VERSION "dbc-export 1 2025.20.8"

NS_ :

BS_:

BU_: ADSP APSB BB BMS CMP CP DAS DI DIF DIR DPB EPASTP EPASTS GTW ICR IDB OCS1P PM PMF PMR PTC RCM RCU TCU UI UIS VCLEFT VCSEC

BO_ 2047 GTW_carConfig: 8 GTW
 SG_ GTW_carConfigMultiplexer M : 0|8@1+ (1,0) [0|255] "" Vector__XXX
 SG_ GTW_deliveryStatus m1 : 8|1@1+ (1,0) [0|1] "" Vector__XXX
 SG_ GTW_cabinPTCHeaterType m1 : 10|1@1+ (1,0) [0|1] "" Vector__XXX
 SG_ GTW_rightHandDrive m1 : 11|1@1+ (1,0) [0|1] "" Vector__XXX
 SG_ GTW_rearLightType m1 : 12|2@1+ (1,0) [0|3] "" Vector__XXX
 SG_ GTW_headlamps m1 : 14|2@1+ (1,0) [0|3] "" Vector__XXX
 SG_ GTW_country m1 : 16|16@1+ (1,0) [0|65535] "" Vector__XXX
 SG_ GTW_tireType m1 : 32|6@1+ (1,0) [0|63] "" Vector__XXX
 SG_ GTW_roofGlassType m1 : 38|2@1+ (1,0) [0|3] "" Vector__XXX
 SG_ GTW_dasHw m1 : 40|3@1+ (1,0) [3|5] "" Vector__XXX
 SG_ GTW_brakeHWType m1 : 43|5@1+ (1,0) [0|31] "" Vector__XXX
 SG_ GTW_restraintsHardwareType m1 : 48|8@1+ (1,0) [0|255] "" Vector__XXX
 SG_ GTW_drivetrainType m1 : 56|4@1+ (1,0) [0|4] "" Vector__XXX
 SG_ GTW_radarHeaterType m1 : 60|3@1+ (1,0) [0|5] "" Vector__XXX
 SG_ GTW_exteriorTrimType m2 : 8|1@1+ (1,0) [0|1] "" Vector__XXX
 SG_ GTW_frontSeatHeaters m2 : 9|1@1+ (1,0) [0|1] "" Vector__XXX
 SG_ GTW_rearSeatHeaters m2 : 10|1@1+ (1,0) [0|1] "" Vector__XXX
 SG_ GTW_eCallAntennaHW m2 : 12|1@1+ (1,0) [0|1] "" Vector__XXX
 SG_ GTW_homelinkType m2 : 13|1@1+ (1,0) [0|1] "" Vector__XXX
 SG_ GTW_vdcType m2 : 14|1@1+ (1,0) [0|1] "" Vector__XXX
 SG_ GTW_memoryMirrors m2 : 17|1@1+ (1,0) [0|1] "" Vector__XXX
 SG_ GTW_powerLiftgateType m2 : 18|2@1+ (1,0) [0|2] "" Vector__XXX
 SG_ GTW_lumbarECUType m2 : 20|4@1+ (1,0) [0|15] "" Vector__XXX
 SG_ GTW_rearSeatHeaterType m2 : 24|2@1+ (1,0) [0|3] "" Vector__XXX
 SG_ GTW_auxParkLamps m2 : 26|2@1+ (1,0) [0|3] "" Vector__XXX
 SG_ GTW_interiorCabinRadarType m2 : 28|1@1+ (1,0) [0|1] "" Vector__XXX
 SG_ GTW_hvacPanelVaneType m2 : 29|1@1+ (1,0) [0|1] "" Vector__XXX
 SG_ GTW_intakeAirFilterType m2 : 30|2@1+ (1,0) [0|2] "" Vector__XXX
 SG_ GTW_eBuckConfig m2 : 32|1@1+ (1,0) [0|1] "" Vector__XXX
 SG_ GTW_steeringHeaterEnabled m2 : 33|1@1+ (1,0) [0|1] "" Vector__XXX
 SG_ GTW_activeHighBeam m2 : 34|1@1+ (1,0) [0|1] "" Vector__XXX
 SG_ GTW_airbagCutoffSwitch m2 : 35|1@1+ (1,0) [0|1] "" Vector__XXX
 SG_ GTW_intrusionSensorType m2 : 36|1@1+ (1,0) [0|1] "" Vector__XXX
 SG_ GTW_spoilerType m2 : 37|1@1+ (1,0) [0|1] "" Vector__XXX
 SG_ GTW_rearFogLamps m2 : 39|1@1+ (1,0) [0|1] "" Vector__XXX
 SG_ GTW_roofType m2 : 40|1@1+ (1,0) [0|1] "" Vector__XXX
 SG_ GTW_thirdRowSeatType m2 : 41|1@1+ (1,0) [0|1] "" Vector__XXX
 SG_ GTW_autopilot m2 : 42|3@1+ (1,0) [0|7] "" Vector__XXX
 SG_ GTW_superchargingAccess m2 : 45|2@1+ (1,0) [0|3] "" Vector__XXX
 SG_ GTW_exteriorColor m2 : 48|5@1+ (1,0) [0|31] "" Vector__XXX
 SG_ GTW_pedestrianWarningSound m2 : 53|2@1+ (1,0) [0|3] "" Vector__XXX
 SG_ GTW_steeringColumnUJointType m2 : 55|1@1+ (1,0) [0|1] "" Vector__XXX
 SG_ GTW_bPillarNFCParam m2 : 56|1@1+ (1,0) [0|1] "" Vector__XXX
 SG_ GTW_interiorLighting m2 : 57|3@1+ (1,0) [0|7] "" Vector__XXX
 SG_ GTW_headlightLevelerType m2 : 60|2@1+ (1,0) [0|3] "" Vector__XXX
 SG_ GTW_numberHVILNodes m2 : 62|2@1+ (1,0) [0|3] "" Vector__XXX
 SG_ GTW_mapRegion m3 : 8|4@1+ (1,0) [0|15] "" Vector__XXX
 SG_ GTW_performancePackage m3 : 12|3@1+ (1,0) [0|7] "" Vector__XXX
 SG_ GTW_chassisType m3 : 18|4@1+ (1,0) [0|15] "" Vector__XXX
 SG_ GTW_airSuspension m3 : 22|2@1+ (1,0) [0|3] "" Vector__XXX
 SG_ GTW_centerConsoleControllerType m3 : 24|2@1+ (1,0) [0|3] "" Vector__XXX
 SG_ GTW_autopilotCameraType m3 : 26|1@1+ (1,0) [0|1] "" Vector__XXX
 SG_ GTW_connectivityPackage m3 : 27|1@1+ (1,0) [0|1] "" Vector__XXX
 SG_ GTW_plcSupportType m3 : 28|2@1+ (1,0) [0|3] "" Vector__XXX
 SG_ GTW_packEnergy m3 : 32|5@1+ (1,0) [0|31] "" Vector__XXX
 SG_ GTW_frontSeatReclinerHardware m3 : 37|2@1+ (1,0) [0|3] "" Vector__XXX
 SG_ GTW_brakeLineSwitchType m3 : 39|1@1+ (1,0) [0|1] "" Vector__XXX
 SG_ GTW_espValveType m3 : 40|2@1+ (1,0) [0|3] "" Vector__XXX
 SG_ GTW_softRange m3 : 42|3@1+ (1,0) [0|7] "" Vector__XXX
 SG_ GTW_refrigerantType m3 : 45|2@1+ (1,0) [0|3] "" Vector__XXX
 SG_ GTW_wheelType m3 : 48|7@1+ (1,0) [0|127] "" Vector__XXX
 SG_ GTW_ptcControlMode m3 : 55|2@1+ (1,0) [0|3] "" Vector__XXX
 SG_ GTW_brakeActuationType m3 : 57|3@1+ (1,0) [0|4] "" Vector__XXX
 SG_ GTW_secondRowSeatType m3 : 60|3@1+ (1,0) [0|7] "" Vector__XXX
 SG_ GTW_secondRowSeatMotorType m3 : 63|1@1+ (1,0) [0|1] "" Vector__XXX
 SG_ GTW_birthday m4 : 8|32@1+ (1,0) [0|4294967295] "" Vector__XXX
 SG_ GTW_eCallEnabled m4 : 40|2@1+ (1,0) [0|3] "" Vector__XXX
 SG_ GTW_parkAssistECUType m4 : 42|2@1+ (1,0) [0|3] "" Vector__XXX
 SG_ GTW_passengerAirbagType m4 : 44|2@1+ (1,0) [0|3] "" Vector__XXX
 SG_ GTW_forwardRadarHw m4 : 46|2@1+ (1,0) [0|2] "" Vector__XXX
 SG_ GTW_frontSeatType m4 : 48|4@1+ (1,0) [0|15] "" Vector__XXX
 SG_ GTW_secondRowDisplayType m4 : 52|1@1+ (1,0) [0|1] "" Vector__XXX
 SG_ GTW_wirelessPhoneChargerType m4 : 53|2@1+ (1,0) [0|3] "" Vector__XXX
 SG_ GTW_ethernetTunerType m4 : 55|2@1+ (1,0) [0|3] "" Vector__XXX
 SG_ GTW_interiorTrimType m4 : 60|4@1+ (1,0) [0|15] "" Vector__XXX
 SG_ GTW_gloveboxUSBType m5 : 8|2@1+ (1,0) [0|3] "" Vector__XXX
 SG_ GTW_coolantPumpType m5 : 10|3@1+ (1,0) [0|7] "" Vector__XXX
 SG_ GTW_epblHwType m5 : 13|4@1+ (1,0) [0|15] "" Vector__XXX
 SG_ GTW_epbrHwType m5 : 17|4@1+ (1,0) [0|15] "" Vector__XXX
 SG_ GTW_blowerMotorType m5 : 21|2@1+ (1,0) [0|3] "" Vector__XXX
 SG_ GTW_rearLeftBLEEndpointParameter m5 : 23|1@1+ (1,0) [0|1] "" Vector__XXX
 SG_ GTW_frontUsbHubType m5 : 27|3@1+ (1,0) [0|5] "" Vector__XXX
 SG_ GTW_superManifoldType m5 : 30|2@1+ (1,0) [0|3] "" Vector__XXX
 SG_ GTW_rcmLocation m5 : 32|1@1+ (1,0) [0|1] "" Vector__XXX
 SG_ GTW_interiorCamFanType m5 : 33|2@1+ (1,0) [0|3] "" Vector__XXX
 SG_ GTW_interiorCamBeautyCoverType m5 : 35|2@1+ (1,0) [0|3] "" Vector__XXX
 SG_ GTW_sirenType m5 : 37|1@1+ (1,0) [0|1] "" Vector__XXX
 SG_ GTW_hornType m5 : 38|1@1+ (1,0) [0|1] "" Vector__XXX
 SG_ GTW_badgingVersion m5 : 40|1@1+ (1,0) [0|1] "" Vector__XXX
 SG_ GTW_steeringColumnMotorType m5 : 42|2@1+ (1,0) [0|3] "" Vector__XXX
 SG_ GTW_refrigACLineType m5 : 48|2@1+ (1,0) [0|3] "" Vector__XXX
 SG_ GTW_refrigFilterType m5 : 50|2@1+ (1,0) [0|3] "" Vector__XXX
 SG_ GTW_diBurnInType m5 : 52|1@1+ (1,0) [0|1] "" Vector__XXX
 SG_ GTW_specialBadgingType m5 : 53|2@1+ (1,0) [0|3] "" Vector__XXX
 SG_ GTW_chassisSubType m5 : 55|2@1+ (1,0) [0|3] "" Vector__XXX
 SG_ GTW_frontSeatVentilationType m5 : 57|1@1+ (1,0) [0|1] "" Vector__XXX
 SG_ GTW_towPackage m5 : 58|2@1+ (1,0) [0|3] "" Vector__XXX
 SG_ GTW_refrigLccType m5 : 60|1@1+ (1,0) [0|1] "" Vector__XXX
 SG_ GTW_caliperColorType m5 : 62|2@1+ (1,0) [0|3] "" Vector__XXX
 SG_ GTW_wiperMotorType m6 : 9|1@1+ (1,0) [0|1] "" Vector__XXX
 SG_ GTW_frontOverheadConsoleType m6 : 10|2@1+ (1,0) [0|3] "" Vector__XXX
 SG_ GTW_shifterType m6 : 12|1@1+ (1,0) [0|1] "" Vector__XXX
 SG_ GTW_compressorType m6 : 13|4@1+ (1,0) [0|15] "" Vector__XXX
 SG_ GTW_twelveVBatteryType m6 : 17|3@1+ (1,0) [0|7] "" Vector__XXX
 SG_ GTW_efuseSWConfig m6 : 20|3@1+ (1,0) [0|7] "" Vector__XXX
 SG_ GTW_tollCollectionModuleType m6 : 23|1@1+ (1,0) [0|1] "" Vector__XXX
 SG_ GTW_bleEndpointUpdateMethod m6 : 24|1@1+ (1,0) [0|1] "" Vector__XXX
 SG_ GTW_steeringWheelControllerType m6 : 25|3@1+ (1,0) [0|7] "" Vector__XXX
 SG_ GTW_frontSeatVentilationEnabled m6 : 28|1@1+ (1,0) [0|1] "" Vector__XXX
 SG_ GTW_gloveboxActuatorType m6 : 29|2@1+ (1,0) [0|3] "" Vector__XXX
 SG_ GTW_epasType m6 : 32|4@1+ (1,0) [0|11] "" Vector__XXX
 SG_ GTW_homologationRegionOverride m6 : 36|2@1+ (1,0) [0|3] "" Vector__XXX
 SG_ GTW_windowCommandsPermissionType m6 : 38|2@1+ (1,0) [0|3] "" Vector__XXX
 SG_ GTW_headlightStepperStallDetectM m6 : 42|1@1+ (1,0) [0|1] "" Vector__XXX
 SG_ GTW_rgbInteriorLightingEnabled m6 : 43|2@1+ (1,0) [0|3] "" Vector__XXX
 SG_ GTW_windshieldWiperHeaterType m6 : 45|1@1+ (1,0) [0|1] "" Vector__XXX
 SG_ GTW_driveInterfaceType m6 : 47|1@1+ (1,0) [0|1] "" Vector__XXX
 SG_ GTW_efficiencyPackage m6 : 49|6@1+ (1,0) [0|63] "" Vector__XXX
 SG_ GTW_visorLightType m6 : 55|1@1+ (1,0) [0|1] "" Vector__XXX
 SG_ GTW_gnssAntennaType m6 : 58|2@1+ (1,0) [0|3] "" Vector__XXX
 SG_ GTW_frontSeatHeatersEnabled m6 : 62|1@1+ (1,0) [0|1] "" Vector__XXX
 SG_ GTW_windshieldWiperHeaterEnabled m6 : 63|1@1+ (1,0) [0|1] "" Vector__XXX
 SG_ GTW_tcuType m7 : 8|1@1+ (1,0) [0|1] "" Vector__XXX
 SG_ GTW_fasciaType m7 : 9|4@1+ (1,0) [0|15] "" Vector__XXX
 SG_ GTW_powerSteeringColumn m7 : 13|1@1+ (1,0) [0|1] "" Vector__XXX
 SG_ GTW_frontSeatHeaterType m7 : 14|1@1+ (1,0) [0|1] "" Vector__XXX
 SG_ GTW_softPerformanceLimit m7 : 15|4@1+ (1,0) [0|15] "" Vector__XXX
 SG_ GTW_alcoholInterlockType m7 : 22|1@1+ (1,0) [0|1] "" Vector__XXX
 SG_ GTW_immersiveAudio m7 : 23|2@1+ (1,0) [0|3] "" Vector__XXX
 SG_ GTW_passengerOccupancySensorType m7 : 26|3@1+ (1,0) [0|7] "" Vector__XXX
 SG_ GTW_packPerformanceDeviation m7 : 30|3@1+ (1,0) [0|7] "" Vector__XXX
 SG_ GTW_frontFogLamps m7 : 35|1@1+ (1,0) [0|1] "" Vector__XXX
 SG_ GTW_driverOccupancySensorType m7 : 36|1@1+ (1,0) [0|1] "" Vector__XXX
 SG_ GTW_audioType m7 : 37|3@1+ (1,0) [0|7] "" Vector__XXX
 SG_ GTW_occupancyClassificationFeatu m7 : 42|1@1+ (1,0) [0|1] "" Vector__XXX
 SG_ GTW_domeLightType m7 : 47|2@1+ (1,0) [0|3] "" Vector__XXX
 SG_ GTW_tpmsType m7 : 49|2@1+ (1,0) [0|3] "" Vector__XXX
 SG_ GTW_authenticationEndpointLayout m7 : 52|3@1+ (1,0) [0|6] "" Vector__XXX
 SG_ GTW_socSleepOverride m7 : 57|2@1+ (1,0) [0|3] "" Vector__XXX
 SG_ GTW_r79BehaviorOverride m7 : 59|1@1+ (1,0) [0|1] "" Vector__XXX
 SG_ GTW_steeringHeaterType m7 : 60|3@1+ (1,0) [0|7] "" Vector__XXX
 SG_ GTW_sohRegulatoryStatus m8 : 10|1@1+ (1,0) [0|1] "" Vector__XXX
 SG_ GTW_m3yBusArchitecture m8 : 17|2@1+ (1,0) [0|3] "" Vector__XXX
 SG_ GTW_blindSpotIndicatorLightType m8 : 20|1@1+ (1,0) [0|1] "" Vector__XXX
 SG_ GTW_hvacCaseDoorType m8 : 28|1@1+ (1,0) [0|1] "" Vector__XXX
 SG_ GTW_occupancyDetectionSourceRequ m8 : 29|1@1+ (1,0) [0|1] "" Vector__XXX
 SG_ GTW_rduCableType m8 : 31|1@1+ (1,0) [0|1] "" Vector__XXX
 SG_ GTW_interiorCameraType m8 : 39|2@1+ (1,0) [0|2] "" Vector__XXX
 SG_ GTW_frontFasciaCameraType m8 : 41|2@1+ (1,0) [0|3] "" Vector__XXX

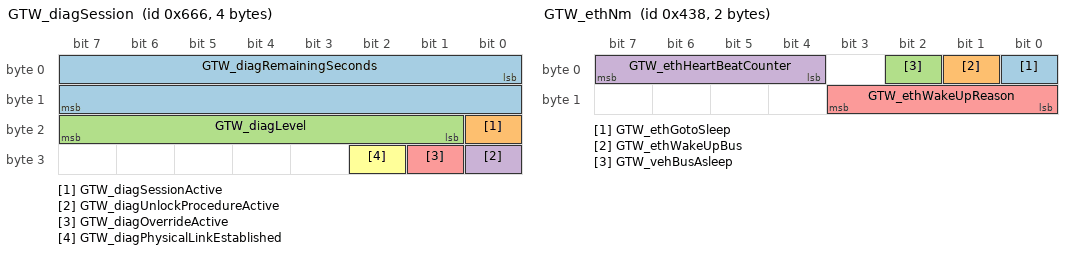
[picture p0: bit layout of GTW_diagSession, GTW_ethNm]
BO_ 1638 GTW_diagSession: 4 GTW
 SG_ GTW_diagRemainingSeconds : 0|16@1+ (1,0) [0|65535] "seconds" Vector__XXX
 SG_ GTW_diagSessionActive : 16|1@1+ (1,0) [0|1] "" Vector__XXX
 SG_ GTW_diagLevel : 17|7@1+ (1,0) [0|127] "" Vector__XXX
 SG_ GTW_diagUnlockProcedureActive : 24|1@1+ (1,0) [0|1] "" Vector__XXX
 SG_ GTW_diagOverrideActive : 25|1@1+ (1,0) [0|1] "" Vector__XXX
 SG_ GTW_diagPhysicalLinkEstablished : 26|1@1+ (1,0) [0|1] "" Vector__XXX

BO_ 1080 GTW_ethNm: 2 GTW
 SG_ GTW_ethGotoSleep : 0|1@1+ (1,0) [0|1] "" Vector__XXX
 SG_ GTW_ethWakeUpBus : 1|1@1+ (1,0) [0|1] "" Vector__XXX
 SG_ GTW_vehBusAsleep : 2|1@1+ (1,0) [0|1] "" Vector__XXX
 SG_ GTW_ethHeartBeatCounter : 4|4@1+ (1,0) [0|15] "" Vector__XXX
 SG_ GTW_ethWakeUpReason : 8|4@1+ (1,0) [0|15] "" Vector__XXX

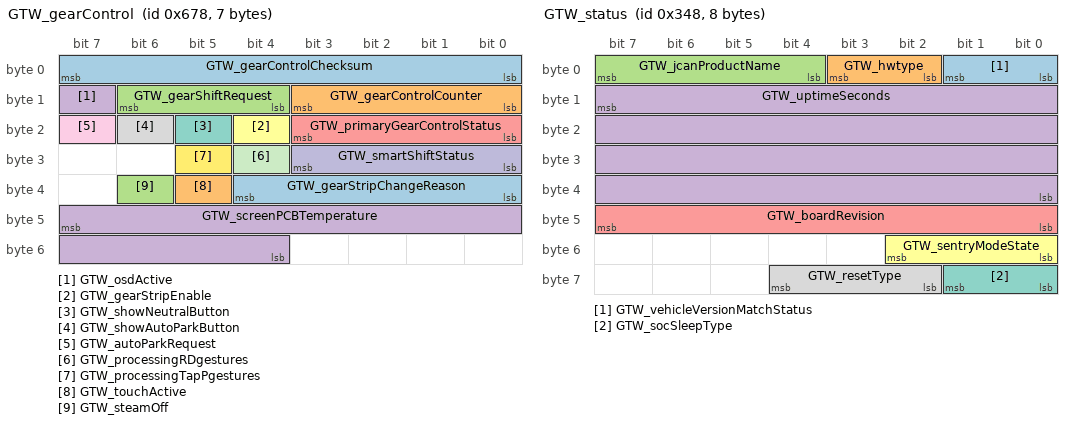
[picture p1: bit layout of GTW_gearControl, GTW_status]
BO_ 1656 GTW_gearControl: 7 GTW
 SG_ GTW_gearControlChecksum : 0|8@1+ (1,0) [0|255] "" Vector__XXX
 SG_ GTW_gearControlCounter : 8|4@1+ (1,0) [0|15] "" Vector__XXX
 SG_ GTW_gearShiftRequest : 12|3@1+ (1,0) [1|7] "" Vector__XXX
 SG_ GTW_osdActive : 15|1@1+ (1,0) [0|1] "" Vector__XXX
 SG_ GTW_primaryGearControlStatus : 16|4@1+ (1,0) [0|15] "" Vector__XXX
 SG_ GTW_gearStripEnable : 20|1@1+ (1,0) [0|1] "" Vector__XXX
 SG_ GTW_showNeutralButton : 21|1@1+ (1,0) [0|1] "" Vector__XXX
 SG_ GTW_showAutoParkButton : 22|1@1+ (1,0) [0|1] "" Vector__XXX
 SG_ GTW_autoParkRequest : 23|1@1+ (1,0) [0|1] "" Vector__XXX
 SG_ GTW_smartShiftStatus : 24|4@1+ (1,0) [1|15] "" Vector__XXX
 SG_ GTW_processingRDgestures : 28|1@1+ (1,0) [0|1] "" Vector__XXX
 SG_ GTW_processingTapPgestures : 29|1@1+ (1,0) [0|1] "" Vector__XXX
 SG_ GTW_gearStripChangeReason : 32|5@1+ (1,0) [1|31] "" Vector__XXX
 SG_ GTW_touchActive : 37|1@1+ (1,0) [0|1] "" Vector__XXX
 SG_ GTW_steamOff : 38|1@1+ (1,0) [0|1] "" Vector__XXX
 SG_ GTW_screenPCBTemperature : 47|12@0- (0.0625,0) [-128|127.875] "degC" Vector__XXX

BO_ 2033 GTW_hrl: 7 GTW
 SG_ GTW_hrlIndex M : 0|2@1+ (1,0) [0|3] "" Vector__XXX
 SG_ GTW_hrlState m2 : 2|1@1+ (1,0) [0|1] "" Vector__XXX
 SG_ GTW_hrlTriggerDuration m2 : 15|16@0+ (1,0) [0|65535] "seconds" Vector__XXX
 SG_ GTW_hrlTriggerType m2 : 24|4@1+ (1,0) [0|15] "" Vector__XXX
 SG_ GTW_hrlTriggerId m2 : 39|16@0+ (1,0) [0|65535] "" Vector__XXX
 SG_ GTW_hrlTriggerBus m2 : 53|3@1+ (1,0) [0|7] "" Vector__XXX

BO_ 60 GTW_info: 8 GTW
 SG_ GTW_infoIndex M : 0|8@1+ (1,0) [0|255] "" Vector__XXX
 SG_ GTW_buildType m10 : 8|3@1+ (1,0) [0|7] "" Vector__XXX
 SG_ GTW_hardwareId m10 : 32|16@1+ (1,0) [0|65535] "" Vector__XXX
 SG_ GTW_platformType m13 : 8|8@1+ (1,0) [0|255] "" Vector__XXX
 SG_ GTW_appCrc m13 : 32|32@1+ (1,0) [0|4294967295] "" Vector__XXX
 SG_ GTW_applicationGitHash m17 : 8|56@1+ (1,0) [0|7.20575940379e+16] "" Vector__XXX
 SG_ GTW_bootGitHash m18 : 8|56@1+ (1,0) [0|7.20575940379e+16] "" Vector__XXX

BO_ 1370 GTW_mismatchFault: 8 GTW
 SG_ GTW_mismatchFaultIndex M : 0|3@1+ (1,0) [0|7] "" Vector__XXX
 SG_ GTW_mismatchFaultChecksum : 3|8@1+ (1,0) [0|255] "" Vector__XXX
 SG_ GTW_mismatchFaultCounter : 11|4@1+ (1,0) [0|15] "" Vector__XXX
 SG_ GTW_GTWmismatchFault m1 : 15|1@1+ (1,0) [0|1] "" Vector__XXX
 SG_ GTW_BMSmismatchFault m1 : 16|1@1+ (1,0) [0|1] "" Vector__XXX
 SG_ GTW_APSmismatchFault m1 : 17|1@1+ (1,0) [0|1] "" Vector__XXX
 SG_ GTW_BLEEPCENTERmismatchFault m1 : 18|1@1+ (1,0) [0|1] "" Vector__XXX
 SG_ GTW_BLEEPLEFTmismatchFault m1 : 19|1@1+ (1,0) [0|1] "" Vector__XXX
 SG_ GTW_BLEEPREARmismatchFault m1 : 20|1@1+ (1,0) [0|1] "" Vector__XXX
 SG_ GTW_BLEEPRIGHTmismatchFault m1 : 21|1@1+ (1,0) [0|1] "" Vector__XXX
 SG_ GTW_CBCmismatchFault m1 : 22|1@1+ (1,0) [0|1] "" Vector__XXX
 SG_ GTW_CMPmismatchFault m1 : 23|1@1+ (1,0) [0|1] "" Vector__XXX
 SG_ GTW_CPmismatchFault m1 : 24|1@1+ (1,0) [0|1] "" Vector__XXX
 SG_ GTW_DIFmismatchFault m1 : 25|1@1+ (1,0) [0|1] "" Vector__XXX
 SG_ GTW_DIRmismatchFault m1 : 26|1@1+ (1,0) [0|1] "" Vector__XXX
 SG_ GTW_EPAS3PmismatchFault m1 : 27|1@1+ (1,0) [0|1] "" Vector__XXX
 SG_ GTW_EPAS3SmismatchFault m1 : 28|1@1+ (1,0) [0|1] "" Vector__XXX
 SG_ GTW_EPBLmismatchFault m1 : 29|1@1+ (1,0) [0|1] "" Vector__XXX
 SG_ GTW_EPBRmismatchFault m1 : 30|1@1+ (1,0) [0|1] "" Vector__XXX
 SG_ GTW_ESPCALmismatchFault m1 : 31|1@1+ (1,0) [0|1] "" Vector__XXX
 SG_ GTW_ESPmismatchFault m1 : 32|1@1+ (1,0) [0|1] "" Vector__XXX
 SG_ GTW_HCM3LmismatchFault m1 : 33|1@1+ (1,0) [0|1] "" Vector__XXX
 SG_ GTW_HCM3RmismatchFault m1 : 34|1@1+ (1,0) [0|1] "" Vector__XXX
 SG_ GTW_HCMLmismatchFault m1 : 35|1@1+ (1,0) [0|1] "" Vector__XXX
 SG_ GTW_HCMRmismatchFault m1 : 36|1@1+ (1,0) [0|1] "" Vector__XXX
 SG_ GTW_HVPmismatchFault m1 : 37|1@1+ (1,0) [0|1] "" Vector__XXX
 SG_ GTW_IBSTCALmismatchFault m1 : 38|1@1+ (1,0) [0|1] "" Vector__XXX
 SG_ GTW_IBSTmismatchFault m1 : 39|1@1+ (1,0) [0|1] "" Vector__XXX
 SG_ GTW_LVBMSmismatchFault m1 : 40|1@1+ (1,0) [0|1] "" Vector__XXX
 SG_ GTW_OCS1PmismatchFault m1 : 41|1@1+ (1,0) [0|1] "" Vector__XXX
 SG_ GTW_OPCFmismatchFault m1 : 42|1@1+ (1,0) [0|1] "" Vector__XXX
 SG_ GTW_OPCRmismatchFault m1 : 43|1@1+ (1,0) [0|1] "" Vector__XXX
 SG_ GTW_PARKmismatchFault m1 : 44|1@1+ (1,0) [0|1] "" Vector__XXX
 SG_ GTW_PCSCPU2mismatchFault m1 : 45|1@1+ (1,0) [0|1] "" Vector__XXX
 SG_ GTW_PCSmismatchFault m1 : 46|1@1+ (1,0) [0|1] "" Vector__XXX
 SG_ GTW_PMFmismatchFault m1 : 47|1@1+ (1,0) [0|1] "" Vector__XXX
 SG_ GTW_PMRmismatchFault m1 : 48|1@1+ (1,0) [0|1] "" Vector__XXX
 SG_ GTW_PTCmismatchFault m1 : 49|1@1+ (1,0) [0|1] "" Vector__XXX
 SG_ GTW_RCMCALmismatchFault m1 : 50|1@1+ (1,0) [0|1] "" Vector__XXX
 SG_ GTW_RCMmismatchFault m1 : 51|1@1+ (1,0) [0|1] "" Vector__XXX
 SG_ GTW_SCCMmismatchFault m1 : 52|1@1+ (1,0) [0|1] "" Vector__XXX
 SG_ GTW_SDCRmismatchFault m1 : 53|1@1+ (1,0) [0|1] "" Vector__XXX
 SG_ GTW_SWCmismatchFault m1 : 54|1@1+ (1,0) [0|1] "" Vector__XXX
 SG_ GTW_THSmismatchFault m1 : 55|1@1+ (1,0) [0|1] "" Vector__XXX
 SG_ GTW_VCFRONTmismatchFault m1 : 56|1@1+ (1,0) [0|1] "" Vector__XXX
 SG_ GTW_VCLEFTmismatchFault m1 : 57|1@1+ (1,0) [0|1] "" Vector__XXX
 SG_ GTW_VCRIGHTmismatchFault m1 : 58|1@1+ (1,0) [0|1] "" Vector__XXX
 SG_ GTW_VCSECmismatchFault m1 : 59|1@1+ (1,0) [0|1] "" Vector__XXX
 SG_ GTW_PMmismatchFault m1 : 60|1@1+ (1,0) [0|1] "" Vector__XXX

BO_ 840 GTW_status: 8 GTW
 SG_ GTW_vehicleVersionMatchStatus : 0|2@1+ (1,0) [0|3] "" Vector__XXX
 SG_ GTW_hwtype : 2|2@1+ (1,0) [1|3] "" Vector__XXX
 SG_ GTW_jcanProductName : 4|4@1+ (1,0) [1|15] "" Vector__XXX
 SG_ GTW_uptimeSeconds : 15|32@0+ (1,0) [0|4294967295] "s" Vector__XXX
 SG_ GTW_boardRevision : 40|8@1+ (1,0) [0|255] "" Vector__XXX
 SG_ GTW_sentryModeState : 48|3@1+ (1,0) [0|7] "" Vector__XXX
 SG_ GTW_socSleepType : 56|2@1+ (1,0) [1|3] "" Vector__XXX
 SG_ GTW_resetType : 58|3@1+ (1,0) [1|7] "" Vector__XXX

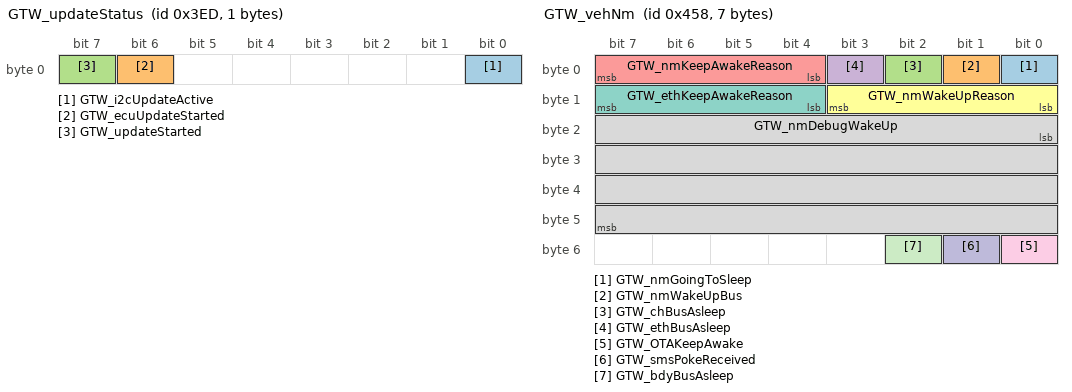
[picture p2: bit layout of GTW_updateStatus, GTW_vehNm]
BO_ 1005 GTW_updateStatus: 1 GTW
 SG_ GTW_i2cUpdateActive : 0|1@1+ (1,0) [0|1] "" Vector__XXX
 SG_ GTW_ecuUpdateStarted : 6|1@1+ (1,0) [0|1] "" Vector__XXX
 SG_ GTW_updateStarted : 7|1@1+ (1,0) [0|1] "" Vector__XXX

BO_ 1112 GTW_vehNm: 7 GTW
 SG_ GTW_nmGoingToSleep : 0|1@1+ (1,0) [0|1] "" Vector__XXX
 SG_ GTW_nmWakeUpBus : 1|1@1+ (1,0) [0|1] "" Vector__XXX
 SG_ GTW_chBusAsleep : 2|1@1+ (1,0) [0|1] "" Vector__XXX
 SG_ GTW_ethBusAsleep : 3|1@1+ (1,0) [0|1] "" Vector__XXX
 SG_ GTW_nmKeepAwakeReason : 4|4@1+ (1,0) [1|15] "" Vector__XXX
 SG_ GTW_nmWakeUpReason : 8|4@1+ (1,0) [0|15] "" Vector__XXX
 SG_ GTW_ethKeepAwakeReason : 12|4@1+ (1,0) [1|15] "" Vector__XXX
 SG_ GTW_nmDebugWakeUp : 16|32@1+ (1,0) [0|4294967295] "" Vector__XXX
 SG_ GTW_OTAKeepAwake : 48|1@1+ (1,0) [0|1] "" Vector__XXX
 SG_ GTW_smsPokeReceived : 49|1@1+ (1,0) [0|1] "" Vector__XXX
 SG_ GTW_bdyBusAsleep : 50|1@1+ (1,0) [0|1] "" Vector__XXX

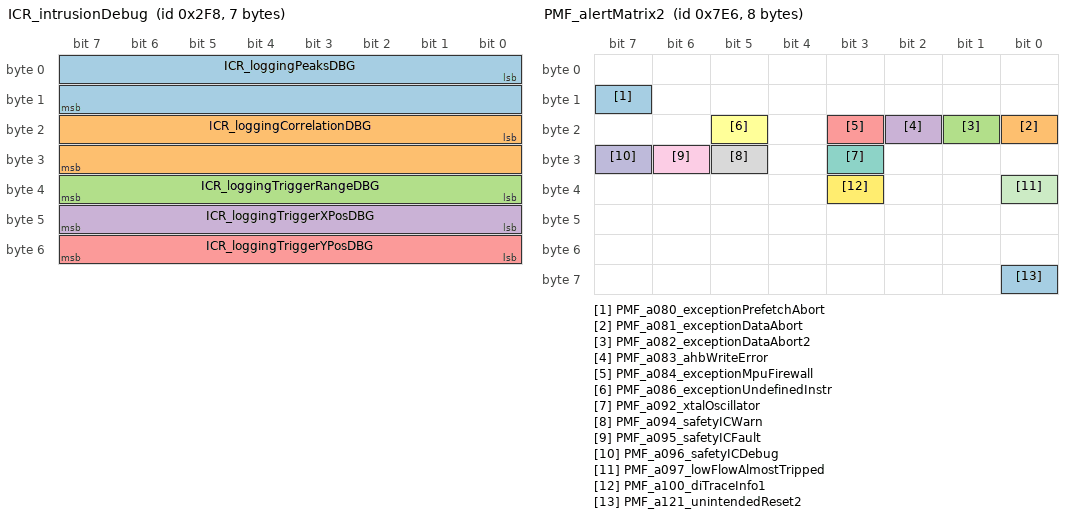
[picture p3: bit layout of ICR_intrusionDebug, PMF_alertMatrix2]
BO_ 760 ICR_intrusionDebug: 7 ICR
 SG_ ICR_loggingPeaksDBG : 0|16@1+ (1,0) [0|65535] "" Vector__XXX
 SG_ ICR_loggingCorrelationDBG : 16|16@1- (0.390625,0) [-12800|12799.609375] "%" Vector__XXX
 SG_ ICR_loggingTriggerRangeDBG : 32|8@1- (0.04,0) [-5.12|5.08] "m" Vector__XXX
 SG_ ICR_loggingTriggerXPosDBG : 40|8@1- (0.04,0) [-5.12|5.08] "m" Vector__XXX
 SG_ ICR_loggingTriggerYPosDBG : 48|8@1- (0.04,0) [-5.12|5.08] "m" Vector__XXX

BO_ 1470 IDB_alertLog: 8 IDB
 SG_ IDB_alertID M : 0|8@1+ (1,0) [0|255] "" Vector__XXX
 SG_ IDB_alertState : 15|1@1+ (1,0) [0|1] "" Vector__XXX
 SG_ IDB_a014_wheelSpeedSensorFreq m14 : 16|1@1+ (1,0) [0|1] "" Vector__XXX
 SG_ IDB_a014_wheelSpeedSensorPhase m14 : 17|1@1+ (1,0) [0|1] "" Vector__XXX
 SG_ IDB_a014_wheelSpeedSensorMisinst m14 : 18|1@1+ (1,0) [0|1] "" Vector__XXX
 SG_ IDB_a014_wheelSpeedSensorWrongEx m14 : 19|1@1+ (1,0) [0|1] "" Vector__XXX
 SG_ IDB_a014_wheelSpeedSensorSpeedJu m14 : 20|1@1+ (1,0) [0|1] "" Vector__XXX
 SG_ IDB_a014_wheelSpeedSensorSp_0001 m14 : 21|1@1+ (1,0) [0|1] "" Vector__XXX
 SG_ IDB_a014_wheelSpeedSensorAirGap m14 : 22|1@1+ (1,0) [0|1] "" Vector__XXX
 SG_ IDB_a014_wheelSpeedSensorBIST m14 : 23|1@1+ (1,0) [0|1] "" Vector__XXX
 SG_ IDB_a014_wheelSpeedSensorLeakage m14 : 24|1@1+ (1,0) [0|1] "" Vector__XXX
 SG_ IDB_a014_wheelSpeedSensorOverTem m14 : 25|1@1+ (1,0) [0|1] "" Vector__XXX
 SG_ IDB_a014_wheelSpeedSensorSh_0001 m14 : 26|1@1+ (1,0) [0|1] "" Vector__XXX
 SG_ IDB_a014_wheelSpeedSensorShortTo m14 : 27|1@1+ (1,0) [0|1] "" Vector__XXX
 SG_ IDB_a014_wheelSpeedSensorOpen m14 : 28|1@1+ (1,0) [0|1] "" Vector__XXX
 SG_ IDB_a015_wheelSpeedSensorFreq m15 : 16|1@1+ (1,0) [0|1] "" Vector__XXX
 SG_ IDB_a015_wheelSpeedSensorPhase m15 : 17|1@1+ (1,0) [0|1] "" Vector__XXX
 SG_ IDB_a015_wheelSpeedSensorMisinst m15 : 18|1@1+ (1,0) [0|1] "" Vector__XXX
 SG_ IDB_a015_wheelSpeedSensorWrongEx m15 : 19|1@1+ (1,0) [0|1] "" Vector__XXX
 SG_ IDB_a015_wheelSpeedSensorSpeedJu m15 : 20|1@1+ (1,0) [0|1] "" Vector__XXX
 SG_ IDB_a015_wheelSpeedSensorSp_0001 m15 : 21|1@1+ (1,0) [0|1] "" Vector__XXX
 SG_ IDB_a015_wheelSpeedSensorAirGap m15 : 22|1@1+ (1,0) [0|1] "" Vector__XXX
 SG_ IDB_a015_wheelSpeedSensorBIST m15 : 23|1@1+ (1,0) [0|1] "" Vector__XXX
 SG_ IDB_a015_wheelSpeedSensorLeakage m15 : 24|1@1+ (1,0) [0|1] "" Vector__XXX
 SG_ IDB_a015_wheelSpeedSensorOverTem m15 : 25|1@1+ (1,0) [0|1] "" Vector__XXX
 SG_ IDB_a015_wheelSpeedSensorSh_0001 m15 : 26|1@1+ (1,0) [0|1] "" Vector__XXX
 SG_ IDB_a015_wheelSpeedSensorShortTo m15 : 27|1@1+ (1,0) [0|1] "" Vector__XXX
 SG_ IDB_a015_wheelSpeedSensorOpen m15 : 28|1@1+ (1,0) [0|1] "" Vector__XXX
 SG_ IDB_a016_wheelSpeedSensorFreq m16 : 16|1@1+ (1,0) [0|1] "" Vector__XXX
 SG_ IDB_a016_wheelSpeedSensorPhase m16 : 17|1@1+ (1,0) [0|1] "" Vector__XXX
 SG_ IDB_a016_wheelSpeedSensorMisinst m16 : 18|1@1+ (1,0) [0|1] "" Vector__XXX
 SG_ IDB_a016_wheelSpeedSensorWrongEx m16 : 19|1@1+ (1,0) [0|1] "" Vector__XXX
 SG_ IDB_a016_wheelSpeedSensorSpeedJu m16 : 20|1@1+ (1,0) [0|1] "" Vector__XXX
 SG_ IDB_a016_wheelSpeedSensorSp_0001 m16 : 21|1@1+ (1,0) [0|1] "" Vector__XXX
 SG_ IDB_a016_wheelSpeedSensorAirGap m16 : 22|1@1+ (1,0) [0|1] "" Vector__XXX
 SG_ IDB_a016_wheelSpeedSensorBIST m16 : 23|1@1+ (1,0) [0|1] "" Vector__XXX
 SG_ IDB_a016_wheelSpeedSensorLeakage m16 : 24|1@1+ (1,0) [0|1] "" Vector__XXX
 SG_ IDB_a016_wheelSpeedSensorOverTem m16 : 25|1@1+ (1,0) [0|1] "" Vector__XXX
 SG_ IDB_a016_wheelSpeedSensorSh_0001 m16 : 26|1@1+ (1,0) [0|1] "" Vector__XXX
 SG_ IDB_a016_wheelSpeedSensorShortTo m16 : 27|1@1+ (1,0) [0|1] "" Vector__XXX
 SG_ IDB_a016_wheelSpeedSensorOpen m16 : 28|1@1+ (1,0) [0|1] "" Vector__XXX
 SG_ IDB_a017_wheelSpeedSensorFreq m17 : 16|1@1+ (1,0) [0|1] "" Vector__XXX
 SG_ IDB_a017_wheelSpeedSensorPhase m17 : 17|1@1+ (1,0) [0|1] "" Vector__XXX
 SG_ IDB_a017_wheelSpeedSensorMisinst m17 : 18|1@1+ (1,0) [0|1] "" Vector__XXX
 SG_ IDB_a017_wheelSpeedSensorWrongEx m17 : 19|1@1+ (1,0) [0|1] "" Vector__XXX
 SG_ IDB_a017_wheelSpeedSensorSpeedJu m17 : 20|1@1+ (1,0) [0|1] "" Vector__XXX
 SG_ IDB_a017_wheelSpeedSensorSp_0001 m17 : 21|1@1+ (1,0) [0|1] "" Vector__XXX
 SG_ IDB_a017_wheelSpeedSensorAirGap m17 : 22|1@1+ (1,0) [0|1] "" Vector__XXX
 SG_ IDB_a017_wheelSpeedSensorBIST m17 : 23|1@1+ (1,0) [0|1] "" Vector__XXX
 SG_ IDB_a017_wheelSpeedSensorLeakage m17 : 24|1@1+ (1,0) [0|1] "" Vector__XXX
 SG_ IDB_a017_wheelSpeedSensorOverTem m17 : 25|1@1+ (1,0) [0|1] "" Vector__XXX
 SG_ IDB_a017_wheelSpeedSensorSh_0001 m17 : 26|1@1+ (1,0) [0|1] "" Vector__XXX
 SG_ IDB_a017_wheelSpeedSensorShortTo m17 : 27|1@1+ (1,0) [0|1] "" Vector__XXX
 SG_ IDB_a017_wheelSpeedSensorOpen m17 : 28|1@1+ (1,0) [0|1] "" Vector__XXX
 SG_ IDB_a020_canSignalValidity m20 : 16|1@1+ (1,0) [0|1] "" Vector__XXX
 SG_ IDB_a020_signalValueCrosscheck m20 : 17|1@1+ (1,0) [0|1] "" Vector__XXX
 SG_ IDB_a030_primaryExternalCircuitL m30 : 16|1@1+ (1,0) [0|1] "" Vector__XXX
 SG_ IDB_a030_secondaryExternalCircui m30 : 17|1@1+ (1,0) [0|1] "" Vector__XXX
 SG_ IDB_a030_primaryChamberInternalL m30 : 18|1@1+ (1,0) [0|1] "" Vector__XXX
 SG_ IDB_a030_syncModeInternalLeakage m30 : 19|1@1+ (1,0) [0|1] "" Vector__XXX
 SG_ IDB_a030_secondaryChamberInterna m30 : 20|1@1+ (1,0) [0|1] "" Vector__XXX
 SG_ IDB_a030_masterCylinderInternalL m30 : 21|1@1+ (1,0) [0|1] "" Vector__XXX
 SG_ IDB_a060_validityOnChassisBus m60 : 16|1@1+ (1,0) [0|1] "" Vector__XXX
 SG_ IDB_a060_validityOnPartyBus m60 : 17|1@1+ (1,0) [0|1] "" Vector__XXX
 SG_ IDB_a061_validityOnChassisBus m61 : 16|1@1+ (1,0) [0|1] "" Vector__XXX
 SG_ IDB_a061_validityOnPartyBus m61 : 17|1@1+ (1,0) [0|1] "" Vector__XXX
 SG_ IDB_a062_validityOnChassisBus m62 : 16|1@1+ (1,0) [0|1] "" Vector__XXX
 SG_ IDB_a062_validityOnPartyBus m62 : 17|1@1+ (1,0) [0|1] "" Vector__XXX
 SG_ IDB_a063_validityOnChassisBus m63 : 16|1@1+ (1,0) [0|1] "" Vector__XXX
 SG_ IDB_a063_validityOnPartyBus m63 : 17|1@1+ (1,0) [0|1] "" Vector__XXX
 SG_ IDB_a064_validityOnChassisBus m64 : 16|1@1+ (1,0) [0|1] "" Vector__XXX
 SG_ IDB_a064_validityOnPartyBus m64 : 17|1@1+ (1,0) [0|1] "" Vector__XXX
 SG_ IDB_a065_validityOnChassisBus m65 : 16|1@1+ (1,0) [0|1] "" Vector__XXX
 SG_ IDB_a065_validityOnPartyBus m65 : 17|1@1+ (1,0) [0|1] "" Vector__XXX
 SG_ IDB_a106_qualifierValidity m106 : 16|1@1+ (1,0) [0|1] "" Vector__XXX
 SG_ IDB_a106_signalNotAvailable m106 : 17|1@1+ (1,0) [0|1] "" Vector__XXX
 SG_ IDB_a107_qualifierValidity m107 : 16|1@1+ (1,0) [0|1] "" Vector__XXX
 SG_ IDB_a107_signalNotAvailable m107 : 17|1@1+ (1,0) [0|1] "" Vector__XXX
 SG_ IDB_a112_qualifierValidity m112 : 16|1@1+ (1,0) [0|1] "" Vector__XXX
 SG_ IDB_a112_signalNotAvailable m112 : 17|1@1+ (1,0) [0|1] "" Vector__XXX
 SG_ IDB_a113_qualifierValidity m113 : 16|1@1+ (1,0) [0|1] "" Vector__XXX
 SG_ IDB_a113_signalNotAvailable m113 : 17|1@1+ (1,0) [0|1] "" Vector__XXX
 SG_ IDB_a114_qualifierValidity m114 : 16|1@1+ (1,0) [0|1] "" Vector__XXX
 SG_ IDB_a114_signalNotAvailable m114 : 17|1@1+ (1,0) [0|1] "" Vector__XXX
 SG_ IDB_a126_PMebrCmdStateValidity m126 : 16|1@1+ (1,0) [0|1] "" Vector__XXX
 SG_ IDB_a126_PMstate2Validity m126 : 17|1@1+ (1,0) [0|1] "" Vector__XXX
 SG_ IDB_a126_PMstate2Missing m126 : 18|1@1+ (1,0) [0|1] "" Vector__XXX
 SG_ IDB_a126_DIchassisControlValidit m126 : 19|1@1+ (1,0) [0|1] "" Vector__XXX
 SG_ IDB_a126_DIchassisControlMissing m126 : 20|1@1+ (1,0) [0|1] "" Vector__XXX
 SG_ IDB_a126_DIrequestActiveValidity m126 : 21|1@1+ (1,0) [0|1] "" Vector__XXX
 SG_ IDB_a129_validityOnChassisBus m129 : 16|1@1+ (1,0) [0|1] "" Vector__XXX
 SG_ IDB_a129_validityOnPartyBus m129 : 17|1@1+ (1,0) [0|1] "" Vector__XXX
 SG_ IDB_a130_PMbrakePedalCmdQFValidi m130 : 16|1@1+ (1,0) [0|1] "" Vector__XXX
 SG_ IDB_a130_PMstate2Validity m130 : 17|1@1+ (1,0) [0|1] "" Vector__XXX
 SG_ IDB_a130_PMstate2Missing m130 : 18|1@1+ (1,0) [0|1] "" Vector__XXX
 SG_ IDB_a130_DIbrakeCommandValidity m130 : 19|1@1+ (1,0) [0|1] "" Vector__XXX
 SG_ IDB_a130_DIbrakeCommandMissing m130 : 20|1@1+ (1,0) [0|1] "" Vector__XXX
 SG_ IDB_a130_DIbrakeTorqueCommandFul m130 : 21|1@1+ (1,0) [0|1] "" Vector__XXX
 SG_ IDB_a130_DIbrakeTorqueComma_0001 m130 : 22|1@1+ (1,0) [0|1] "" Vector__XXX
 SG_ IDB_a132_validityOnChassisBus m132 : 16|1@1+ (1,0) [0|1] "" Vector__XXX
 SG_ IDB_a132_validityOnPartyBus m132 : 17|1@1+ (1,0) [0|1] "" Vector__XXX

BO_ 983 IDB_alertMatrix: 8 IDB
 SG_ IDB_matrixIndex M : 0|4@1+ (1,0) [0|15] "" Vector__XXX
 SG_ IDB_a001_mcuGenericFault m0 : 4|1@1+ (1,0) [0|1] "" Vector__XXX
 SG_ IDB_a002_supplyOvervoltage m0 : 5|1@1+ (1,0) [0|1] "" Vector__XXX
 SG_ IDB_a003_supplyHardOvervoltage m0 : 6|1@1+ (1,0) [0|1] "" Vector__XXX
 SG_ IDB_a004_supplyUndervoltage m0 : 7|1@1+ (1,0) [0|1] "" Vector__XXX
 SG_ IDB_a005_supplyMidUndervoltage m0 : 8|1@1+ (1,0) [0|1] "" Vector__XXX
 SG_ IDB_a006_supplyHardUndervoltage m0 : 9|1@1+ (1,0) [0|1] "" Vector__XXX
 SG_ IDB_a007_wakeLineOpen m0 : 10|1@1+ (1,0) [0|1] "" Vector__XXX
 SG_ IDB_a008_motorPowerOpen m0 : 11|1@1+ (1,0) [0|1] "" Vector__XXX
 SG_ IDB_a009_asicBoostFault m0 : 12|1@1+ (1,0) [0|1] "" Vector__XXX
 SG_ IDB_a010_asicGenericFault m0 : 13|1@1+ (1,0) [0|1] "" Vector__XXX
 SG_ IDB_a011_solenoidValveFault m0 : 14|1@1+ (1,0) [0|1] "" Vector__XXX
 SG_ IDB_a012_motorGenericFault m0 : 15|1@1+ (1,0) [0|1] "" Vector__XXX
 SG_ IDB_a013_motorPosSensorFault m0 : 16|1@1+ (1,0) [0|1] "" Vector__XXX
 SG_ IDB_a014_FrLWSSFault m0 : 17|1@1+ (1,0) [0|1] "" Vector__XXX
 SG_ IDB_a015_FrRWSSFault m0 : 18|1@1+ (1,0) [0|1] "" Vector__XXX
 SG_ IDB_a016_ReLWSSFault m0 : 19|1@1+ (1,0) [0|1] "" Vector__XXX
 SG_ IDB_a017_ReRWSSFault m0 : 20|1@1+ (1,0) [0|1] "" Vector__XXX
 SG_ IDB_a018_WSSGenericFault m0 : 21|1@1+ (1,0) [0|1] "" Vector__XXX
 SG_ IDB_a019_pedalSensorFault m0 : 22|1@1+ (1,0) [0|1] "" Vector__XXX
 SG_ IDB_a020_RCUpedalTravelMismatch m0 : 23|1@1+ (1,0) [0|1] "" Vector__XXX
 SG_ IDB_a021_pedalSensorNotCal m0 : 24|1@1+ (1,0) [0|1] "" Vector__XXX
 SG_ IDB_a022_brakeFluidLow m0 : 25|1@1+ (1,0) [0|1] "" Vector__XXX
 SG_ IDB_a023_steeringImplausible m0 : 26|1@1+ (1,0) [0|1] "" Vector__XXX
 SG_ IDB_a024_yawImplausible m0 : 27|1@1+ (1,0) [0|1] "" Vector__XXX
 SG_ IDB_a025_ayImplausible m0 : 28|1@1+ (1,0) [0|1] "" Vector__XXX
 SG_ IDB_a026_axImplausible m0 : 29|1@1+ (1,0) [0|1] "" Vector__XXX
 SG_ IDB_a027_circuitPresSensorFault m0 : 30|1@1+ (1,0) [0|1] "" Vector__XXX
 SG_ IDB_a028_simPresSensorFault m0 : 31|1@1+ (1,0) [0|1] "" Vector__XXX
 SG_ IDB_a029_pressureSensNotCal m0 : 32|1@1+ (1,0) [0|1] "" Vector__XXX
 SG_ IDB_a030_fluidLeakDetected m0 : 33|1@1+ (1,0) [0|1] "" Vector__XXX
 SG_ IDB_a031_solenoidValveStuck m0 : 34|1@1+ (1,0) [0|1] "" Vector__XXX
 SG_ IDB_a032_motorSoftOverheat m0 : 35|1@1+ (1,0) [0|1] "" Vector__XXX
 SG_ IDB_a033_motorHardOverheat m0 : 36|1@1+ (1,0) [0|1] "" Vector__XXX
 SG_ IDB_a034_motorPositionSetFault m0 : 37|1@1+ (1,0) [0|1] "" Vector__XXX
 SG_ IDB_a035_motorStuck m0 : 38|1@1+ (1,0) [0|1] "" Vector__XXX
 SG_ IDB_a036_partyBusOff m0 : 39|1@1+ (1,0) [0|1] "" Vector__XXX
 SG_ IDB_a037_chassisBusOff m0 : 40|1@1+ (1,0) [0|1] "" Vector__XXX
 SG_ IDB_a038_motorInitFault m0 : 41|1@1+ (1,0) [0|1] "" Vector__XXX
 SG_ IDB_a039_absActive m0 : 42|1@1+ (1,0) [0|1] "" Vector__XXX
 SG_ IDB_a040_ebdActive m0 : 43|1@1+ (1,0) [0|1] "" Vector__XXX
 SG_ IDB_a041_vdcActive m0 : 44|1@1+ (1,0) [0|1] "" Vector__XXX
 SG_ IDB_a042_btcActive m0 : 45|1@1+ (1,0) [0|1] "" Vector__XXX
 SG_ IDB_a043_DItorquePathActive m0 : 46|1@1+ (1,0) [0|1] "" Vector__XXX
 SG_ IDB_a044_standstillSkidDetected m0 : 47|1@1+ (1,0) [0|1] "" Vector__XXX
 SG_ IDB_a045_panicBrakeAssistActive m0 : 48|1@1+ (1,0) [0|1] "" Vector__XXX
 SG_ IDB_a046_fadeCompensationActive m0 : 49|1@1+ (1,0) [0|1] "" Vector__XXX
 SG_ IDB_a047_brakeDiscWipeActive m0 : 50|1@1+ (1,0) [0|1] "" Vector__XXX
 SG_ IDB_a048_scmActive m0 : 51|1@1+ (1,0) [0|1] "" Vector__XXX
 SG_ IDB_a049_cdpActive m0 : 52|1@1+ (1,0) [0|1] "" Vector__XXX
 SG_ IDB_a050_absFaulted m0 : 53|1@1+ (1,0) [0|1] "" Vector__XXX
 SG_ IDB_a051_ebdFaulted m0 : 54|1@1+ (1,0) [0|1] "" Vector__XXX
 SG_ IDB_a052_vdcFaulted m0 : 55|1@1+ (1,0) [0|1] "" Vector__XXX
 SG_ IDB_a053_DItorquePathFaulted m0 : 56|1@1+ (1,0) [0|1] "" Vector__XXX
 SG_ IDB_a054_skidDetectionFaulted m0 : 57|1@1+ (1,0) [0|1] "" Vector__XXX
 SG_ IDB_a055_panicBrakeAssistFaulted m0 : 58|1@1+ (1,0) [0|1] "" Vector__XXX
 SG_ IDB_a056_fadeCompensationFaulted m0 : 59|1@1+ (1,0) [0|1] "" Vector__XXX
 SG_ IDB_a057_bdwRequestInvalid m0 : 60|1@1+ (1,0) [0|1] "" Vector__XXX
 SG_ IDB_a058_scmFaulted m0 : 61|1@1+ (1,0) [0|1] "" Vector__XXX
 SG_ IDB_a059_cdpFaulted m0 : 62|1@1+ (1,0) [0|1] "" Vector__XXX
 SG_ IDB_a060_RCUstatusDLC m0 : 63|1@1+ (1,0) [0|1] "" Vector__XXX
 SG_ IDB_a061_RCUstatusChecksum m1 : 4|1@1+ (1,0) [0|1] "" Vector__XXX
 SG_ IDB_a062_RCUstatusCounter m1 : 5|1@1+ (1,0) [0|1] "" Vector__XXX
 SG_ IDB_a063_RCUactuationDLC m1 : 6|1@1+ (1,0) [0|1] "" Vector__XXX
 SG_ IDB_a064_RCUactuationChecksum m1 : 7|1@1+ (1,0) [0|1] "" Vector__XXX
 SG_ IDB_a065_RCUactuationCounter m1 : 8|1@1+ (1,0) [0|1] "" Vector__XXX
 SG_ IDB_a066_DIFtorqueDLC m1 : 9|1@1+ (1,0) [0|1] "" Vector__XXX
 SG_ IDB_a067_DIFtorqueChecksum m1 : 10|1@1+ (1,0) [0|1] "" Vector__XXX
 SG_ IDB_a068_DIFtorqueCounter m1 : 11|1@1+ (1,0) [0|1] "" Vector__XXX
 SG_ IDB_a069_DIchassisControlDLC m1 : 12|1@1+ (1,0) [0|1] "" Vector__XXX
 SG_ IDB_a070_DIchassisControlChecksu m1 : 13|1@1+ (1,0) [0|1] "" Vector__XXX
 SG_ IDB_a071_DIchassisControlCounter m1 : 14|1@1+ (1,0) [0|1] "" Vector__XXX
 SG_ IDB_a072_DIsystemStatusDLC m1 : 15|1@1+ (1,0) [0|1] "" Vector__XXX
 SG_ IDB_a073_DIsystemStatusChecksum m1 : 16|1@1+ (1,0) [0|1] "" Vector__XXX
 SG_ IDB_a074_DIsystemStatusCounter m1 : 17|1@1+ (1,0) [0|1] "" Vector__XXX
 SG_ IDB_a075_DIRtorqueDLC m1 : 18|1@1+ (1,0) [0|1] "" Vector__XXX
 SG_ IDB_a076_DIRtorqueChecksum m1 : 19|1@1+ (1,0) [0|1] "" Vector__XXX
 SG_ IDB_a077_DIRtorqueCounter m1 : 20|1@1+ (1,0) [0|1] "" Vector__XXX
 SG_ IDB_a078_DIvdcLeftDLC m1 : 21|1@1+ (1,0) [0|1] "" Vector__XXX
 SG_ IDB_a079_DIvdcLeftChecksum m1 : 22|1@1+ (1,0) [0|1] "" Vector__XXX
 SG_ IDB_a080_DIvdcLeftCounter m1 : 23|1@1+ (1,0) [0|1] "" Vector__XXX
 SG_ IDB_a081_DIvdcRightDLC m1 : 24|1@1+ (1,0) [0|1] "" Vector__XXX
 SG_ IDB_a082_DIvdcRightChecksum m1 : 25|1@1+ (1,0) [0|1] "" Vector__XXX
 SG_ IDB_a083_DIvdcRightCounter m1 : 26|1@1+ (1,0) [0|1] "" Vector__XXX
 SG_ IDB_a084_EPAS3PsysStatusDLC m1 : 27|1@1+ (1,0) [0|1] "" Vector__XXX
 SG_ IDB_a085_EPAS3PsysStatusChecksum m1 : 28|1@1+ (1,0) [0|1] "" Vector__XXX
 SG_ IDB_a086_EPAS3PsysStatusCounter m1 : 29|1@1+ (1,0) [0|1] "" Vector__XXX
 SG_ IDB_a087_PMstate2DLC m1 : 30|1@1+ (1,0) [0|1] "" Vector__XXX
 SG_ IDB_a088_PMstate2Checksum m1 : 31|1@1+ (1,0) [0|1] "" Vector__XXX
 SG_ IDB_a089_PMstate2Counter m1 : 32|1@1+ (1,0) [0|1] "" Vector__XXX
 SG_ IDB_a090_RCMinertial1DLC m1 : 33|1@1+ (1,0) [0|1] "" Vector__XXX
 SG_ IDB_a091_RCMinertial1Checksum m1 : 34|1@1+ (1,0) [0|1] "" Vector__XXX
 SG_ IDB_a092_RCMinertial1Counter m1 : 35|1@1+ (1,0) [0|1] "" Vector__XXX
 SG_ IDB_a093_RCMinertial2DLC m1 : 36|1@1+ (1,0) [0|1] "" Vector__XXX
 SG_ IDB_a094_RCMinertial2Checksum m1 : 37|1@1+ (1,0) [0|1] "" Vector__XXX
 SG_ IDB_a095_RCMinertial2Counter m1 : 38|1@1+ (1,0) [0|1] "" Vector__XXX
 SG_ IDB_a096_VCFRONTLVPowerStateDLC m1 : 39|1@1+ (1,0) [0|1] "" Vector__XXX
 SG_ IDB_a097_VCFRONTLVPwrStChecksum m1 : 40|1@1+ (1,0) [0|1] "" Vector__XXX
 SG_ IDB_a098_VCFRONTLVPwrStCounter m1 : 41|1@1+ (1,0) [0|1] "" Vector__XXX
 SG_ IDB_a099_RCMcollisionDLC m1 : 42|1@1+ (1,0) [0|1] "" Vector__XXX
 SG_ IDB_a100_RCMcollisionChecksum m1 : 43|1@1+ (1,0) [0|1] "" Vector__XXX
 SG_ IDB_a101_RCMcollisionCounter m1 : 44|1@1+ (1,0) [0|1] "" Vector__XXX
 SG_ IDB_a102_bdwRequestActiveInvalid m1 : 45|1@1+ (1,0) [0|1] "" Vector__XXX
 SG_ IDB_a103_DIfullTorquePathFaulted m1 : 46|1@1+ (1,0) [0|1] "" Vector__XXX
 SG_ IDB_a104_DIaccelPosInvalid m1 : 47|1@1+ (1,0) [0|1] "" Vector__XXX
 SG_ IDB_a105_DIgearInvalid m1 : 48|1@1+ (1,0) [0|1] "" Vector__XXX
 SG_ IDB_a106_DIFtorqueInvalid m1 : 49|1@1+ (1,0) [0|1] "" Vector__XXX
 SG_ IDB_a107_DIRtorqueInvalid m1 : 50|1@1+ (1,0) [0|1] "" Vector__XXX
 SG_ IDB_a108_EPBstatusDLC m1 : 51|1@1+ (1,0) [0|1] "" Vector__XXX
 SG_ IDB_a109_BDWsignalInvalid m1 : 52|1@1+ (1,0) [0|1] "" Vector__XXX
 SG_ IDB_a110_EPBstatusCounter m1 : 53|1@1+ (1,0) [0|1] "" Vector__XXX
 SG_ IDB_a111_EPBstatusChecksum m1 : 54|1@1+ (1,0) [0|1] "" Vector__XXX
 SG_ IDB_a112_yawRateInvalid m1 : 55|1@1+ (1,0) [0|1] "" Vector__XXX
 SG_ IDB_a113_latAccelInvalid m1 : 56|1@1+ (1,0) [0|1] "" Vector__XXX
 SG_ IDB_a114_longAccelInvalid m1 : 57|1@1+ (1,0) [0|1] "" Vector__XXX
 SG_ IDB_a115_VCFRONTespLvStInvalid m1 : 58|1@1+ (1,0) [0|1] "" Vector__XXX
 SG_ IDB_a116_VCFRONTsensorsDLC m1 : 59|1@1+ (1,0) [0|1] "" Vector__XXX
 SG_ IDB_a117_VCLEFTepbmStatusDLC m1 : 60|1@1+ (1,0) [0|1] "" Vector__XXX
 SG_ IDB_a118_VCLEFTepbmStatusCounter m1 : 61|1@1+ (1,0) [0|1] "" Vector__XXX
 SG_ IDB_a119_VCLEFTepbmStatusChecksu m1 : 62|1@1+ (1,0) [0|1] "" Vector__XXX
 SG_ IDB_a120_EPAS3Pinvalid m1 : 63|1@1+ (1,0) [0|1] "" Vector__XXX
 SG_ IDB_a121_dynoModeActive m2 : 4|1@1+ (1,0) [0|1] "" Vector__XXX
 SG_ IDB_a122_DIFtorqueCommandInvalid m2 : 5|1@1+ (1,0) [0|1] "" Vector__XXX
 SG_ IDB_a123_DIRtorqueCommandInvalid m2 : 6|1@1+ (1,0) [0|1] "" Vector__XXX
 SG_ IDB_a124_VCFRONTtempInvalid m2 : 7|1@1+ (1,0) [0|1] "" Vector__XXX
 SG_ IDB_a125_PMvdcCmdStateInvalid m2 : 8|1@1+ (1,0) [0|1] "" Vector__XXX
 SG_ IDB_a126_DItorqueRequestInvalid m2 : 9|1@1+ (1,0) [0|1] "" Vector__XXX
 SG_ IDB_a127_brakeFluidLevelInvalid m2 : 10|1@1+ (1,0) [0|1] "" Vector__XXX
 SG_ IDB_a128_reserved1 m2 : 11|1@1+ (1,0) [0|1] "" Vector__XXX
 SG_ IDB_a129_RCUinputRodStrokeInvali m2 : 12|1@1+ (1,0) [0|1] "" Vector__XXX
 SG_ IDB_a130_DIfullTorqueRequestInva m2 : 13|1@1+ (1,0) [0|1] "" Vector__XXX
 SG_ IDB_a131_DIfullTorquePathActive m2 : 14|1@1+ (1,0) [0|1] "" Vector__XXX
 SG_ IDB_a132_RCUinputRodStrokeQFInva m2 : 15|1@1+ (1,0) [0|1] "" Vector__XXX
 SG_ IDB_a133_DIbrakeCommandDLC m2 : 16|1@1+ (1,0) [0|1] "" Vector__XXX
 SG_ IDB_a134_DIbrakeCommandCounter m2 : 17|1@1+ (1,0) [0|1] "" Vector__XXX
 SG_ IDB_a135_DIbrakeCommandChecksum m2 : 18|1@1+ (1,0) [0|1] "" Vector__XXX
 SG_ IDB_a136_RCUptsCalMissing m2 : 19|1@1+ (1,0) [0|1] "" Vector__XXX
 SG_ IDB_a137_VCLEFTcdpRequestInvalid m2 : 20|1@1+ (1,0) [0|1] "" Vector__XXX
 SG_ IDB_a138_DIbrakeTorqueCommandAnd m2 : 21|1@1+ (1,0) [0|1] "" Vector__XXX
 SG_ IDB_a139_DIbrakeTorqueCommandFul m2 : 22|1@1+ (1,0) [0|1] "" Vector__XXX
 SG_ IDB_a140_PMbrakePedalCmdQFInvali m2 : 23|1@1+ (1,0) [0|1] "" Vector__XXX
 SG_ IDB_a141_DIbrakeTorqueCommandFul m2 : 24|1@1+ (1,0) [0|1] "" Vector__XXX
 SG_ IDB_a142_PMebrCmdStateInvalid m2 : 25|1@1+ (1,0) [0|1] "" Vector__XXX
 SG_ IDB_a143_factoryModeActive m2 : 26|1@1+ (1,0) [0|1] "" Vector__XXX
 SG_ IDB_a144_hydraulicPushthroughAct m2 : 27|1@1+ (1,0) [0|1] "" Vector__XXX

BO_ 828 IDB_info: 8 IDB
 SG_ IDB_infoIndex M : 0|8@1+ (1,0) [0|255] "" Vector__XXX
 SG_ IDB_infoPcbaID m11 : 16|8@1+ (1,0) [0|255] "" Vector__XXX
 SG_ IDB_infoAssemblyID m11 : 24|8@1+ (1,0) [0|255] "" Vector__XXX
 SG_ IDB_infoUsageID m11 : 32|16@1+ (1,0) [0|65535] "" Vector__XXX
 SG_ IDB_infoSubUsageID m11 : 48|16@1+ (1,0) [0|65535] "" Vector__XXX

BO_ 1429 OCS1P_alertLog: 8 OCS1P
 SG_ OCS1P_alertID M : 0|8@1+ (1,0) [0|255] "" Vector__XXX
 SG_ OCS1P_alertState : 15|1@1+ (1,0) [0|1] "" Vector__XXX
 SG_ OCS1P_a121_sandwichFreq m121 : 16|32@1+ (1,0) [0|4294967295] "" Vector__XXX
 SG_ OCS1P_a122_sandwichFreq m122 : 16|32@1+ (1,0) [0|4294967295] "" Vector__XXX
 SG_ OCS1P_a123_sandwichFreq m123 : 16|32@1+ (1,0) [0|4294967295] "" Vector__XXX
 SG_ OCS1P_a124_cushionSelfFreq m124 : 16|32@1+ (1,0) [0|4294967295] "" Vector__XXX
 SG_ OCS1P_a125_cushionSelfFreq m125 : 16|32@1+ (1,0) [0|4294967295] "" Vector__XXX
 SG_ OCS1P_a126_cushionSelfFreq m126 : 16|32@1+ (1,0) [0|4294967295] "" Vector__XXX
 SG_ OCS1P_a127_seatbackSelfFreq m127 : 16|32@1+ (1,0) [0|4294967295] "" Vector__XXX
 SG_ OCS1P_a128_seatbackSelfFreq m128 : 16|32@1+ (1,0) [0|4294967295] "" Vector__XXX
 SG_ OCS1P_a129_seatbackSelfFreq m129 : 16|32@1+ (1,0) [0|4294967295] "" Vector__XXX
 SG_ OCS1P_a130_sandwichNoCalib m130 : 16|1@1+ (1,0) [0|1] "" Vector__XXX
 SG_ OCS1P_a131_cushionSelfNoCalib m131 : 16|1@1+ (1,0) [0|1] "" Vector__XXX
 SG_ OCS1P_a132_seatbackSelfNoCalib m132 : 16|1@1+ (1,0) [0|1] "" Vector__XXX
 SG_ OCS1P_a133_sandwichBadCalib m133 : 16|1@1+ (1,0) [0|1] "" Vector__XXX
 SG_ OCS1P_a134_uninitializedCalib m134 : 16|1@1+ (1,0) [0|1] "" Vector__XXX
 SG_ OCS1P_a135_tempNoCalib m135 : 16|1@1+ (1,0) [0|1] "" Vector__XXX
 SG_ OCS1P_a140_tempInvalidCalib m140 : 16|1@1+ (1,0) [0|1] "" Vector__XXX
 SG_ OCS1P_a141_humidityInvalidCalib m141 : 16|1@1+ (1,0) [0|1] "" Vector__XXX
 SG_ OCS1P_a142_tempHumidityInvalid m142 : 16|1@1+ (1,0) [0|1] "" Vector__XXX
 SG_ OCS1P_a143_mismatchPassAirbag m143 : 16|1@1+ (1,0) [0|1] "" Vector__XXX
 SG_ OCS1P_a144_mismatchCarRegion m144 : 16|1@1+ (1,0) [0|1] "" Vector__XXX

BO_ 767 OCS1P_alertMatrix: 8 OCS1P
 SG_ OCS1P_matrixIndex M : 0|4@1+ (1,0) [0|15] "" Vector__XXX
 SG_ OCS1P_w015_NVMMAlert m0 : 18|1@1+ (1,0) [0|1] "" Vector__XXX
 SG_ OCS1P_w121_sandwichOpen m2 : 4|1@1+ (1,0) [0|1] "" Vector__XXX
 SG_ OCS1P_w122_sandwichLow m2 : 5|1@1+ (1,0) [0|1] "" Vector__XXX
 SG_ OCS1P_w123_sandwichShort m2 : 6|1@1+ (1,0) [0|1] "" Vector__XXX
 SG_ OCS1P_w124_cushionSelfOpen m2 : 7|1@1+ (1,0) [0|1] "" Vector__XXX
 SG_ OCS1P_w125_cushionSelfLow m2 : 8|1@1+ (1,0) [0|1] "" Vector__XXX
 SG_ OCS1P_w126_cushionSelfShort m2 : 9|1@1+ (1,0) [0|1] "" Vector__XXX
 SG_ OCS1P_w127_seatbackSelfOpen m2 : 10|1@1+ (1,0) [0|1] "" Vector__XXX
 SG_ OCS1P_w128_seatbackSelfLow m2 : 11|1@1+ (1,0) [0|1] "" Vector__XXX
 SG_ OCS1P_w129_seatbackSelfShort m2 : 12|1@1+ (1,0) [0|1] "" Vector__XXX
 SG_ OCS1P_w130_sandwichNoCalib m2 : 13|1@1+ (1,0) [0|1] "" Vector__XXX
 SG_ OCS1P_w131_cushionSelfNoCalib m2 : 14|1@1+ (1,0) [0|1] "" Vector__XXX
 SG_ OCS1P_w132_seatbackSelfNoCalib m2 : 15|1@1+ (1,0) [0|1] "" Vector__XXX
 SG_ OCS1P_w133_sandwichBadCalib m2 : 16|1@1+ (1,0) [0|1] "" Vector__XXX
 SG_ OCS1P_w134_uninitializedCalib m2 : 17|1@1+ (1,0) [0|1] "" Vector__XXX
 SG_ OCS1P_w135_tempNoCalib m2 : 18|1@1+ (1,0) [0|1] "" Vector__XXX
 SG_ OCS1P_w136_cushionSelfDutyLow m2 : 19|1@1+ (1,0) [0|1] "" Vector__XXX
 SG_ OCS1P_w137_cushionSelfDutyHigh m2 : 20|1@1+ (1,0) [0|1] "" Vector__XXX
 SG_ OCS1P_w138_seatbackSelfDutyLow m2 : 21|1@1+ (1,0) [0|1] "" Vector__XXX
 SG_ OCS1P_w139_seatbackSelfDutyHigh m2 : 22|1@1+ (1,0) [0|1] "" Vector__XXX
 SG_ OCS1P_w140_tempInvalidCalib m2 : 23|1@1+ (1,0) [0|1] "" Vector__XXX
 SG_ OCS1P_w141_humidityInvalidCalib m2 : 24|1@1+ (1,0) [0|1] "" Vector__XXX
 SG_ OCS1P_w142_tempHumidityInvalid m2 : 25|1@1+ (1,0) [0|1] "" Vector__XXX
 SG_ OCS1P_w143_mismatchPassAirbag m2 : 26|1@1+ (1,0) [0|1] "" Vector__XXX
 SG_ OCS1P_w144_mismatchCarRegion m2 : 27|1@1+ (1,0) [0|1] "" Vector__XXX
 SG_ OCS1P_w145_rebaselineTriggered m2 : 28|1@1+ (1,0) [0|1] "" Vector__XXX
 SG_ OCS1P_w148_classificationMismatc m2 : 31|1@1+ (1,0) [0|1] "" Vector__XXX
 SG_ OCS1P_w150_rbEntryTriggered m2 : 33|1@1+ (1,0) [0|1] "" Vector__XXX
 SG_ OCS1P_w151_rbEntryExited m2 : 34|1@1+ (1,0) [0|1] "" Vector__XXX
 SG_ OCS1P_w152_rbExit1Triggered m2 : 35|1@1+ (1,0) [0|1] "" Vector__XXX
 SG_ OCS1P_w153_rbExit1Exited m2 : 36|1@1+ (1,0) [0|1] "" Vector__XXX
 SG_ OCS1P_w154_rbExit2Exited1 m2 : 37|1@1+ (1,0) [0|1] "" Vector__XXX
 SG_ OCS1P_w155_rbExit2Exited2 m2 : 38|1@1+ (1,0) [0|1] "" Vector__XXX

BO_ 766 OCS1P_info: 8 OCS1P
 SG_ OCS1P_infoIndex M : 0|8@1+ (1,0) [0|255] "" Vector__XXX
 SG_ OCS1P_infoBuildType m10 : 8|8@1+ (1,0) [0|255] "" Vector__XXX
 SG_ OCS1P_infoBuildConfigID m10 : 16|16@1+ (1,0) [0|65535] "" Vector__XXX
 SG_ OCS1P_infoHardwareID m10 : 32|16@1+ (1,0) [0|65535] "" Vector__XXX
 SG_ OCS1P_infoComponentID m10 : 48|16@1+ (1,0) [0|65535] "" Vector__XXX
 SG_ OCS1P_infoPcbaID m11 : 16|8@1+ (1,0) [0|255] "" Vector__XXX
 SG_ OCS1P_infoAssemblyID m11 : 24|8@1+ (1,0) [0|255] "" Vector__XXX
 SG_ OCS1P_infoUsageID m11 : 32|16@1+ (1,0) [0|65535] "" Vector__XXX
 SG_ OCS1P_infoSubUsageID m11 : 48|16@1+ (1,0) [0|65535] "" Vector__XXX
 SG_ OCS1P_infoApplicationCRC m13 : 32|32@1+ (1,0) [0|4294967295] "" Vector__XXX
 SG_ OCS1P_infoBootSvnRev m14 : 8|24@1+ (1,0) [0|16777215] "" Vector__XXX
 SG_ OCS1P_infoAppGitHashBytes m17 : 8|56@1+ (1,0) [0|7.20575940379e+16] "" Vector__XXX
 SG_ OCS1P_infoBootGitHashBytes m18 : 8|56@1+ (1,0) [0|7.20575940379e+16] "" Vector__XXX
 SG_ OCS1P_infoPlatformType m19 : 8|8@1+ (1,0) [0|255] "" Vector__XXX
 SG_ OCS1P_infoBootUdsProtoVersion m20 : 8|8@1+ (1,0) [0|255] "" Vector__XXX
 SG_ OCS1P_infoBootloaderCRC m20 : 32|32@1+ (1,0) [0|4294967295] "" Vector__XXX

BO_ 771 OCS1P_status: 8 OCS1P
 SG_ OCS1P_occupantClassification : 0|8@1+ (1,0) [0|254] "" Vector__XXX
 SG_ OCS1P_occupantClassificationQF : 8|1@1+ (1,0) [0|1] "" Vector__XXX
 SG_ OCS1P_occupiedState : 9|2@1+ (1,0) [0|2] "" Vector__XXX
 SG_ OCS1P_triggerSnapshot : 11|5@1+ (1,0) [0|31] "" Vector__XXX
 SG_ OCS1P_occupantClassificationRaw : 16|3@1+ (1,0) [0|6] "" Vector__XXX
 SG_ OCS1P_occupantClassificationSelf : 19|3@1+ (1,0) [0|6] "" Vector__XXX
 SG_ OCS1P_occupantClassificationRawC : 22|3@1+ (1,0) [0|6] "" Vector__XXX
 SG_ OCS1P_occupantClassificationCap : 25|3@1+ (1,0) [0|6] "" Vector__XXX
 SG_ OCS1P_classificationHeld : 30|1@1+ (1,0) [0|1] "" Vector__XXX
 SG_ OCS1P_cushionStable : 31|1@1+ (1,0) [0|1] "" Vector__XXX
 SG_ OCS1P_classificationExtHold : 32|1@1+ (1,0) [0|1] "" Vector__XXX
 SG_ OCS1P_classificationHoldState : 33|3@1+ (1,0) [0|7] "" Vector__XXX
 SG_ OCS1P_classificationVariant : 36|3@1+ (1,0) [0|7] "" Vector__XXX
 SG_ OCS1P_sandwichDisabled : 39|1@1+ (1,0) [0|1] "" Vector__XXX
 SG_ OCS1P_noSandwichType : 40|2@1+ (1,0) [0|3] "" Vector__XXX
 SG_ OCS1P_sandwichBoundaryType : 42|1@1+ (1,0) [0|1] "" Vector__XXX
 SG_ OCS1P_sbrBoundaryType : 43|1@1+ (1,0) [0|1] "" Vector__XXX
 SG_ OCS1P_occupiedStateCap : 45|2@1+ (1,0) [0|2] "" Vector__XXX
 SG_ OCS1P_seatbackStable : 47|1@1+ (1,0) [0|1] "" Vector__XXX
 SG_ OCS1P_sandwichStable : 48|1@1+ (1,0) [0|1] "" Vector__XXX
 SG_ OCS1P_cushionStableCap : 49|1@1+ (1,0) [0|1] "" Vector__XXX
 SG_ OCS1P_seatbackStableCap : 50|1@1+ (1,0) [0|1] "" Vector__XXX
 SG_ OCS1P_classificationHeldCap : 51|1@1+ (1,0) [0|1] "" Vector__XXX
 SG_ OCS1P_statusCounter : 52|4@1+ (1,0) [0|15] "" Vector__XXX
 SG_ OCS1P_statusChecksum : 56|8@1+ (1,0) [0|255] "" Vector__XXX

BO_ 772 PMF_alertMatrix1: 8 PMF
 SG_ PMF_a001_absoluteTorque : 0|1@1+ (1,0) [0|1] "" Vector__XXX
 SG_ PMF_a002_excessiveAccelTorque : 1|1@1+ (1,0) [0|1] "" Vector__XXX
 SG_ PMF_a003_excessiveReversalTorque : 2|1@1+ (1,0) [0|1] "" Vector__XXX
 SG_ PMF_a004_excessiveDecelTorque : 3|1@1+ (1,0) [0|1] "" Vector__XXX
 SG_ PMF_a005_torqueInNeutralOrPark : 4|1@1+ (1,0) [0|1] "" Vector__XXX
 SG_ PMF_a006_underTorqueCheck : 5|1@1+ (1,0) [0|1] "" Vector__XXX
 SG_ PMF_a008_memoryError : 7|1@1+ (1,0) [0|1] "" Vector__XXX
 SG_ PMF_a010_diMIA : 9|1@1+ (1,0) [0|1] "" Vector__XXX
 SG_ PMF_a011_phaseCurrentIrrational : 10|1@1+ (1,0) [0|1] "" Vector__XXX
 SG_ PMF_a012_canDataBusA : 11|1@1+ (1,0) [0|1] "" Vector__XXX
 SG_ PMF_a013_canHardwareBusA : 12|1@1+ (1,0) [0|1] "" Vector__XXX
 SG_ PMF_a017_brakeMIA : 16|1@1+ (1,0) [0|1] "" Vector__XXX
 SG_ PMF_a018_encoderIrrational : 17|1@1+ (1,0) [0|1] "" Vector__XXX
 SG_ PMF_a019_statorTempIrrational : 18|1@1+ (1,0) [0|1] "" Vector__XXX
 SG_ PMF_a025_unintendedReset : 24|1@1+ (1,0) [0|1] "" Vector__XXX
 SG_ PMF_a026_diHeartBeatMIA : 25|1@1+ (1,0) [0|1] "" Vector__XXX
 SG_ PMF_a027_torqueEstimationOutOfBo : 26|1@1+ (1,0) [0|1] "" Vector__XXX
 SG_ PMF_a028_torqueCmdError : 27|1@1+ (1,0) [0|1] "" Vector__XXX
 SG_ PMF_a031_highStackUsage : 30|1@1+ (1,0) [0|1] "" Vector__XXX
 SG_ PMF_a032_registerConfigError : 31|1@1+ (1,0) [0|1] "" Vector__XXX
 SG_ PMF_a033_selfTest : 32|1@1+ (1,0) [0|1] "" Vector__XXX
 SG_ PMF_a034_trqCrossCheck : 33|1@1+ (1,0) [0|1] "" Vector__XXX
 SG_ PMF_a035_udsTransactionInitiated : 34|1@1+ (1,0) [0|1] "" Vector__XXX
 SG_ PMF_a036_preWatchdog : 35|1@1+ (1,0) [0|1] "" Vector__XXX
 SG_ PMF_a037_hvpMIA : 36|1@1+ (1,0) [0|1] "" Vector__XXX
 SG_ PMF_a039_disMIA : 38|1@1+ (1,0) [0|1] "" Vector__XXX
 SG_ PMF_a040_pmMIA : 39|1@1+ (1,0) [0|1] "" Vector__XXX
 SG_ PMF_a042_gtwMIA : 41|1@1+ (1,0) [0|1] "" Vector__XXX
 SG_ PMF_a045_motorMovementDetected : 44|1@1+ (1,0) [0|1] "" Vector__XXX
 SG_ PMF_a053_vcfrontMIA : 52|1@1+ (1,0) [0|1] "" Vector__XXX
 SG_ PMF_a054_uiMIA : 53|1@1+ (1,0) [0|1] "" Vector__XXX
 SG_ PMF_a055_resolver : 54|1@1+ (1,0) [0|1] "" Vector__XXX
 SG_ PMF_a056_canHardwareBusB : 55|1@1+ (1,0) [0|1] "" Vector__XXX
 SG_ PMF_a057_canDataBusB : 56|1@1+ (1,0) [0|1] "" Vector__XXX
 SG_ PMF_a058_measuredHvilCurrentFroz : 57|1@1+ (1,0) [0|1] "" Vector__XXX
 SG_ PMF_a061_DIPMVersionMismatch : 60|1@1+ (1,0) [0|1] "" Vector__XXX
 SG_ PMF_a062_eccError : 61|1@1+ (1,0) [0|1] "" Vector__XXX
 SG_ PMF_a064_torqueIntervention : 63|1@1+ (1,0) [0|1] "" Vector__XXX

BO_ 2022 PMF_alertMatrix2: 8 PMF
 SG_ PMF_a080_exceptionPrefetchAbort : 15|1@1+ (1,0) [0|1] "" Vector__XXX
 SG_ PMF_a081_exceptionDataAbort : 16|1@1+ (1,0) [0|1] "" Vector__XXX
 SG_ PMF_a082_exceptionDataAbort2 : 17|1@1+ (1,0) [0|1] "" Vector__XXX
 SG_ PMF_a083_ahbWriteError : 18|1@1+ (1,0) [0|1] "" Vector__XXX
 SG_ PMF_a084_exceptionMpuFirewall : 19|1@1+ (1,0) [0|1] "" Vector__XXX
 SG_ PMF_a086_exceptionUndefinedInstr : 21|1@1+ (1,0) [0|1] "" Vector__XXX
 SG_ PMF_a092_xtalOscillator : 27|1@1+ (1,0) [0|1] "" Vector__XXX
 SG_ PMF_a094_safetyICWarn : 29|1@1+ (1,0) [0|1] "" Vector__XXX
 SG_ PMF_a095_safetyICFault : 30|1@1+ (1,0) [0|1] "" Vector__XXX
 SG_ PMF_a096_safetyICDebug : 31|1@1+ (1,0) [0|1] "" Vector__XXX
 SG_ PMF_a097_lowFlowAlmostTripped : 32|1@1+ (1,0) [0|1] "" Vector__XXX
 SG_ PMF_a100_diTraceInfo1 : 35|1@1+ (1,0) [0|1] "" Vector__XXX
 SG_ PMF_a121_unintendedReset2 : 56|1@1+ (1,0) [0|1] "" Vector__XXX

BO_ 902 PMR_alertMatrix1: 8 PMR
 SG_ PMR_a001_absoluteTorque : 0|1@1+ (1,0) [0|1] "" Vector__XXX
 SG_ PMR_a002_excessiveAccelTorque : 1|1@1+ (1,0) [0|1] "" Vector__XXX
 SG_ PMR_a003_excessiveReversalTorque : 2|1@1+ (1,0) [0|1] "" Vector__XXX
 SG_ PMR_a004_excessiveDecelTorque : 3|1@1+ (1,0) [0|1] "" Vector__XXX
 SG_ PMR_a005_torqueInNeutralOrPark : 4|1@1+ (1,0) [0|1] "" Vector__XXX
 SG_ PMR_a006_underTorqueCheck : 5|1@1+ (1,0) [0|1] "" Vector__XXX
 SG_ PMR_a008_memoryError : 7|1@1+ (1,0) [0|1] "" Vector__XXX
 SG_ PMR_a010_diMIA : 9|1@1+ (1,0) [0|1] "" Vector__XXX
 SG_ PMR_a011_phaseCurrentIrrational : 10|1@1+ (1,0) [0|1] "" Vector__XXX
 SG_ PMR_a012_canDataBusA : 11|1@1+ (1,0) [0|1] "" Vector__XXX
 SG_ PMR_a013_canHardwareBusA : 12|1@1+ (1,0) [0|1] "" Vector__XXX
 SG_ PMR_a017_brakeMIA : 16|1@1+ (1,0) [0|1] "" Vector__XXX
 SG_ PMR_a018_encoderIrrational : 17|1@1+ (1,0) [0|1] "" Vector__XXX
 SG_ PMR_a019_statorTempIrrational : 18|1@1+ (1,0) [0|1] "" Vector__XXX
 SG_ PMR_a025_unintendedReset : 24|1@1+ (1,0) [0|1] "" Vector__XXX
 SG_ PMR_a026_diHeartBeatMIA : 25|1@1+ (1,0) [0|1] "" Vector__XXX
 SG_ PMR_a027_torqueEstimationOutOfBo : 26|1@1+ (1,0) [0|1] "" Vector__XXX
 SG_ PMR_a028_torqueCmdError : 27|1@1+ (1,0) [0|1] "" Vector__XXX
 SG_ PMR_a031_highStackUsage : 30|1@1+ (1,0) [0|1] "" Vector__XXX
 SG_ PMR_a032_registerConfigError : 31|1@1+ (1,0) [0|1] "" Vector__XXX
 SG_ PMR_a033_selfTest : 32|1@1+ (1,0) [0|1] "" Vector__XXX
 SG_ PMR_a034_trqCrossCheck : 33|1@1+ (1,0) [0|1] "" Vector__XXX
 SG_ PMR_a035_udsTransactionInitiated : 34|1@1+ (1,0) [0|1] "" Vector__XXX
 SG_ PMR_a036_preWatchdog : 35|1@1+ (1,0) [0|1] "" Vector__XXX
 SG_ PMR_a037_hvpMIA : 36|1@1+ (1,0) [0|1] "" Vector__XXX
 SG_ PMR_a039_disMIA : 38|1@1+ (1,0) [0|1] "" Vector__XXX
 SG_ PMR_a040_pmMIA : 39|1@1+ (1,0) [0|1] "" Vector__XXX
 SG_ PMR_a042_gtwMIA : 41|1@1+ (1,0) [0|1] "" Vector__XXX
 SG_ PMR_a045_motorMovementDetected : 44|1@1+ (1,0) [0|1] "" Vector__XXX
 SG_ PMR_a053_vcfrontMIA : 52|1@1+ (1,0) [0|1] "" Vector__XXX
 SG_ PMR_a054_uiMIA : 53|1@1+ (1,0) [0|1] "" Vector__XXX
 SG_ PMR_a055_resolver : 54|1@1+ (1,0) [0|1] "" Vector__XXX
 SG_ PMR_a056_canHardwareBusB : 55|1@1+ (1,0) [0|1] "" Vector__XXX
 SG_ PMR_a057_canDataBusB : 56|1@1+ (1,0) [0|1] "" Vector__XXX
 SG_ PMR_a058_measuredHvilCurrentFroz : 57|1@1+ (1,0) [0|1] "" Vector__XXX
 SG_ PMR_a061_DIPMVersionMismatch : 60|1@1+ (1,0) [0|1] "" Vector__XXX
 SG_ PMR_a062_eccError : 61|1@1+ (1,0) [0|1] "" Vector__XXX
 SG_ PMR_a064_torqueIntervention : 63|1@1+ (1,0) [0|1] "" Vector__XXX

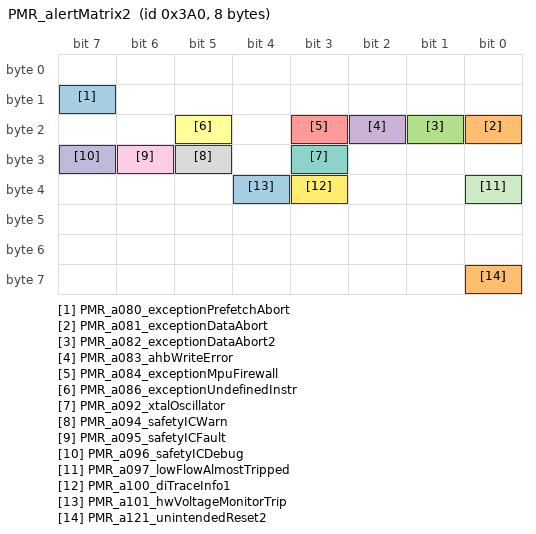
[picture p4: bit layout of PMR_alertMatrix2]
BO_ 928 PMR_alertMatrix2: 8 PMR
 SG_ PMR_a080_exceptionPrefetchAbort : 15|1@1+ (1,0) [0|1] "" Vector__XXX
 SG_ PMR_a081_exceptionDataAbort : 16|1@1+ (1,0) [0|1] "" Vector__XXX
 SG_ PMR_a082_exceptionDataAbort2 : 17|1@1+ (1,0) [0|1] "" Vector__XXX
 SG_ PMR_a083_ahbWriteError : 18|1@1+ (1,0) [0|1] "" Vector__XXX
 SG_ PMR_a084_exceptionMpuFirewall : 19|1@1+ (1,0) [0|1] "" Vector__XXX
 SG_ PMR_a086_exceptionUndefinedInstr : 21|1@1+ (1,0) [0|1] "" Vector__XXX
 SG_ PMR_a092_xtalOscillator : 27|1@1+ (1,0) [0|1] "" Vector__XXX
 SG_ PMR_a094_safetyICWarn : 29|1@1+ (1,0) [0|1] "" Vector__XXX
 SG_ PMR_a095_safetyICFault : 30|1@1+ (1,0) [0|1] "" Vector__XXX
 SG_ PMR_a096_safetyICDebug : 31|1@1+ (1,0) [0|1] "" Vector__XXX
 SG_ PMR_a097_lowFlowAlmostTripped : 32|1@1+ (1,0) [0|1] "" Vector__XXX
 SG_ PMR_a100_diTraceInfo1 : 35|1@1+ (1,0) [0|1] "" Vector__XXX
 SG_ PMR_a101_hwVoltageMonitorTrip : 36|1@1+ (1,0) [0|1] "" Vector__XXX
 SG_ PMR_a121_unintendedReset2 : 56|1@1+ (1,0) [0|1] "" Vector__XXX

BO_ 900 PM_alertMatrix1: 8 PM
 SG_ PM_a001_absoluteTorque : 0|1@1+ (1,0) [0|1] "" Vector__XXX
 SG_ PM_a002_excessiveAccelTorque : 1|1@1+ (1,0) [0|1] "" Vector__XXX
 SG_ PM_a003_excessiveReversalTorque : 2|1@1+ (1,0) [0|1] "" Vector__XXX
 SG_ PM_a004_excessiveDecelTorque : 3|1@1+ (1,0) [0|1] "" Vector__XXX
 SG_ PM_a005_torqueInNeutralOrPark : 4|1@1+ (1,0) [0|1] "" Vector__XXX
 SG_ PM_a006_inconsistentDIGear : 5|1@1+ (1,0) [0|1] "" Vector__XXX
 SG_ PM_a007_ibstMIA : 6|1@1+ (1,0) [0|1] "" Vector__XXX
 SG_ PM_a008_memoryError : 7|1@1+ (1,0) [0|1] "" Vector__XXX
 SG_ PM_a009_espMIA : 8|1@1+ (1,0) [0|1] "" Vector__XXX
 SG_ PM_a010_diMIA : 9|1@1+ (1,0) [0|1] "" Vector__XXX
 SG_ PM_a011_systemHvilNotClosed : 10|1@1+ (1,0) [0|1] "" Vector__XXX
 SG_ PM_a012_canDataBusA : 11|1@1+ (1,0) [0|1] "" Vector__XXX
 SG_ PM_a013_canHardwareBusA : 12|1@1+ (1,0) [0|1] "" Vector__XXX
 SG_ PM_a014_accelPedalError : 13|1@1+ (1,0) [0|1] "" Vector__XXX
 SG_ PM_a015_shifterMIA : 14|1@1+ (1,0) [0|1] "" Vector__XXX
 SG_ PM_a016_bbMIA : 15|1@1+ (1,0) [0|1] "" Vector__XXX
 SG_ PM_a017_brakeMIA : 16|1@1+ (1,0) [0|1] "" Vector__XXX
 SG_ PM_a019_vehicleSpeedQFDiagnostic : 18|1@1+ (1,0) [0|1] "" Vector__XXX
 SG_ PM_a021_difMIA : 20|1@1+ (1,0) [0|1] "" Vector__XXX
 SG_ PM_a022_dirMIA : 21|1@1+ (1,0) [0|1] "" Vector__XXX
 SG_ PM_a023_cruiseInhibit : 22|1@1+ (1,0) [0|1] "" Vector__XXX
 SG_ PM_a024_brakeIrrational : 23|1@1+ (1,0) [0|1] "" Vector__XXX
 SG_ PM_a025_unintendedReset : 24|1@1+ (1,0) [0|1] "" Vector__XXX
 SG_ PM_a026_diHeartBeatMIA : 25|1@1+ (1,0) [0|1] "" Vector__XXX
 SG_ PM_a028_torqueCmdError : 27|1@1+ (1,0) [0|1] "" Vector__XXX
 SG_ PM_a029_cruiseRollback : 28|1@1+ (1,0) [0|1] "" Vector__XXX
 SG_ PM_a030_inconsistentAebState : 29|1@1+ (1,0) [0|1] "" Vector__XXX
 SG_ PM_a031_highStackUsage : 30|1@1+ (1,0) [0|1] "" Vector__XXX
 SG_ PM_a032_registerConfigError : 31|1@1+ (1,0) [0|1] "" Vector__XXX
 SG_ PM_a033_appMIA : 32|1@1+ (1,0) [0|1] "" Vector__XXX
 SG_ PM_a034_trqCrossCheck : 33|1@1+ (1,0) [0|1] "" Vector__XXX
 SG_ PM_a035_udsTransactionInitiated : 34|1@1+ (1,0) [0|1] "" Vector__XXX
 SG_ PM_a036_preWatchdog : 35|1@1+ (1,0) [0|1] "" Vector__XXX
 SG_ PM_a038_inconsistentTorqueSign : 37|1@1+ (1,0) [0|1] "" Vector__XXX
 SG_ PM_a039_disMIA : 38|1@1+ (1,0) [0|1] "" Vector__XXX
 SG_ PM_a040_latLinkLooseBoltDetected : 39|1@1+ (1,0) [0|1] "" Vector__XXX
 SG_ PM_a041_dasMIA : 40|1@1+ (1,0) [0|1] "" Vector__XXX
 SG_ PM_a042_gtwMIA : 41|1@1+ (1,0) [0|1] "" Vector__XXX
 SG_ PM_a043_inconsistentConfig : 42|1@1+ (1,0) [0|1] "" Vector__XXX
 SG_ PM_a044_ebrIntervention : 43|1@1+ (1,0) [0|1] "" Vector__XXX
 SG_ PM_a045_regenBackfillInterventio : 44|1@1+ (1,0) [0|1] "" Vector__XXX
 SG_ PM_a046_inconsVehicleHoldState : 45|1@1+ (1,0) [0|1] "" Vector__XXX
 SG_ PM_a047_inconsAutoparkState : 46|1@1+ (1,0) [0|1] "" Vector__XXX
 SG_ PM_a048_stabilityControlInhibit : 47|1@1+ (1,0) [0|1] "" Vector__XXX
 SG_ PM_a049_stbCtrlInWrongDir : 48|1@1+ (1,0) [0|1] "" Vector__XXX
 SG_ PM_a050_excessiveStbCtrlTrq : 49|1@1+ (1,0) [0|1] "" Vector__XXX
 SG_ PM_a051_unintDecelStbCtrl : 50|1@1+ (1,0) [0|1] "" Vector__XXX
 SG_ PM_a052_stbCtrlDrvrDecelCflct : 51|1@1+ (1,0) [0|1] "" Vector__XXX
 SG_ PM_a053_vcfrontMIA : 52|1@1+ (1,0) [0|1] "" Vector__XXX
 SG_ PM_a054_uiMIA : 53|1@1+ (1,0) [0|1] "" Vector__XXX
 SG_ PM_a055_accelPedalSyncWarn : 54|1@1+ (1,0) [0|1] "" Vector__XXX
 SG_ PM_a056_canHardwareBusB : 55|1@1+ (1,0) [0|1] "" Vector__XXX
 SG_ PM_a057_canDataBusB : 56|1@1+ (1,0) [0|1] "" Vector__XXX
 SG_ PM_a058_cmpMIA : 57|1@1+ (1,0) [0|1] "" Vector__XXX
 SG_ PM_a059_ptcMIA : 58|1@1+ (1,0) [0|1] "" Vector__XXX
 SG_ PM_a060_onePedalDrivingInhibit : 59|1@1+ (1,0) [0|1] "" Vector__XXX
 SG_ PM_a061_DIPMVersionMismatch : 60|1@1+ (1,0) [0|1] "" Vector__XXX
 SG_ PM_a062_eccError : 61|1@1+ (1,0) [0|1] "" Vector__XXX
 SG_ PM_a063_torqueCommandInhibit : 62|1@1+ (1,0) [0|1] "" Vector__XXX
 SG_ PM_a064_torqueIntervention : 63|1@1+ (1,0) [0|1] "" Vector__XXX

BO_TX_BU_ 2047 : GTW;
BO_TX_BU_ 1638 : GTW;
BO_TX_BU_ 1080 : GTW;
BO_TX_BU_ 1656 : GTW;
BO_TX_BU_ 2033 : GTW;
BO_TX_BU_ 60 : GTW;
BO_TX_BU_ 1370 : GTW;
BO_TX_BU_ 840 : GTW;
BO_TX_BU_ 1005 : GTW;
BO_TX_BU_ 1112 : GTW;
BO_TX_BU_ 760 : ICR;
BO_TX_BU_ 1470 : IDB;
BO_TX_BU_ 983 : IDB;
BO_TX_BU_ 828 : IDB;
BO_TX_BU_ 1429 : OCS1P;
BO_TX_BU_ 767 : OCS1P;
BO_TX_BU_ 766 : OCS1P;
BO_TX_BU_ 771 : OCS1P;
BO_TX_BU_ 772 : PMF;
BO_TX_BU_ 2022 : PMF;
BO_TX_BU_ 902 : PMR;
BO_TX_BU_ 928 : PMR;
BO_TX_BU_ 900 : PM;
CM_ BO_ 2047 "Gateway message: car config";
CM_ SG_ 2047 GTW_carConfigMultiplexer "Gateway: car config multiplexer";
CM_ SG_ 2047 GTW_deliveryStatus "Indicates whether the vehicle has been marked delivered to the customer in Tesla backend systems.";
CM_ SG_ 2047 GTW_cabinPTCHeaterType "Gateway: cabin PTC heater type";
CM_ SG_ 2047 GTW_rightHandDrive "Gateway: right hand drive";
CM_ SG_ 2047 GTW_rearLightType "Gateway: rear light type";
CM_ SG_ 2047 GTW_headlamps "Gateway: headlamps";
CM_ SG_ 2047 GTW_country "Gateway: country";
CM_ SG_ 2047 GTW_tireType "Gateway: tire type";
CM_ SG_ 2047 GTW_roofGlassType "Gateway: roof glass type";
CM_ SG_ 2047 GTW_dasHw "Indicates the Driver Assistance System (DAS) hardware installed.";
CM_ SG_ 2047 GTW_brakeHWType "Gateway: brake HW type";
CM_ SG_ 2047 GTW_restraintsHardwareType "Gateway: restraints hardware type";
CM_ SG_ 2047 GTW_drivetrainType "Gateway: drivetrain type";
CM_ SG_ 2047 GTW_radarHeaterType "Gateway: radar heater type";
CM_ SG_ 2047 GTW_exteriorTrimType "Gateway: exterior trim type";
CM_ SG_ 2047 GTW_frontSeatHeaters "Gateway: front seat heaters";
CM_ SG_ 2047 GTW_rearSeatHeaters "Gateway: rear seat heaters";
CM_ SG_ 2047 GTW_eCallAntennaHW "Gateway: e call antenna HW";
CM_ SG_ 2047 GTW_homelinkType "Gateway: homelink type";
CM_ SG_ 2047 GTW_vdcType "Gateway: vdc type";
CM_ SG_ 2047 GTW_memoryMirrors "Gateway: memory mirrors";
CM_ SG_ 2047 GTW_powerLiftgateType "Gateway: power liftgate type";
CM_ SG_ 2047 GTW_lumbarECUType "Gateway: lumbar ECU type";
CM_ SG_ 2047 GTW_rearSeatHeaterType "Gateway: rear seat heater type";
CM_ SG_ 2047 GTW_auxParkLamps "Gateway: aux park lamps";
CM_ SG_ 2047 GTW_interiorCabinRadarType "Gateway: interior cabin radar type";
CM_ SG_ 2047 GTW_hvacPanelVaneType "Gateway: hvac panel vane type";
CM_ SG_ 2047 GTW_intakeAirFilterType "Gateway: intake air filter type";
CM_ SG_ 2047 GTW_eBuckConfig "Gateway: e buck config";
CM_ SG_ 2047 GTW_steeringHeaterEnabled "Gateway: steering heater enabled";
CM_ SG_ 2047 GTW_activeHighBeam "Gateway: active high beam";
CM_ SG_ 2047 GTW_airbagCutoffSwitch "Gateway: airbag cutoff switch";
CM_ SG_ 2047 GTW_intrusionSensorType "Gateway: intrusion sensor type";
CM_ SG_ 2047 GTW_spoilerType "Gateway: spoiler type";
CM_ SG_ 2047 GTW_rearFogLamps "Gateway: rear fog lamps";
CM_ SG_ 2047 GTW_roofType "Gateway: roof type";
CM_ SG_ 2047 GTW_thirdRowSeatType "Gateway: third row seat type";
CM_ SG_ 2047 GTW_autopilot "Gateway: autopilot";
CM_ SG_ 2047 GTW_superchargingAccess "Gateway: supercharging access";
CM_ SG_ 2047 GTW_exteriorColor "Gateway: exterior color";
CM_ SG_ 2047 GTW_pedestrianWarningSound "Gateway: pedestrian warning sound";
CM_ SG_ 2047 GTW_steeringColumnUJointType "Gateway: steering column u joint type";
CM_ SG_ 2047 GTW_bPillarNFCParam "Gateway: b pillar NFC param";
CM_ SG_ 2047 GTW_interiorLighting "Gateway: interior lighting";
CM_ SG_ 2047 GTW_headlightLevelerType "Gateway: headlight leveler type";
CM_ SG_ 2047 GTW_numberHVILNodes "Gateway: number HVIL nodes";
CM_ SG_ 2047 GTW_mapRegion "Gateway: map region";
CM_ SG_ 2047 GTW_performancePackage "Gateway: performance package";
CM_ SG_ 2047 GTW_chassisType "Indicates the chassis type, which determines physical aspects such as suspension geometry, track width, wheel base, baseline tire size, and trailer capability.";
CM_ SG_ 2047 GTW_airSuspension "Gateway: air suspension";
CM_ SG_ 2047 GTW_centerConsoleControllerType "Gateway: center console controller type";
CM_ SG_ 2047 GTW_autopilotCameraType "Gateway: autopilot camera type";
CM_ SG_ 2047 GTW_connectivityPackage "Gateway: connectivity package";
CM_ SG_ 2047 GTW_plcSupportType "Gateway: plc support type";
CM_ SG_ 2047 GTW_packEnergy "Gateway: pack energy";
CM_ SG_ 2047 GTW_frontSeatReclinerHardware "Gateway: front seat recliner hardware";
CM_ SG_ 2047 GTW_brakeLineSwitchType "Gateway: brake line switch type";
CM_ SG_ 2047 GTW_espValveType "Gateway: esp valve type";
CM_ SG_ 2047 GTW_softRange "Gateway: soft range";
CM_ SG_ 2047 GTW_refrigerantType "Gateway: refrigerant type";
CM_ SG_ 2047 GTW_wheelType "Gateway: wheel type";
CM_ SG_ 2047 GTW_ptcControlMode "Gateway: ptc control mode";
CM_ SG_ 2047 GTW_brakeActuationType "Gateway: brake actuation type";
CM_ SG_ 2047 GTW_secondRowSeatType "Gateway: second row seat type";
CM_ SG_ 2047 GTW_secondRowSeatMotorType "Gateway: second row seat motor type";
CM_ SG_ 2047 GTW_birthday "Gateway: birthday";
CM_ SG_ 2047 GTW_eCallEnabled "Gateway: e call enabled";
CM_ SG_ 2047 GTW_parkAssistECUType "Gateway: park assist ECU type";
CM_ SG_ 2047 GTW_passengerAirbagType "Gateway: passenger airbag type";
CM_ SG_ 2047 GTW_forwardRadarHw "Gateway: forward radar hw";
CM_ SG_ 2047 GTW_frontSeatType "Gateway: front seat type";
CM_ SG_ 2047 GTW_secondRowDisplayType "Gateway: second row display type";
CM_ SG_ 2047 GTW_wirelessPhoneChargerType "Gateway: wireless phone charger type";
CM_ SG_ 2047 GTW_ethernetTunerType "Gateway: ethernet tuner type";
CM_ SG_ 2047 GTW_interiorTrimType "Gateway: interior trim type";
CM_ SG_ 2047 GTW_gloveboxUSBType "Gateway: glovebox USB type";
CM_ SG_ 2047 GTW_coolantPumpType "Gateway: coolant pump type";
CM_ SG_ 2047 GTW_epblHwType "Gateway: epbl hw type";
CM_ SG_ 2047 GTW_epbrHwType "Gateway: epbr hw type";
CM_ SG_ 2047 GTW_blowerMotorType "Gateway: blower motor type";
CM_ SG_ 2047 GTW_rearLeftBLEEndpointParameter "Gateway: rear left BLE endpoint parameter type";
CM_ SG_ 2047 GTW_frontUsbHubType "Gateway: front usb hub type";
CM_ SG_ 2047 GTW_superManifoldType "Type of HVAC super manifold installed";
CM_ SG_ 2047 GTW_rcmLocation "Gateway: rcm location";
CM_ SG_ 2047 GTW_interiorCamFanType "Gateway: interior cam fan type";
CM_ SG_ 2047 GTW_interiorCamBeautyCoverType "Gateway: interior cam beauty cover type";
CM_ SG_ 2047 GTW_sirenType "Gateway: siren type";
CM_ SG_ 2047 GTW_hornType "Gateway: horn type";
CM_ SG_ 2047 GTW_badgingVersion "Gateway: badging version";
CM_ SG_ 2047 GTW_steeringColumnMotorType "Gateway: steering column motor type";
CM_ SG_ 2047 GTW_refrigACLineType "Gateway: refrig AC line type";
CM_ SG_ 2047 GTW_refrigFilterType "Gateway: refrig filter type";
CM_ SG_ 2047 GTW_diBurnInType "Gateway: di burn in type";
CM_ SG_ 2047 GTW_specialBadgingType "Gateway: special badging type";
CM_ SG_ 2047 GTW_chassisSubType "Reports chassis sub-variant type.";
CM_ SG_ 2047 GTW_frontSeatVentilationType "Gateway: front seat ventilation type";
CM_ SG_ 2047 GTW_towPackage "Gateway: tow package";
CM_ SG_ 2047 GTW_refrigLccType "Gateway: refrig lcc type";
CM_ SG_ 2047 GTW_caliperColorType "Gateway: caliper color type";
CM_ SG_ 2047 GTW_wiperMotorType "Gateway: wiper motor type";
CM_ SG_ 2047 GTW_frontOverheadConsoleType "Gateway: front overhead console type";
CM_ SG_ 2047 GTW_shifterType "Gateway: shifter type";
CM_ SG_ 2047 GTW_compressorType "Gateway: compressor type";
CM_ SG_ 2047 GTW_twelveVBatteryType "Gateway: twelve v battery type";
CM_ SG_ 2047 GTW_efuseSWConfig "Gateway: efuse SW config";
CM_ SG_ 2047 GTW_tollCollectionModuleType "Gateway: toll collection module type";
CM_ SG_ 2047 GTW_bleEndpointUpdateMethod "Gateway: ble endpoint update method";
CM_ SG_ 2047 GTW_steeringWheelControllerType "Gateway: steering wheel controller type";
CM_ SG_ 2047 GTW_frontSeatVentilationEnabled "Gateway: front seat ventilation enabled";
CM_ SG_ 2047 GTW_gloveboxActuatorType "Gateway: glovebox actuator type";
CM_ SG_ 2047 GTW_epasType "Gateway: epas type";
CM_ SG_ 2047 GTW_homologationRegionOverride "Gateway: homologation region override";
CM_ SG_ 2047 GTW_windowCommandsPermissionType "Gateway: window commands permission type";
CM_ SG_ 2047 GTW_headlightStepperStallDetectM "Gateway: headlight stepper stall detect mode";
CM_ SG_ 2047 GTW_rgbInteriorLightingEnabled "Gateway: rgb interior lighting enabled";
CM_ SG_ 2047 GTW_windshieldWiperHeaterType "Gateway: windshield wiper heater type";
CM_ SG_ 2047 GTW_driveInterfaceType "Gateway: drive interface type";
CM_ SG_ 2047 GTW_efficiencyPackage "Gateway: efficiency package";
CM_ SG_ 2047 GTW_visorLightType "Gateway: visor light type";
CM_ SG_ 2047 GTW_gnssAntennaType "Gateway: gnss antenna type";
CM_ SG_ 2047 GTW_frontSeatHeatersEnabled "Gateway: front seat heaters enabled";
CM_ SG_ 2047 GTW_windshieldWiperHeaterEnabled "Gateway: windshield wiper heater enabled";
CM_ SG_ 2047 GTW_tcuType "Gateway: tcu type";
CM_ SG_ 2047 GTW_fasciaType "Gateway: fascia type";
CM_ SG_ 2047 GTW_powerSteeringColumn "Gateway: power steering column";
CM_ SG_ 2047 GTW_frontSeatHeaterType "Gateway: front seat heater type";
CM_ SG_ 2047 GTW_softPerformanceLimit "Gateway: soft performance limit";
CM_ SG_ 2047 GTW_alcoholInterlockType "Gateway: alcohol interlock type";
CM_ SG_ 2047 GTW_immersiveAudio "Gateway: immersive audio";
CM_ SG_ 2047 GTW_passengerOccupancySensorType "Gateway: passenger occupancy sensor type";
CM_ SG_ 2047 GTW_packPerformanceDeviation "Measures deviation from standard pack mass or power output capability associated with the vehicle packEnergy configuration.";
CM_ SG_ 2047 GTW_frontFogLamps "Gateway: front fog lamps";
CM_ SG_ 2047 GTW_driverOccupancySensorType "Gateway: driver occupancy sensor type";
CM_ SG_ 2047 GTW_audioType "Gateway: audio type";
CM_ SG_ 2047 GTW_occupancyClassificationFeatu "Gateway: occupancy classification feature type";
CM_ SG_ 2047 GTW_domeLightType "Gateway: dome light type";
CM_ SG_ 2047 GTW_tpmsType "Gateway: tpms type";
CM_ SG_ 2047 GTW_authenticationEndpointLayout "Gateway: authentication endpoint layout";
CM_ SG_ 2047 GTW_socSleepOverride "Gateway: soc sleep override";
CM_ SG_ 2047 GTW_r79BehaviorOverride "Gateway: r79 behavior override";
CM_ SG_ 2047 GTW_steeringHeaterType "Gateway: steering heater type";
CM_ SG_ 2047 GTW_sohRegulatoryStatus "Gateway: soh regulatory status";
CM_ SG_ 2047 GTW_m3yBusArchitecture "Reports notable features of vehicle communication bus architecture. Used for firmware artifact selection during update installation process.";
CM_ SG_ 2047 GTW_blindSpotIndicatorLightType "Gateway: blind spot indicator light type";
CM_ SG_ 2047 GTW_hvacCaseDoorType "Gateway: hvac case door type";
CM_ SG_ 2047 GTW_occupancyDetectionSourceRequ "Gateway: occupancy detection source request";
CM_ SG_ 2047 GTW_rduCableType "Indicates type of rear drive unit cable installed on vehicle.";
CM_ SG_ 2047 GTW_interiorCameraType "Gateway: interior camera type";
CM_ SG_ 2047 GTW_frontFasciaCameraType "Reports type of forward facing fascia camera installed.";
CM_ BO_ 1638 "Gateway message: diag session";
CM_ SG_ 1638 GTW_diagRemainingSeconds "Seconds remaining for the diagnostics session";
CM_ SG_ 1638 GTW_diagSessionActive "UDS Session Active";
CM_ SG_ 1638 GTW_diagLevel "Current diagnostics level";
CM_ SG_ 1638 GTW_diagUnlockProcedureActive "GTW diag unlock procedure active";
CM_ SG_ 1638 GTW_diagOverrideActive "GTW diag level override active";
CM_ SG_ 1638 GTW_diagPhysicalLinkEstablished "Physical diag cable connected to the switch and link established";
CM_ BO_ 1080 "Gateway message: eth nm";
CM_ SG_ 1080 GTW_ethGotoSleep "ETH bus sleep commanded";
CM_ SG_ 1080 GTW_ethWakeUpBus "Gateway: eth wake up bus";
CM_ SG_ 1080 GTW_vehBusAsleep "VEH bus sleep state";
CM_ SG_ 1080 GTW_ethHeartBeatCounter "Gateway: eth heart beat counter";
CM_ SG_ 1080 GTW_ethWakeUpReason "Tracks the cause of why the gateway wakes up the ethernet bus";
CM_ BO_ 1656 "Gateway message: gear control";
CM_ SG_ 1656 GTW_gearControlChecksum "Gateway: gear control checksum";
CM_ SG_ 1656 GTW_gearControlCounter "Gateway: gear control counter";
CM_ SG_ 1656 GTW_gearShiftRequest "Request to change gear state from center display UI control; raw 0 = signal not available (SNA)";
CM_ SG_ 1656 GTW_osdActive "Whether OSD is active";
CM_ SG_ 1656 GTW_primaryGearControlStatus "Status of the center display UI control";
CM_ SG_ 1656 GTW_gearStripEnable "UI control for showing and or activating the primary gear strip interface";
CM_ SG_ 1656 GTW_showNeutralButton "Tell UI that it is time to animate the N button to be shown";
CM_ SG_ 1656 GTW_showAutoParkButton "Tell UI that it is time to animate the autopark button to be shown";
CM_ SG_ 1656 GTW_autoParkRequest "Request to auto park from center display UI control";
CM_ SG_ 1656 GTW_smartShiftStatus "Based on the status of the infotainment system smart shift feature should be disabled; raw 0 = signal not available (SNA)";
CM_ SG_ 1656 GTW_processingRDgestures "Is GTW processing R and D swipe gestures";
CM_ SG_ 1656 GTW_processingTapPgestures "Is GTW processing contextual tap-to-park gestures";
CM_ SG_ 1656 GTW_gearStripChangeReason "Gateway: gear strip change reason; raw 0 = signal not available (SNA)";
CM_ SG_ 1656 GTW_touchActive "User present as touch on display is active";
CM_ SG_ 1656 GTW_steamOff "Let UI know to turn Steam off";
CM_ SG_ 1656 GTW_screenPCBTemperature "Reading from display i2c temperature sensor; raw 2047 = signal not available (SNA)";
CM_ BO_ 2033 "Gateway message: hrl";
CM_ SG_ 2033 GTW_hrlIndex "Gateway: hrl index";
CM_ SG_ 2033 GTW_hrlState "GTW hrl state";
CM_ SG_ 2033 GTW_hrlTriggerDuration "HRL duration";
CM_ SG_ 2033 GTW_hrlTriggerType "HRL trigger type";
CM_ SG_ 2033 GTW_hrlTriggerId "HRL trigger ID. A unique ID representing the signal conditions causing the HRL event to occur.";
CM_ SG_ 2033 GTW_hrlTriggerBus "Gateway: hrl trigger bus";
CM_ BO_ 60 "Gateway message: info";
CM_ SG_ 60 GTW_infoIndex "Gateway: info index";
CM_ SG_ 60 GTW_buildType "Gateway: build type";
CM_ SG_ 60 GTW_hardwareId "GTW hardware ID";
CM_ SG_ 60 GTW_platformType "Gateway: platform type";
CM_ SG_ 60 GTW_appCrc "Gateway: app crc";
CM_ SG_ 60 GTW_applicationGitHash "Gateway: application git hash";
CM_ SG_ 60 GTW_bootGitHash "Gateway: boot git hash";
CM_ BO_ 1370 "Gateway message: mismatch fault";
CM_ SG_ 1370 GTW_mismatchFaultIndex "Gateway: mismatch fault index";
CM_ SG_ 1370 GTW_mismatchFaultChecksum "Gateway: mismatch fault checksum";
CM_ SG_ 1370 GTW_mismatchFaultCounter "Gateway: mismatch fault counter";
CM_ SG_ 1370 GTW_GTWmismatchFault "Reports the Gateway (GTW) running a firmware version that does not match the rest of the vehicle";
CM_ SG_ 1370 GTW_BMSmismatchFault "Reports the high voltage Battery Management System (BMS) electronic control unit (ECU) running a firmware version that does not match the rest of the vehicle";
CM_ SG_ 1370 GTW_APSmismatchFault "Reports the Autopilot Processor Secondary (APS) electronic control unit (ECU) running a firmware version that does not match the rest of the vehicle";
CM_ SG_ 1370 GTW_BLEEPCENTERmismatchFault "Reports the Bluetooth Low Energy End Point Center (BLEEPCENTER) electronic control unit (ECU) running a firmware version that does not match the rest of the vehicle";
CM_ SG_ 1370 GTW_BLEEPLEFTmismatchFault "Reports the Bluetooth Low Energy End Point Left (BLEEPLEFT) electronic control unit (ECU) running a firmware version that does not match the rest of the vehicle";
CM_ SG_ 1370 GTW_BLEEPREARmismatchFault "Reports the Bluetooth Low Energy End Point Rear (BLEEPREAR) electronic control unit (ECU) running a firmware version that does not match the rest of the vehicle";
CM_ SG_ 1370 GTW_BLEEPRIGHTmismatchFault "Reports the Bluetooth Low Energy End Point Right (BLEEPRIGHT) electronic control unit (ECU) running a firmware version that does not match the rest of the vehicle";
CM_ SG_ 1370 GTW_CBCmismatchFault "Reports the Cabin Blower Controller (CBC) electronic control unit (ECU) running a firmware version that does not match the rest of the vehicle";
CM_ SG_ 1370 GTW_CMPmismatchFault "Reports the air conditioning compressor (CMP) electronic control unit (ECU) running a firmware version that does not match the rest of the vehicle";
CM_ SG_ 1370 GTW_CPmismatchFault "Reports the Charge Port (CP) electronic control unit (ECU) running a firmware version that does not match the rest of the vehicle";
CM_ SG_ 1370 GTW_DIFmismatchFault "Reports the front drive inverter (DIF) electronic control unit (ECU) running a firmware version that does not match the rest of the vehicle";
CM_ SG_ 1370 GTW_DIRmismatchFault "Reports the rear drive inverter (DIR) electronic control unit (ECU) running a firmware version that does not match the rest of the vehicle";
CM_ SG_ 1370 GTW_EPAS3PmismatchFault "Reports the primary Electronic Power Assisted Steering (EPAS3P) electronic control unit (ECU) running a firmware version that does not match the rest of the vehicle";
CM_ SG_ 1370 GTW_EPAS3SmismatchFault "Reports the secondary Electronic Power Assisted Steering (EPAS3S) electronic control unit (ECU) running a firmware version that does not match the rest of the vehicle";
CM_ SG_ 1370 GTW_EPBLmismatchFault "Reports the left Electronic Park Brake (EPBL) electronic control unit (ECU) running a firmware version that does not match the rest of the vehicle";
CM_ SG_ 1370 GTW_EPBRmismatchFault "Reports the right Electronic Park Brake (EPBR) electronic control unit (ECU) running a firmware version that does not match the rest of the vehicle";
CM_ SG_ 1370 GTW_ESPCALmismatchFault "Reports the Electronic Stability Program Calibration (ESPCAL) electronic control unit (ECU) running a firmware version that does not match the rest of the vehicle";
CM_ SG_ 1370 GTW_ESPmismatchFault "Reports the Electronic Stability Program (ESP) electronic control unit (ECU) running a firmware version that does not match the rest of the vehicle";
CM_ SG_ 1370 GTW_HCM3LmismatchFault "Reports the left LED matrix Headlamp Control Module (HCM3L) electronic control unit (ECU) running a firmware version that does not match the rest of the vehicle";
CM_ SG_ 1370 GTW_HCM3RmismatchFault "Reports the right LED matrix Headlamp Control Module (HCM3R) electronic control unit (ECU) running a firmware version that does not match the rest of the vehicle";
CM_ SG_ 1370 GTW_HCMLmismatchFault "Reports the left Headlamp Control Module (HCML) electronic control unit (ECU) running a firmware version that does not match the rest of the vehicle";
CM_ SG_ 1370 GTW_HCMRmismatchFault "Reports the right Headlamp Control Module (HCMR) electronic control unit (ECU) running a firmware version that does not match the rest of the vehicle";
CM_ SG_ 1370 GTW_HVPmismatchFault "Reports the High Voltage Processor (HVP) electronic control unit (ECU) running a firmware version that does not match the rest of the vehicle";
CM_ SG_ 1370 GTW_IBSTCALmismatchFault "Reports the electromechanical brake booster calibration, or iBooster Calibration (IBSTCAL), electronic control unit (ECU) running a firmware version that does not match the rest of the vehicle";
CM_ SG_ 1370 GTW_IBSTmismatchFault "Reports the electromechanical brake booster, or iBooster (IBST), electronic control unit (ECU) running a firmware version that does not match the rest of the vehicle";
CM_ SG_ 1370 GTW_LVBMSmismatchFault "Reports the Low Voltage Battery Management System (LVBMS) electronic control unit (ECU) running a firmware version that does not match the rest of the vehicle";
CM_ SG_ 1370 GTW_OCS1PmismatchFault "Reports the Occupancy Classification System - 1st Row Passenger (OCS1P) electronic control unit (ECU) running a firmware version that does not match the rest of the vehicle";
CM_ SG_ 1370 GTW_OPCFmismatchFault "Reports the front Oil Pump Controller (OPCF) electronic control unit (ECU) running a firmware version that does not match the rest of the vehicle";
CM_ SG_ 1370 GTW_OPCRmismatchFault "Reports the rear Oil Pump Controller (OPCR) electronic control unit (ECU) running a firmware version that does not match the rest of the vehicle";
CM_ SG_ 1370 GTW_PARKmismatchFault "Reports the Park Assist (PARK) electronic control unit (ECU) running a firmware version that does not match the rest of the vehicle";
CM_ SG_ 1370 GTW_PCSCPU2mismatchFault "Reports the Power Conversion System AC charging core (PCSCPU2) electronic control unit (ECU) running a firmware version that does not match the rest of the vehicle";
CM_ SG_ 1370 GTW_PCSmismatchFault "Reports the Power Conversion System (PCS) electronic control unit (ECU) running a firmware version that does not match the rest of the vehicle";
CM_ SG_ 1370 GTW_PMFmismatchFault "Reports the front Pedal Monitor (PMF) electronic control unit (ECU) running a firmware version that does not match the rest of the vehicle";
CM_ SG_ 1370 GTW_PMRmismatchFault "Reports the rear Pedal Monitor (PMR) electronic control unit (ECU) running a firmware version that does not match the rest of the vehicle";
CM_ SG_ 1370 GTW_PTCmismatchFault "Reports the Positive Temperature Coefficient (PTC) heater electronic control unit (ECU) running a firmware version that does not match the rest of the vehicle";
CM_ SG_ 1370 GTW_RCMCALmismatchFault "Reports the Restraint Control Module Calibration (RCMCAL) electronic control unit (ECU) running a firmware version that does not match the rest of the vehicle";
CM_ SG_ 1370 GTW_RCMmismatchFault "Reports the Restraint Control Module (RCM) electronic control unit (ECU) running a firmware version that does not match the rest of the vehicle";
CM_ SG_ 1370 GTW_SCCMmismatchFault "Reports the Steering Column Control Module (SCCM) electronic control unit (ECU) running a firmware version that does not match the rest of the vehicle";
CM_ SG_ 1370 GTW_SDCRmismatchFault "Reports the Secondary Disconnect Controller (SDCR) electronic control unit (ECU) running a firmware version that does not match the rest of the vehicle";
CM_ SG_ 1370 GTW_SWCmismatchFault "Reports the Steering Wheel Controller (SWC) electronic control unit (ECU) running a firmware version that does not match the rest of the vehicle";
CM_ SG_ 1370 GTW_THSmismatchFault "Reports the Temperature Humidity Sensor (THS) electronic control unit (ECU) running a firmware version that does not match the rest of the vehicle";
CM_ SG_ 1370 GTW_VCFRONTmismatchFault "Reports the front vehicle controller (VCFRONT) electronic control unit (ECU) running a firmware version that does not match the rest of the vehicle";
CM_ SG_ 1370 GTW_VCLEFTmismatchFault "Reports the left vehicle controller (VCLEFT) electronic control unit (ECU) running a firmware version that does not match the rest of the vehicle";
CM_ SG_ 1370 GTW_VCRIGHTmismatchFault "Reports the right vehicle controller (VCRIGHT) electronic control unit (ECU) running a firmware version that does not match the rest of the vehicle";
CM_ SG_ 1370 GTW_VCSECmismatchFault "Reports the vehicle security controller (VCSEC) electronic control unit (ECU) running a firmware version that does not match the rest of the vehicle";
CM_ SG_ 1370 GTW_PMmismatchFault "Reports the Pedal Monitor (PM) electronic control unit (ECU) running a firmware version that does not match the rest of the vehicle";
CM_ BO_ 840 "Gateway message: status";
CM_ SG_ 840 GTW_vehicleVersionMatchStatus "Signal to indicate if the vehicle ECUs are all on a matched production version";
CM_ SG_ 840 GTW_hwtype "Describes the chip GTW is running on; raw 0 = signal not available (SNA)";
CM_ SG_ 840 GTW_jcanProductName "Describes the JCAN reference (product) name; raw 0 = signal not available (SNA)";
CM_ SG_ 840 GTW_uptimeSeconds "GTW uptime in seconds";
CM_ SG_ 840 GTW_boardRevision "Board revision ID of the MCU PCBA";
CM_ SG_ 840 GTW_sentryModeState "Sentry Mode state; raw 6 = signal not available (SNA)";
CM_ SG_ 840 GTW_socSleepType "Describes the sleep type GTW is expecting from the SoC; raw 0 = signal not available (SNA)";
CM_ SG_ 840 GTW_resetType "Describes the type of reset GTW experienced; raw 0 = signal not available (SNA)";
CM_ BO_ 1005 "Gateway message: update status";
CM_ SG_ 1005 GTW_i2cUpdateActive "Gateway: i2c update active";
CM_ SG_ 1005 GTW_ecuUpdateStarted "Reports whether Electronic Control Unit (ECU) update phase is active.";
CM_ SG_ 1005 GTW_updateStarted "Main update in progress bit";
CM_ BO_ 1112 "Gateway message: veh nm";
CM_ SG_ 1112 GTW_nmGoingToSleep "Network management - Going to sleep state";
CM_ SG_ 1112 GTW_nmWakeUpBus "Gateway: nm wake up bus";
CM_ SG_ 1112 GTW_chBusAsleep "Chassis bus sleep state";
CM_ SG_ 1112 GTW_ethBusAsleep "ETH bus sleep state";
CM_ SG_ 1112 GTW_nmKeepAwakeReason "Network management - Keep awake reason; raw 0 = signal not available (SNA)";
CM_ SG_ 1112 GTW_nmWakeUpReason "Network management - Wakeup reason";
CM_ SG_ 1112 GTW_ethKeepAwakeReason "Reason GTW is keeping ETH bus awake; raw 0 = signal not available (SNA)";
CM_ SG_ 1112 GTW_nmDebugWakeUp "Gateway: nm debug wake up";
CM_ SG_ 1112 GTW_OTAKeepAwake "Signals that the vehicle buses should remain awake for an ongoing OTA update";
CM_ SG_ 1112 GTW_smsPokeReceived "The modem indicated it received an SMS poke";
CM_ SG_ 1112 GTW_bdyBusAsleep "BDY bus sleep state";
CM_ BO_ 760 "ICR ECU message: intrusion debug";
CM_ SG_ 760 ICR_loggingPeaksDBG "ICR ECU: logging peaks DBG";
CM_ SG_ 760 ICR_loggingCorrelationDBG "ICR ECU: logging correlation DBG";
CM_ SG_ 760 ICR_loggingTriggerRangeDBG "ICR ECU: logging trigger range DBG";
CM_ SG_ 760 ICR_loggingTriggerXPosDBG "ICR ECU: logging trigger x pos DBG";
CM_ SG_ 760 ICR_loggingTriggerYPosDBG "ICR ECU: logging trigger y pos DBG";
CM_ BO_ 1470 "IDB ECU message: alert log";
CM_ SG_ 1470 IDB_alertID "IDB ECU: alert ID";
CM_ SG_ 1470 IDB_alertState "IDB ECU: alert state";
CM_ SG_ 1470 IDB_a014_wheelSpeedSensorFreq "IDB ECU: a014 wheel speed sensor freq";
CM_ SG_ 1470 IDB_a014_wheelSpeedSensorPhase "IDB ECU: a014 wheel speed sensor phase";
CM_ SG_ 1470 IDB_a014_wheelSpeedSensorMisinst "IDB ECU: a014 wheel speed sensor misinstallation";
CM_ SG_ 1470 IDB_a014_wheelSpeedSensorWrongEx "IDB ECU: a014 wheel speed sensor wrong exciter";
CM_ SG_ 1470 IDB_a014_wheelSpeedSensorSpeedJu "IDB ECU: a014 wheel speed sensor speed jump minus";
CM_ SG_ 1470 IDB_a014_wheelSpeedSensorSp_0001 "IDB ECU: a014 wheel speed sensor speed jump plus";
CM_ SG_ 1470 IDB_a014_wheelSpeedSensorAirGap "IDB ECU: a014 wheel speed sensor air gap";
CM_ SG_ 1470 IDB_a014_wheelSpeedSensorBIST "IDB ECU: a014 wheel speed sensor BIST";
CM_ SG_ 1470 IDB_a014_wheelSpeedSensorLeakage "IDB ECU: a014 wheel speed sensor leakage cur";
CM_ SG_ 1470 IDB_a014_wheelSpeedSensorOverTem "IDB ECU: a014 wheel speed sensor over temp";
CM_ SG_ 1470 IDB_a014_wheelSpeedSensorSh_0001 "IDB ECU: a014 wheel speed sensor short to gnd";
CM_ SG_ 1470 IDB_a014_wheelSpeedSensorShortTo "IDB ECU: a014 wheel speed sensor short to bat";
CM_ SG_ 1470 IDB_a014_wheelSpeedSensorOpen "IDB ECU: a014 wheel speed sensor open";
CM_ SG_ 1470 IDB_a015_wheelSpeedSensorFreq "IDB ECU: a015 wheel speed sensor freq";
CM_ SG_ 1470 IDB_a015_wheelSpeedSensorPhase "IDB ECU: a015 wheel speed sensor phase";
CM_ SG_ 1470 IDB_a015_wheelSpeedSensorMisinst "IDB ECU: a015 wheel speed sensor misinstallation";
CM_ SG_ 1470 IDB_a015_wheelSpeedSensorWrongEx "IDB ECU: a015 wheel speed sensor wrong exciter";
CM_ SG_ 1470 IDB_a015_wheelSpeedSensorSpeedJu "IDB ECU: a015 wheel speed sensor speed jump minus";
CM_ SG_ 1470 IDB_a015_wheelSpeedSensorSp_0001 "IDB ECU: a015 wheel speed sensor speed jump plus";
CM_ SG_ 1470 IDB_a015_wheelSpeedSensorAirGap "IDB ECU: a015 wheel speed sensor air gap";
CM_ SG_ 1470 IDB_a015_wheelSpeedSensorBIST "IDB ECU: a015 wheel speed sensor BIST";
CM_ SG_ 1470 IDB_a015_wheelSpeedSensorLeakage "IDB ECU: a015 wheel speed sensor leakage cur";
CM_ SG_ 1470 IDB_a015_wheelSpeedSensorOverTem "IDB ECU: a015 wheel speed sensor over temp";
CM_ SG_ 1470 IDB_a015_wheelSpeedSensorSh_0001 "IDB ECU: a015 wheel speed sensor short to gnd";
CM_ SG_ 1470 IDB_a015_wheelSpeedSensorShortTo "IDB ECU: a015 wheel speed sensor short to bat";
CM_ SG_ 1470 IDB_a015_wheelSpeedSensorOpen "IDB ECU: a015 wheel speed sensor open";
CM_ SG_ 1470 IDB_a016_wheelSpeedSensorFreq "IDB ECU: a016 wheel speed sensor freq";
CM_ SG_ 1470 IDB_a016_wheelSpeedSensorPhase "IDB ECU: a016 wheel speed sensor phase";
CM_ SG_ 1470 IDB_a016_wheelSpeedSensorMisinst "IDB ECU: a016 wheel speed sensor misinstallation";
CM_ SG_ 1470 IDB_a016_wheelSpeedSensorWrongEx "IDB ECU: a016 wheel speed sensor wrong exciter";
CM_ SG_ 1470 IDB_a016_wheelSpeedSensorSpeedJu "IDB ECU: a016 wheel speed sensor speed jump minus";
CM_ SG_ 1470 IDB_a016_wheelSpeedSensorSp_0001 "IDB ECU: a016 wheel speed sensor speed jump plus";
CM_ SG_ 1470 IDB_a016_wheelSpeedSensorAirGap "IDB ECU: a016 wheel speed sensor air gap";
CM_ SG_ 1470 IDB_a016_wheelSpeedSensorBIST "IDB ECU: a016 wheel speed sensor BIST";
CM_ SG_ 1470 IDB_a016_wheelSpeedSensorLeakage "IDB ECU: a016 wheel speed sensor leakage cur";
CM_ SG_ 1470 IDB_a016_wheelSpeedSensorOverTem "IDB ECU: a016 wheel speed sensor over temp";
CM_ SG_ 1470 IDB_a016_wheelSpeedSensorSh_0001 "IDB ECU: a016 wheel speed sensor short to gnd";
CM_ SG_ 1470 IDB_a016_wheelSpeedSensorShortTo "IDB ECU: a016 wheel speed sensor short to bat";
CM_ SG_ 1470 IDB_a016_wheelSpeedSensorOpen "IDB ECU: a016 wheel speed sensor open";
CM_ SG_ 1470 IDB_a017_wheelSpeedSensorFreq "IDB ECU: a017 wheel speed sensor freq";
CM_ SG_ 1470 IDB_a017_wheelSpeedSensorPhase "IDB ECU: a017 wheel speed sensor phase";
CM_ SG_ 1470 IDB_a017_wheelSpeedSensorMisinst "IDB ECU: a017 wheel speed sensor misinstallation";
CM_ SG_ 1470 IDB_a017_wheelSpeedSensorWrongEx "IDB ECU: a017 wheel speed sensor wrong exciter";
CM_ SG_ 1470 IDB_a017_wheelSpeedSensorSpeedJu "IDB ECU: a017 wheel speed sensor speed jump minus";
CM_ SG_ 1470 IDB_a017_wheelSpeedSensorSp_0001 "IDB ECU: a017 wheel speed sensor speed jump plus";
CM_ SG_ 1470 IDB_a017_wheelSpeedSensorAirGap "IDB ECU: a017 wheel speed sensor air gap";
CM_ SG_ 1470 IDB_a017_wheelSpeedSensorBIST "IDB ECU: a017 wheel speed sensor BIST";
CM_ SG_ 1470 IDB_a017_wheelSpeedSensorLeakage "IDB ECU: a017 wheel speed sensor leakage cur";
CM_ SG_ 1470 IDB_a017_wheelSpeedSensorOverTem "IDB ECU: a017 wheel speed sensor over temp";
CM_ SG_ 1470 IDB_a017_wheelSpeedSensorSh_0001 "IDB ECU: a017 wheel speed sensor short to gnd";
CM_ SG_ 1470 IDB_a017_wheelSpeedSensorShortTo "IDB ECU: a017 wheel speed sensor short to bat";
CM_ SG_ 1470 IDB_a017_wheelSpeedSensorOpen "IDB ECU: a017 wheel speed sensor open";
CM_ SG_ 1470 IDB_a020_canSignalValidity "IDB ECU: a020 can signal validity";
CM_ SG_ 1470 IDB_a020_signalValueCrosscheck "IDB ECU: a020 signal value crosscheck";
CM_ SG_ 1470 IDB_a030_primaryExternalCircuitL "IDB ECU: a030 primary external circuit leakage";
CM_ SG_ 1470 IDB_a030_secondaryExternalCircui "IDB ECU: a030 secondary external circuit leakage";
CM_ SG_ 1470 IDB_a030_primaryChamberInternalL "IDB ECU: a030 primary chamber internal leakage";
CM_ SG_ 1470 IDB_a030_syncModeInternalLeakage "IDB ECU: a030 sync mode internal leakage";
CM_ SG_ 1470 IDB_a030_secondaryChamberInterna "IDB ECU: a030 secondary chamber internal leakage";
CM_ SG_ 1470 IDB_a030_masterCylinderInternalL "IDB ECU: a030 master cylinder internal leakage";
CM_ SG_ 1470 IDB_a060_validityOnChassisBus "IDB ECU: a060 validity on chassis bus";
CM_ SG_ 1470 IDB_a060_validityOnPartyBus "IDB ECU: a060 validity on party bus";
CM_ SG_ 1470 IDB_a061_validityOnChassisBus "IDB ECU: a061 validity on chassis bus";
CM_ SG_ 1470 IDB_a061_validityOnPartyBus "IDB ECU: a061 validity on party bus";
CM_ SG_ 1470 IDB_a062_validityOnChassisBus "IDB ECU: a062 validity on chassis bus";
CM_ SG_ 1470 IDB_a062_validityOnPartyBus "IDB ECU: a062 validity on party bus";
CM_ SG_ 1470 IDB_a063_validityOnChassisBus "IDB ECU: a063 validity on chassis bus";
CM_ SG_ 1470 IDB_a063_validityOnPartyBus "IDB ECU: a063 validity on party bus";
CM_ SG_ 1470 IDB_a064_validityOnChassisBus "IDB ECU: a064 validity on chassis bus";
CM_ SG_ 1470 IDB_a064_validityOnPartyBus "IDB ECU: a064 validity on party bus";
CM_ SG_ 1470 IDB_a065_validityOnChassisBus "IDB ECU: a065 validity on chassis bus";
CM_ SG_ 1470 IDB_a065_validityOnPartyBus "IDB ECU: a065 validity on party bus";
CM_ SG_ 1470 IDB_a106_qualifierValidity "IDB ECU: a106 qualifier validity";
CM_ SG_ 1470 IDB_a106_signalNotAvailable "IDB ECU: a106 signal not available";
CM_ SG_ 1470 IDB_a107_qualifierValidity "IDB ECU: a107 qualifier validity";
CM_ SG_ 1470 IDB_a107_signalNotAvailable "IDB ECU: a107 signal not available";
CM_ SG_ 1470 IDB_a112_qualifierValidity "IDB ECU: a112 qualifier validity";
CM_ SG_ 1470 IDB_a112_signalNotAvailable "IDB ECU: a112 signal not available";
CM_ SG_ 1470 IDB_a113_qualifierValidity "IDB ECU: a113 qualifier validity";
CM_ SG_ 1470 IDB_a113_signalNotAvailable "IDB ECU: a113 signal not available";
CM_ SG_ 1470 IDB_a114_qualifierValidity "IDB ECU: a114 qualifier validity";
CM_ SG_ 1470 IDB_a114_signalNotAvailable "IDB ECU: a114 signal not available";
CM_ SG_ 1470 IDB_a126_PMebrCmdStateValidity "IDB ECU: a126 p mebr cmd state validity";
CM_ SG_ 1470 IDB_a126_PMstate2Validity "IDB ECU: a126 p mstate2 validity";
CM_ SG_ 1470 IDB_a126_PMstate2Missing "IDB ECU: a126 p mstate2 missing";
CM_ SG_ 1470 IDB_a126_DIchassisControlValidit "IDB ECU: a126 d ichassis control validity";
CM_ SG_ 1470 IDB_a126_DIchassisControlMissing "IDB ECU: a126 d ichassis control missing";
CM_ SG_ 1470 IDB_a126_DIrequestActiveValidity "IDB ECU: a126 d irequest active validity";
CM_ SG_ 1470 IDB_a129_validityOnChassisBus "IDB ECU: a129 validity on chassis bus";
CM_ SG_ 1470 IDB_a129_validityOnPartyBus "IDB ECU: a129 validity on party bus";
CM_ SG_ 1470 IDB_a130_PMbrakePedalCmdQFValidi "IDB ECU: a130 p mbrake pedal cmd QF validity";
CM_ SG_ 1470 IDB_a130_PMstate2Validity "IDB ECU: a130 p mstate2 validity";
CM_ SG_ 1470 IDB_a130_PMstate2Missing "IDB ECU: a130 p mstate2 missing";
CM_ SG_ 1470 IDB_a130_DIbrakeCommandValidity "IDB ECU: a130 d ibrake command validity";
CM_ SG_ 1470 IDB_a130_DIbrakeCommandMissing "IDB ECU: a130 d ibrake command missing";
CM_ SG_ 1470 IDB_a130_DIbrakeTorqueCommandFul "IDB ECU: a130 d ibrake torque command full SNA";
CM_ SG_ 1470 IDB_a130_DIbrakeTorqueComma_0001 "IDB ECU: a130 d ibrake torque command full too low";
CM_ SG_ 1470 IDB_a132_validityOnChassisBus "IDB ECU: a132 validity on chassis bus";
CM_ SG_ 1470 IDB_a132_validityOnPartyBus "IDB ECU: a132 validity on party bus";
CM_ BO_ 983 "IDB ECU message: alert matrix";
CM_ SG_ 983 IDB_matrixIndex "IDB ECU: matrix index";
CM_ SG_ 983 IDB_a001_mcuGenericFault "IDB ECU: a001 mcu generic fault";
CM_ SG_ 983 IDB_a002_supplyOvervoltage "IDB ECU: a002 supply overvoltage";
CM_ SG_ 983 IDB_a003_supplyHardOvervoltage "IDB ECU: a003 supply hard overvoltage";
CM_ SG_ 983 IDB_a004_supplyUndervoltage "IDB ECU: a004 supply undervoltage";
CM_ SG_ 983 IDB_a005_supplyMidUndervoltage "IDB ECU: a005 supply mid undervoltage";
CM_ SG_ 983 IDB_a006_supplyHardUndervoltage "IDB ECU: a006 supply hard undervoltage";
CM_ SG_ 983 IDB_a007_wakeLineOpen "IDB ECU: a007 wake line open";
CM_ SG_ 983 IDB_a008_motorPowerOpen "IDB ECU: a008 motor power open";
CM_ SG_ 983 IDB_a009_asicBoostFault "IDB ECU: a009 asic boost fault";
CM_ SG_ 983 IDB_a010_asicGenericFault "IDB ECU: a010 asic generic fault";
CM_ SG_ 983 IDB_a011_solenoidValveFault "IDB ECU: a011 solenoid valve fault";
CM_ SG_ 983 IDB_a012_motorGenericFault "IDB ECU: a012 motor generic fault";
CM_ SG_ 983 IDB_a013_motorPosSensorFault "IDB ECU: a013 motor pos sensor fault";
CM_ SG_ 983 IDB_a014_FrLWSSFault "IDB ECU: a014 fr LWSS fault";
CM_ SG_ 983 IDB_a015_FrRWSSFault "IDB ECU: a015 fr RWSS fault";
CM_ SG_ 983 IDB_a016_ReLWSSFault "IDB ECU: a016 re LWSS fault";
CM_ SG_ 983 IDB_a017_ReRWSSFault "IDB ECU: a017 re RWSS fault";
CM_ SG_ 983 IDB_a018_WSSGenericFault "IDB ECU: a018 WSS generic fault";
CM_ SG_ 983 IDB_a019_pedalSensorFault "IDB ECU: a019 pedal sensor fault";
CM_ SG_ 983 IDB_a020_RCUpedalTravelMismatch "IDB ECU: a020 RC upedal travel mismatch";
CM_ SG_ 983 IDB_a021_pedalSensorNotCal "IDB ECU: a021 pedal sensor not cal";
CM_ SG_ 983 IDB_a022_brakeFluidLow "IDB ECU: a022 brake fluid low";
CM_ SG_ 983 IDB_a023_steeringImplausible "IDB ECU: a023 steering implausible";
CM_ SG_ 983 IDB_a024_yawImplausible "IDB ECU: a024 yaw implausible";
CM_ SG_ 983 IDB_a025_ayImplausible "IDB ECU: a025 ay implausible";
CM_ SG_ 983 IDB_a026_axImplausible "IDB ECU: a026 ax implausible";
CM_ SG_ 983 IDB_a027_circuitPresSensorFault "IDB ECU: a027 circuit pres sensor fault";
CM_ SG_ 983 IDB_a028_simPresSensorFault "IDB ECU: a028 sim pres sensor fault";
CM_ SG_ 983 IDB_a029_pressureSensNotCal "IDB ECU: a029 pressure sens not cal";
CM_ SG_ 983 IDB_a030_fluidLeakDetected "IDB ECU: a030 fluid leak detected";
CM_ SG_ 983 IDB_a031_solenoidValveStuck "IDB ECU: a031 solenoid valve stuck";
CM_ SG_ 983 IDB_a032_motorSoftOverheat "IDB ECU: a032 motor soft overheat";
CM_ SG_ 983 IDB_a033_motorHardOverheat "IDB ECU: a033 motor hard overheat";
CM_ SG_ 983 IDB_a034_motorPositionSetFault "IDB ECU: a034 motor position set fault";
CM_ SG_ 983 IDB_a035_motorStuck "IDB ECU: a035 motor stuck";
CM_ SG_ 983 IDB_a036_partyBusOff "IDB ECU: a036 party bus off";
CM_ SG_ 983 IDB_a037_chassisBusOff "IDB ECU: a037 chassis bus off";
CM_ SG_ 983 IDB_a038_motorInitFault "IDB ECU: a038 motor init fault";
CM_ SG_ 983 IDB_a039_absActive "IDB ECU: a039 abs active";
CM_ SG_ 983 IDB_a040_ebdActive "IDB ECU: a040 ebd active";
CM_ SG_ 983 IDB_a041_vdcActive "IDB ECU: a041 vdc active";
CM_ SG_ 983 IDB_a042_btcActive "IDB ECU: a042 btc active";
CM_ SG_ 983 IDB_a043_DItorquePathActive "IDB ECU: a043 d itorque path active";
CM_ SG_ 983 IDB_a044_standstillSkidDetected "IDB ECU: a044 standstill skid detected";
CM_ SG_ 983 IDB_a045_panicBrakeAssistActive "IDB ECU: a045 panic brake assist active";
CM_ SG_ 983 IDB_a046_fadeCompensationActive "IDB ECU: a046 fade compensation active";
CM_ SG_ 983 IDB_a047_brakeDiscWipeActive "IDB ECU: a047 brake disc wipe active";
CM_ SG_ 983 IDB_a048_scmActive "IDB ECU: a048 scm active";
CM_ SG_ 983 IDB_a049_cdpActive "IDB ECU: a049 cdp active";
CM_ SG_ 983 IDB_a050_absFaulted "IDB ECU: a050 abs faulted";
CM_ SG_ 983 IDB_a051_ebdFaulted "IDB ECU: a051 ebd faulted";
CM_ SG_ 983 IDB_a052_vdcFaulted "IDB ECU: a052 vdc faulted";
CM_ SG_ 983 IDB_a053_DItorquePathFaulted "IDB ECU: a053 d itorque path faulted";
CM_ SG_ 983 IDB_a054_skidDetectionFaulted "IDB ECU: a054 skid detection faulted";
CM_ SG_ 983 IDB_a055_panicBrakeAssistFaulted "IDB ECU: a055 panic brake assist faulted";
CM_ SG_ 983 IDB_a056_fadeCompensationFaulted "IDB ECU: a056 fade compensation faulted";
CM_ SG_ 983 IDB_a057_bdwRequestInvalid "IDB ECU: a057 bdw request invalid";
CM_ SG_ 983 IDB_a058_scmFaulted "IDB ECU: a058 scm faulted";
CM_ SG_ 983 IDB_a059_cdpFaulted "IDB ECU: a059 cdp faulted";
CM_ SG_ 983 IDB_a060_RCUstatusDLC "IDB ECU: a060 RC ustatus DLC";
CM_ SG_ 983 IDB_a061_RCUstatusChecksum "IDB ECU: a061 RC ustatus checksum";
CM_ SG_ 983 IDB_a062_RCUstatusCounter "IDB ECU: a062 RC ustatus counter";
CM_ SG_ 983 IDB_a063_RCUactuationDLC "IDB ECU: a063 RC uactuation DLC";
CM_ SG_ 983 IDB_a064_RCUactuationChecksum "IDB ECU: a064 RC uactuation checksum";
CM_ SG_ 983 IDB_a065_RCUactuationCounter "IDB ECU: a065 RC uactuation counter";
CM_ SG_ 983 IDB_a066_DIFtorqueDLC "IDB ECU: a066 DI ftorque DLC";
CM_ SG_ 983 IDB_a067_DIFtorqueChecksum "IDB ECU: a067 DI ftorque checksum";
CM_ SG_ 983 IDB_a068_DIFtorqueCounter "IDB ECU: a068 DI ftorque counter";
CM_ SG_ 983 IDB_a069_DIchassisControlDLC "IDB ECU: a069 d ichassis control DLC";
CM_ SG_ 983 IDB_a070_DIchassisControlChecksu "IDB ECU: a070 d ichassis control checksum";
CM_ SG_ 983 IDB_a071_DIchassisControlCounter "IDB ECU: a071 d ichassis control counter";
CM_ SG_ 983 IDB_a072_DIsystemStatusDLC "IDB ECU: a072 d isystem status DLC";
CM_ SG_ 983 IDB_a073_DIsystemStatusChecksum "IDB ECU: a073 d isystem status checksum";
CM_ SG_ 983 IDB_a074_DIsystemStatusCounter "IDB ECU: a074 d isystem status counter";
CM_ SG_ 983 IDB_a075_DIRtorqueDLC "IDB ECU: a075 DI rtorque DLC";
CM_ SG_ 983 IDB_a076_DIRtorqueChecksum "IDB ECU: a076 DI rtorque checksum";
CM_ SG_ 983 IDB_a077_DIRtorqueCounter "IDB ECU: a077 DI rtorque counter";
CM_ SG_ 983 IDB_a078_DIvdcLeftDLC "IDB ECU: a078 d ivdc left DLC";
CM_ SG_ 983 IDB_a079_DIvdcLeftChecksum "IDB ECU: a079 d ivdc left checksum";
CM_ SG_ 983 IDB_a080_DIvdcLeftCounter "IDB ECU: a080 d ivdc left counter";
CM_ SG_ 983 IDB_a081_DIvdcRightDLC "IDB ECU: a081 d ivdc right DLC";
CM_ SG_ 983 IDB_a082_DIvdcRightChecksum "IDB ECU: a082 d ivdc right checksum";
CM_ SG_ 983 IDB_a083_DIvdcRightCounter "IDB ECU: a083 d ivdc right counter";
CM_ SG_ 983 IDB_a084_EPAS3PsysStatusDLC "IDB ECU: a084 EPAS3 psys status DLC";
CM_ SG_ 983 IDB_a085_EPAS3PsysStatusChecksum "IDB ECU: a085 EPAS3 psys status checksum";
CM_ SG_ 983 IDB_a086_EPAS3PsysStatusCounter "IDB ECU: a086 EPAS3 psys status counter";
CM_ SG_ 983 IDB_a087_PMstate2DLC "IDB ECU: a087 p mstate2 DLC";
CM_ SG_ 983 IDB_a088_PMstate2Checksum "IDB ECU: a088 p mstate2 checksum";
CM_ SG_ 983 IDB_a089_PMstate2Counter "IDB ECU: a089 p mstate2 counter";
CM_ SG_ 983 IDB_a090_RCMinertial1DLC "IDB ECU: a090 RC minertial1 DLC";
CM_ SG_ 983 IDB_a091_RCMinertial1Checksum "IDB ECU: a091 RC minertial1 checksum";
CM_ SG_ 983 IDB_a092_RCMinertial1Counter "IDB ECU: a092 RC minertial1 counter";
CM_ SG_ 983 IDB_a093_RCMinertial2DLC "IDB ECU: a093 RC minertial2 DLC";
CM_ SG_ 983 IDB_a094_RCMinertial2Checksum "IDB ECU: a094 RC minertial2 checksum";
CM_ SG_ 983 IDB_a095_RCMinertial2Counter "IDB ECU: a095 RC minertial2 counter";
CM_ SG_ 983 IDB_a096_VCFRONTLVPowerStateDLC "IDB ECU: a096 VCFRONTLV power state DLC";
CM_ SG_ 983 IDB_a097_VCFRONTLVPwrStChecksum "IDB ECU: a097 VCFRONTLV pwr st checksum";
CM_ SG_ 983 IDB_a098_VCFRONTLVPwrStCounter "IDB ECU: a098 VCFRONTLV pwr st counter";
CM_ SG_ 983 IDB_a099_RCMcollisionDLC "IDB ECU: a099 RC mcollision DLC";
CM_ SG_ 983 IDB_a100_RCMcollisionChecksum "IDB ECU: a100 RC mcollision checksum";
CM_ SG_ 983 IDB_a101_RCMcollisionCounter "IDB ECU: a101 RC mcollision counter";
CM_ SG_ 983 IDB_a102_bdwRequestActiveInvalid "IDB ECU: a102 bdw request active invalid";
CM_ SG_ 983 IDB_a103_DIfullTorquePathFaulted "IDB ECU: a103 d ifull torque path faulted";
CM_ SG_ 983 IDB_a104_DIaccelPosInvalid "IDB ECU: a104 d iaccel pos invalid";
CM_ SG_ 983 IDB_a105_DIgearInvalid "IDB ECU: a105 d igear invalid";
CM_ SG_ 983 IDB_a106_DIFtorqueInvalid "IDB ECU: a106 DI ftorque invalid";
CM_ SG_ 983 IDB_a107_DIRtorqueInvalid "IDB ECU: a107 DI rtorque invalid";
CM_ SG_ 983 IDB_a108_EPBstatusDLC "IDB ECU: a108 EP bstatus DLC";
CM_ SG_ 983 IDB_a109_BDWsignalInvalid "IDB ECU: a109 BD wsignal invalid";
CM_ SG_ 983 IDB_a110_EPBstatusCounter "IDB ECU: a110 EP bstatus counter";
CM_ SG_ 983 IDB_a111_EPBstatusChecksum "IDB ECU: a111 EP bstatus checksum";
CM_ SG_ 983 IDB_a112_yawRateInvalid "IDB ECU: a112 yaw rate invalid";
CM_ SG_ 983 IDB_a113_latAccelInvalid "IDB ECU: a113 lat accel invalid";
CM_ SG_ 983 IDB_a114_longAccelInvalid "IDB ECU: a114 long accel invalid";
CM_ SG_ 983 IDB_a115_VCFRONTespLvStInvalid "IDB ECU: a115 VCFRON tesp lv st invalid";
CM_ SG_ 983 IDB_a116_VCFRONTsensorsDLC "IDB ECU: a116 VCFRON tsensors DLC";
CM_ SG_ 983 IDB_a117_VCLEFTepbmStatusDLC "IDB ECU: a117 VCLEF tepbm status DLC";
CM_ SG_ 983 IDB_a118_VCLEFTepbmStatusCounter "IDB ECU: a118 VCLEF tepbm status counter";
CM_ SG_ 983 IDB_a119_VCLEFTepbmStatusChecksu "IDB ECU: a119 VCLEF tepbm status checksum";
CM_ SG_ 983 IDB_a120_EPAS3Pinvalid "IDB ECU: a120 EPAS3 pinvalid";
CM_ SG_ 983 IDB_a121_dynoModeActive "IDB ECU: a121 dyno mode active";
CM_ SG_ 983 IDB_a122_DIFtorqueCommandInvalid "IDB ECU: a122 DI ftorque command invalid";
CM_ SG_ 983 IDB_a123_DIRtorqueCommandInvalid "IDB ECU: a123 DI rtorque command invalid";
CM_ SG_ 983 IDB_a124_VCFRONTtempInvalid "IDB ECU: a124 VCFRON ttemp invalid";
CM_ SG_ 983 IDB_a125_PMvdcCmdStateInvalid "IDB ECU: a125 p mvdc cmd state invalid";
CM_ SG_ 983 IDB_a126_DItorqueRequestInvalid "IDB ECU: a126 d itorque request invalid";
CM_ SG_ 983 IDB_a127_brakeFluidLevelInvalid "IDB ECU: a127 brake fluid level invalid";
CM_ SG_ 983 IDB_a128_reserved1 "IDB ECU: a128 reserved1";
CM_ SG_ 983 IDB_a129_RCUinputRodStrokeInvali "IDB ECU: a129 RC uinput rod stroke invalid";
CM_ SG_ 983 IDB_a130_DIfullTorqueRequestInva "IDB ECU: a130 d ifull torque request invalid";
CM_ SG_ 983 IDB_a131_DIfullTorquePathActive "IDB ECU: a131 d ifull torque path active";
CM_ SG_ 983 IDB_a132_RCUinputRodStrokeQFInva "IDB ECU: a132 RC uinput rod stroke QF invalid";
CM_ SG_ 983 IDB_a133_DIbrakeCommandDLC "IDB ECU: a133 d ibrake command DLC";
CM_ SG_ 983 IDB_a134_DIbrakeCommandCounter "IDB ECU: a134 d ibrake command counter";
CM_ SG_ 983 IDB_a135_DIbrakeCommandChecksum "IDB ECU: a135 d ibrake command checksum";
CM_ SG_ 983 IDB_a136_RCUptsCalMissing "IDB ECU: a136 RC upts cal missing";
CM_ SG_ 983 IDB_a137_VCLEFTcdpRequestInvalid "IDB ECU: a137 VCLEF tcdp request invalid";
CM_ SG_ 983 IDB_a138_DIbrakeTorqueCommandAnd "IDB ECU: a138 d ibrake torque command and flag mismatch";
CM_ SG_ 983 IDB_a139_DIbrakeTorqueCommandFul "IDB ECU: a139 d ibrake torque command full SNA";
CM_ SG_ 983 IDB_a140_PMbrakePedalCmdQFInvali "IDB ECU: a140 p mbrake pedal cmd QF invalid";
CM_ SG_ 983 IDB_a141_DIbrakeTorqueCommandFul "IDB ECU: a141 d ibrake torque command full too low";
CM_ SG_ 983 IDB_a142_PMebrCmdStateInvalid "IDB ECU: a142 p mebr cmd state invalid";
CM_ SG_ 983 IDB_a143_factoryModeActive "IDB ECU: a143 factory mode active";
CM_ SG_ 983 IDB_a144_hydraulicPushthroughAct "IDB ECU: a144 hydraulic pushthrough active";
CM_ BO_ 828 "IDB ECU message: info";
CM_ SG_ 828 IDB_infoIndex "IDB ECU: info index";
CM_ SG_ 828 IDB_infoPcbaID "IDB ECU: info pcba ID";
CM_ SG_ 828 IDB_infoAssemblyID "IDB ECU: info assembly ID";
CM_ SG_ 828 IDB_infoUsageID "IDB ECU: info usage ID";
CM_ SG_ 828 IDB_infoSubUsageID "IDB ECU: info sub usage ID";
CM_ BO_ 1429 "Occupant classification system message: alert log";
CM_ SG_ 1429 OCS1P_alertID "Occupant classification system: alert ID";
CM_ SG_ 1429 OCS1P_alertState "Occupant classification system: alert state";
CM_ SG_ 1429 OCS1P_a121_sandwichFreq "Occupant classification system: a121 sandwich freq";
CM_ SG_ 1429 OCS1P_a122_sandwichFreq "Occupant classification system: a122 sandwich freq";
CM_ SG_ 1429 OCS1P_a123_sandwichFreq "Occupant classification system: a123 sandwich freq";
CM_ SG_ 1429 OCS1P_a124_cushionSelfFreq "Occupant classification system: a124 cushion self freq";
CM_ SG_ 1429 OCS1P_a125_cushionSelfFreq "Occupant classification system: a125 cushion self freq";
CM_ SG_ 1429 OCS1P_a126_cushionSelfFreq "Occupant classification system: a126 cushion self freq";
CM_ SG_ 1429 OCS1P_a127_seatbackSelfFreq "Occupant classification system: a127 seatback self freq";
CM_ SG_ 1429 OCS1P_a128_seatbackSelfFreq "Occupant classification system: a128 seatback self freq";
CM_ SG_ 1429 OCS1P_a129_seatbackSelfFreq "Occupant classification system: a129 seatback self freq";
CM_ SG_ 1429 OCS1P_a130_sandwichNoCalib "Occupant classification system: a130 sandwich no calib";
CM_ SG_ 1429 OCS1P_a131_cushionSelfNoCalib "Occupant classification system: a131 cushion self no calib";
CM_ SG_ 1429 OCS1P_a132_seatbackSelfNoCalib "Occupant classification system: a132 seatback self no calib";
CM_ SG_ 1429 OCS1P_a133_sandwichBadCalib "Occupant classification system: a133 sandwich bad calib";
CM_ SG_ 1429 OCS1P_a134_uninitializedCalib "Occupant classification system: a134 uninitialized calib";
CM_ SG_ 1429 OCS1P_a135_tempNoCalib "Occupant classification system: a135 temp no calib";
CM_ SG_ 1429 OCS1P_a140_tempInvalidCalib "Occupant classification system: a140 temp invalid calib";
CM_ SG_ 1429 OCS1P_a141_humidityInvalidCalib "Occupant classification system: a141 humidity invalid calib";
CM_ SG_ 1429 OCS1P_a142_tempHumidityInvalid "Occupant classification system: a142 temp humidity invalid";
CM_ SG_ 1429 OCS1P_a143_mismatchPassAirbag "Occupant classification system: a143 mismatch pass airbag";
CM_ SG_ 1429 OCS1P_a144_mismatchCarRegion "Occupant classification system: a144 mismatch car region";
CM_ BO_ 767 "Occupant classification system message: alert matrix";
CM_ SG_ 767 OCS1P_matrixIndex "Occupant classification system: matrix index";
CM_ SG_ 767 OCS1P_w015_NVMMAlert "Occupant classification system: w015 NVMM alert";
CM_ SG_ 767 OCS1P_w121_sandwichOpen "Occupant classification system: w121 sandwich open";
CM_ SG_ 767 OCS1P_w122_sandwichLow "Occupant classification system: w122 sandwich low";
CM_ SG_ 767 OCS1P_w123_sandwichShort "Occupant classification system: w123 sandwich short";
CM_ SG_ 767 OCS1P_w124_cushionSelfOpen "Occupant classification system: w124 cushion self open";
CM_ SG_ 767 OCS1P_w125_cushionSelfLow "Occupant classification system: w125 cushion self low";
CM_ SG_ 767 OCS1P_w126_cushionSelfShort "Occupant classification system: w126 cushion self short";
CM_ SG_ 767 OCS1P_w127_seatbackSelfOpen "Occupant classification system: w127 seatback self open";
CM_ SG_ 767 OCS1P_w128_seatbackSelfLow "Occupant classification system: w128 seatback self low";
CM_ SG_ 767 OCS1P_w129_seatbackSelfShort "Occupant classification system: w129 seatback self short";
CM_ SG_ 767 OCS1P_w130_sandwichNoCalib "Occupant classification system: w130 sandwich no calib";
CM_ SG_ 767 OCS1P_w131_cushionSelfNoCalib "Occupant classification system: w131 cushion self no calib";
CM_ SG_ 767 OCS1P_w132_seatbackSelfNoCalib "Occupant classification system: w132 seatback self no calib";
CM_ SG_ 767 OCS1P_w133_sandwichBadCalib "Occupant classification system: w133 sandwich bad calib";
CM_ SG_ 767 OCS1P_w134_uninitializedCalib "Occupant classification system: w134 uninitialized calib";
CM_ SG_ 767 OCS1P_w135_tempNoCalib "Occupant classification system: w135 temp no calib";
CM_ SG_ 767 OCS1P_w136_cushionSelfDutyLow "Occupant classification system: w136 cushion self duty low";
CM_ SG_ 767 OCS1P_w137_cushionSelfDutyHigh "Occupant classification system: w137 cushion self duty high";
CM_ SG_ 767 OCS1P_w138_seatbackSelfDutyLow "Occupant classification system: w138 seatback self duty low";
CM_ SG_ 767 OCS1P_w139_seatbackSelfDutyHigh "Occupant classification system: w139 seatback self duty high";
CM_ SG_ 767 OCS1P_w140_tempInvalidCalib "Occupant classification system: w140 temp invalid calib";
CM_ SG_ 767 OCS1P_w141_humidityInvalidCalib "Occupant classification system: w141 humidity invalid calib";
CM_ SG_ 767 OCS1P_w142_tempHumidityInvalid "Occupant classification system: w142 temp humidity invalid";
CM_ SG_ 767 OCS1P_w143_mismatchPassAirbag "Occupant classification system: w143 mismatch pass airbag";
CM_ SG_ 767 OCS1P_w144_mismatchCarRegion "Occupant classification system: w144 mismatch car region";
CM_ SG_ 767 OCS1P_w145_rebaselineTriggered "Occupant classification system: w145 rebaseline triggered";
CM_ SG_ 767 OCS1P_w148_classificationMismatc "Occupant classification system: w148 classification mismatch";
CM_ SG_ 767 OCS1P_w150_rbEntryTriggered "Occupant classification system: w150 rb entry triggered";
CM_ SG_ 767 OCS1P_w151_rbEntryExited "Occupant classification system: w151 rb entry exited";
CM_ SG_ 767 OCS1P_w152_rbExit1Triggered "Occupant classification system: w152 rb exit1 triggered";
CM_ SG_ 767 OCS1P_w153_rbExit1Exited "Occupant classification system: w153 rb exit1 exited";
CM_ SG_ 767 OCS1P_w154_rbExit2Exited1 "Occupant classification system: w154 rb exit2 exited1";
CM_ SG_ 767 OCS1P_w155_rbExit2Exited2 "Occupant classification system: w155 rb exit2 exited2";
CM_ BO_ 766 "Occupant classification system message: info";
CM_ SG_ 766 OCS1P_infoIndex "Occupant classification system: info index";
CM_ SG_ 766 OCS1P_infoBuildType "Occupant classification system: info build type";
CM_ SG_ 766 OCS1P_infoBuildConfigID "Occupant classification system: info build config ID";
CM_ SG_ 766 OCS1P_infoHardwareID "Occupant classification system: info hardware ID";
CM_ SG_ 766 OCS1P_infoComponentID "Occupant classification system: info component ID";
CM_ SG_ 766 OCS1P_infoPcbaID "Occupant classification system: info pcba ID";
CM_ SG_ 766 OCS1P_infoAssemblyID "Occupant classification system: info assembly ID";
CM_ SG_ 766 OCS1P_infoUsageID "Occupant classification system: info usage ID";
CM_ SG_ 766 OCS1P_infoSubUsageID "Occupant classification system: info sub usage ID";
CM_ SG_ 766 OCS1P_infoApplicationCRC "Occupant classification system: info application CRC";
CM_ SG_ 766 OCS1P_infoBootSvnRev "Occupant classification system: info boot svn rev";
CM_ SG_ 766 OCS1P_infoAppGitHashBytes "Occupant classification system: info app git hash bytes";
CM_ SG_ 766 OCS1P_infoBootGitHashBytes "Occupant classification system: info boot git hash bytes";
CM_ SG_ 766 OCS1P_infoPlatformType "Occupant classification system: info platform type";
CM_ SG_ 766 OCS1P_infoBootUdsProtoVersion "Occupant classification system: info boot uds proto version";
CM_ SG_ 766 OCS1P_infoBootloaderCRC "Occupant classification system: info bootloader CRC";
CM_ BO_ 771 "Occupant classification system message: status";
CM_ SG_ 771 OCS1P_occupantClassification "Occupant Classification (Filtered); raw 255 = signal not available (SNA)";
CM_ SG_ 771 OCS1P_occupantClassificationQF "Occupant classification system: occupant classification QF";
CM_ SG_ 771 OCS1P_occupiedState "Passenger seat occupied State; raw 3 = signal not available (SNA)";
CM_ SG_ 771 OCS1P_triggerSnapshot "Occupant classification system: trigger snapshot";
CM_ SG_ 771 OCS1P_occupantClassificationRaw "Occupant classification system: occupant classification raw; raw 7 = signal not available (SNA)";
CM_ SG_ 771 OCS1P_occupantClassificationSelf "Occupant classification system: occupant classification self; raw 7 = signal not available (SNA)";
CM_ SG_ 771 OCS1P_occupantClassificationRawC "Occupant classification system: occupant classification raw cap; raw 7 = signal not available (SNA)";
CM_ SG_ 771 OCS1P_occupantClassificationCap "Occupant classification system: occupant classification cap; raw 7 = signal not available (SNA)";
CM_ SG_ 771 OCS1P_classificationHeld "Whether occupant classification is filtered due to door state or stability based on frequency";
CM_ SG_ 771 OCS1P_cushionStable "Whether frequency reading is unchanging of Cushion Self sensor";
CM_ SG_ 771 OCS1P_classificationExtHold "Occupant classification request to be filtered due to door state";
CM_ SG_ 771 OCS1P_classificationHoldState "Occupant classification system: classification hold state";
CM_ SG_ 771 OCS1P_classificationVariant "The combination of sensors used to classify occupant";
CM_ SG_ 771 OCS1P_sandwichDisabled "Cushion mutual sensor disabled by calibration";
CM_ SG_ 771 OCS1P_noSandwichType "Configuration set in factory or service that determines logic around uninstalled sandwich";
CM_ SG_ 771 OCS1P_sandwichBoundaryType "Occupant classification system: sandwich boundary type";
CM_ SG_ 771 OCS1P_sbrBoundaryType "Occupant classification system: sbr boundary type";
CM_ SG_ 771 OCS1P_occupiedStateCap "Occupant classification system: occupied state cap; raw 3 = signal not available (SNA)";
CM_ SG_ 771 OCS1P_seatbackStable "Whether frequency reading is unchanging of Seatback Self sensor";
CM_ SG_ 771 OCS1P_sandwichStable "Whether frequency reading is unchanging of Cushion Mutual sensor";
CM_ SG_ 771 OCS1P_cushionStableCap "Occupant classification system: cushion stable cap";
CM_ SG_ 771 OCS1P_seatbackStableCap "Occupant classification system: seatback stable cap";
CM_ SG_ 771 OCS1P_classificationHeldCap "Occupant classification system: classification held cap";
CM_ SG_ 771 OCS1P_statusCounter "Occupant classification system: status counter";
CM_ SG_ 771 OCS1P_statusChecksum "Occupant classification system: status checksum";
CM_ BO_ 772 "PMF ECU message: alert matrix1";
CM_ SG_ 772 PMF_a001_absoluteTorque "PMF ECU: a001 absolute torque";
CM_ SG_ 772 PMF_a002_excessiveAccelTorque "PMF ECU: a002 excessive accel torque";
CM_ SG_ 772 PMF_a003_excessiveReversalTorque "PMF ECU: a003 excessive reversal torque";
CM_ SG_ 772 PMF_a004_excessiveDecelTorque "PMF ECU: a004 excessive decel torque";
CM_ SG_ 772 PMF_a005_torqueInNeutralOrPark "PMF ECU: a005 torque in neutral or park";
CM_ SG_ 772 PMF_a006_underTorqueCheck "PMF ECU: a006 under torque check";
CM_ SG_ 772 PMF_a008_memoryError "PMF ECU: a008 memory error";
CM_ SG_ 772 PMF_a010_diMIA "PMF ECU: a010 di MIA";
CM_ SG_ 772 PMF_a011_phaseCurrentIrrational "PMF ECU: a011 phase current irrational";
CM_ SG_ 772 PMF_a012_canDataBusA "PMF ECU: a012 can data bus a";
CM_ SG_ 772 PMF_a013_canHardwareBusA "PMF ECU: a013 can hardware bus a";
CM_ SG_ 772 PMF_a017_brakeMIA "PMF ECU: a017 brake MIA";
CM_ SG_ 772 PMF_a018_encoderIrrational "PMF ECU: a018 encoder irrational";
CM_ SG_ 772 PMF_a019_statorTempIrrational "PMF ECU: a019 stator temp irrational";
CM_ SG_ 772 PMF_a025_unintendedReset "PMF ECU: a025 unintended reset";
CM_ SG_ 772 PMF_a026_diHeartBeatMIA "PMF ECU: a026 di heart beat MIA";
CM_ SG_ 772 PMF_a027_torqueEstimationOutOfBo "PMF ECU: a027 torque estimation out of bounds";
CM_ SG_ 772 PMF_a028_torqueCmdError "PMF ECU: a028 torque cmd error";
CM_ SG_ 772 PMF_a031_highStackUsage "PMF ECU: a031 high stack usage";
CM_ SG_ 772 PMF_a032_registerConfigError "PMF ECU: a032 register config error";
CM_ SG_ 772 PMF_a033_selfTest "PMF ECU: a033 self test";
CM_ SG_ 772 PMF_a034_trqCrossCheck "PMF ECU: a034 trq cross check";
CM_ SG_ 772 PMF_a035_udsTransactionInitiated "PMF ECU: a035 uds transaction initiated";
CM_ SG_ 772 PMF_a036_preWatchdog "PMF ECU: a036 pre watchdog";
CM_ SG_ 772 PMF_a037_hvpMIA "PMF ECU: a037 hvp MIA";
CM_ SG_ 772 PMF_a039_disMIA "PMF ECU: a039 dis MIA";
CM_ SG_ 772 PMF_a040_pmMIA "PMF ECU: a040 pm MIA";
CM_ SG_ 772 PMF_a042_gtwMIA "PMF ECU: a042 gtw MIA";
CM_ SG_ 772 PMF_a045_motorMovementDetected "PMF ECU: a045 motor movement detected";
CM_ SG_ 772 PMF_a053_vcfrontMIA "PMF ECU: a053 vcfront MIA";
CM_ SG_ 772 PMF_a054_uiMIA "PMF ECU: a054 ui MIA";
CM_ SG_ 772 PMF_a055_resolver "PMF ECU: a055 resolver";
CM_ SG_ 772 PMF_a056_canHardwareBusB "PMF ECU: a056 can hardware bus b";
CM_ SG_ 772 PMF_a057_canDataBusB "PMF ECU: a057 can data bus b";
CM_ SG_ 772 PMF_a058_measuredHvilCurrentFroz "PMF ECU: a058 measured hvil current frozen";
CM_ SG_ 772 PMF_a061_DIPMVersionMismatch "PMF ECU: a061 DIPM version mismatch";
CM_ SG_ 772 PMF_a062_eccError "PMF ECU: a062 ecc error";
CM_ SG_ 772 PMF_a064_torqueIntervention "PMF ECU: a064 torque intervention";
CM_ BO_ 2022 "PMF ECU message: alert matrix2";
CM_ SG_ 2022 PMF_a080_exceptionPrefetchAbort "PMF ECU: a080 exception prefetch abort";
CM_ SG_ 2022 PMF_a081_exceptionDataAbort "PMF ECU: a081 exception data abort";
CM_ SG_ 2022 PMF_a082_exceptionDataAbort2 "PMF ECU: a082 exception data abort2";
CM_ SG_ 2022 PMF_a083_ahbWriteError "PMF ECU: a083 ahb write error";
CM_ SG_ 2022 PMF_a084_exceptionMpuFirewall "PMF ECU: a084 exception mpu firewall";
CM_ SG_ 2022 PMF_a086_exceptionUndefinedInstr "PMF ECU: a086 exception undefined instruction";
CM_ SG_ 2022 PMF_a092_xtalOscillator "PMF ECU: a092 xtal oscillator";
CM_ SG_ 2022 PMF_a094_safetyICWarn "PMF ECU: a094 safety IC warn";
CM_ SG_ 2022 PMF_a095_safetyICFault "PMF ECU: a095 safety IC fault";
CM_ SG_ 2022 PMF_a096_safetyICDebug "PMF ECU: a096 safety IC debug";
CM_ SG_ 2022 PMF_a097_lowFlowAlmostTripped "PMF ECU: a097 low flow almost tripped";
CM_ SG_ 2022 PMF_a100_diTraceInfo1 "PMF ECU: a100 di trace info1";
CM_ SG_ 2022 PMF_a121_unintendedReset2 "PMF ECU: a121 unintended reset2";
CM_ BO_ 902 "PMR ECU message: alert matrix1";
CM_ SG_ 902 PMR_a001_absoluteTorque "PMR ECU: a001 absolute torque";
CM_ SG_ 902 PMR_a002_excessiveAccelTorque "PMR ECU: a002 excessive accel torque";
CM_ SG_ 902 PMR_a003_excessiveReversalTorque "PMR ECU: a003 excessive reversal torque";
CM_ SG_ 902 PMR_a004_excessiveDecelTorque "PMR ECU: a004 excessive decel torque";
CM_ SG_ 902 PMR_a005_torqueInNeutralOrPark "PMR ECU: a005 torque in neutral or park";
CM_ SG_ 902 PMR_a006_underTorqueCheck "PMR ECU: a006 under torque check";
CM_ SG_ 902 PMR_a008_memoryError "PMR ECU: a008 memory error";
CM_ SG_ 902 PMR_a010_diMIA "PMR ECU: a010 di MIA";
CM_ SG_ 902 PMR_a011_phaseCurrentIrrational "PMR ECU: a011 phase current irrational";
CM_ SG_ 902 PMR_a012_canDataBusA "PMR ECU: a012 can data bus a";
CM_ SG_ 902 PMR_a013_canHardwareBusA "PMR ECU: a013 can hardware bus a";
CM_ SG_ 902 PMR_a017_brakeMIA "PMR ECU: a017 brake MIA";
CM_ SG_ 902 PMR_a018_encoderIrrational "PMR ECU: a018 encoder irrational";
CM_ SG_ 902 PMR_a019_statorTempIrrational "PMR ECU: a019 stator temp irrational";
CM_ SG_ 902 PMR_a025_unintendedReset "PMR ECU: a025 unintended reset";
CM_ SG_ 902 PMR_a026_diHeartBeatMIA "PMR ECU: a026 di heart beat MIA";
CM_ SG_ 902 PMR_a027_torqueEstimationOutOfBo "PMR ECU: a027 torque estimation out of bounds";
CM_ SG_ 902 PMR_a028_torqueCmdError "PMR ECU: a028 torque cmd error";
CM_ SG_ 902 PMR_a031_highStackUsage "PMR ECU: a031 high stack usage";
CM_ SG_ 902 PMR_a032_registerConfigError "PMR ECU: a032 register config error";
CM_ SG_ 902 PMR_a033_selfTest "PMR ECU: a033 self test";
CM_ SG_ 902 PMR_a034_trqCrossCheck "PMR ECU: a034 trq cross check";
CM_ SG_ 902 PMR_a035_udsTransactionInitiated "PMR ECU: a035 uds transaction initiated";
CM_ SG_ 902 PMR_a036_preWatchdog "PMR ECU: a036 pre watchdog";
CM_ SG_ 902 PMR_a037_hvpMIA "PMR ECU: a037 hvp MIA";
CM_ SG_ 902 PMR_a039_disMIA "PMR ECU: a039 dis MIA";
CM_ SG_ 902 PMR_a040_pmMIA "PMR ECU: a040 pm MIA";
CM_ SG_ 902 PMR_a042_gtwMIA "PMR ECU: a042 gtw MIA";
CM_ SG_ 902 PMR_a045_motorMovementDetected "PMR ECU: a045 motor movement detected";
CM_ SG_ 902 PMR_a053_vcfrontMIA "PMR ECU: a053 vcfront MIA";
CM_ SG_ 902 PMR_a054_uiMIA "PMR ECU: a054 ui MIA";
CM_ SG_ 902 PMR_a055_resolver "PMR ECU: a055 resolver";
CM_ SG_ 902 PMR_a056_canHardwareBusB "PMR ECU: a056 can hardware bus b";
CM_ SG_ 902 PMR_a057_canDataBusB "PMR ECU: a057 can data bus b";
CM_ SG_ 902 PMR_a058_measuredHvilCurrentFroz "PMR ECU: a058 measured hvil current frozen";
CM_ SG_ 902 PMR_a061_DIPMVersionMismatch "PMR ECU: a061 DIPM version mismatch";
CM_ SG_ 902 PMR_a062_eccError "PMR ECU: a062 ecc error";
CM_ SG_ 902 PMR_a064_torqueIntervention "PMR ECU: a064 torque intervention";
CM_ BO_ 928 "PMR ECU message: alert matrix2";
CM_ SG_ 928 PMR_a080_exceptionPrefetchAbort "PMR ECU: a080 exception prefetch abort";
CM_ SG_ 928 PMR_a081_exceptionDataAbort "PMR ECU: a081 exception data abort";
CM_ SG_ 928 PMR_a082_exceptionDataAbort2 "PMR ECU: a082 exception data abort2";
CM_ SG_ 928 PMR_a083_ahbWriteError "PMR ECU: a083 ahb write error";
CM_ SG_ 928 PMR_a084_exceptionMpuFirewall "PMR ECU: a084 exception mpu firewall";
CM_ SG_ 928 PMR_a086_exceptionUndefinedInstr "PMR ECU: a086 exception undefined instruction";
CM_ SG_ 928 PMR_a092_xtalOscillator "PMR ECU: a092 xtal oscillator";
CM_ SG_ 928 PMR_a094_safetyICWarn "PMR ECU: a094 safety IC warn";
CM_ SG_ 928 PMR_a095_safetyICFault "PMR ECU: a095 safety IC fault";
CM_ SG_ 928 PMR_a096_safetyICDebug "PMR ECU: a096 safety IC debug";
CM_ SG_ 928 PMR_a097_lowFlowAlmostTripped "PMR ECU: a097 low flow almost tripped";
CM_ SG_ 928 PMR_a100_diTraceInfo1 "PMR ECU: a100 di trace info1";
CM_ SG_ 928 PMR_a101_hwVoltageMonitorTrip "PMR ECU: a101 hw voltage monitor trip";
CM_ SG_ 928 PMR_a121_unintendedReset2 "PMR ECU: a121 unintended reset2";
CM_ BO_ 900 "PM ECU message: alert matrix1";
CM_ SG_ 900 PM_a001_absoluteTorque "PM ECU: a001 absolute torque";
CM_ SG_ 900 PM_a002_excessiveAccelTorque "PM ECU: a002 excessive accel torque";
CM_ SG_ 900 PM_a003_excessiveReversalTorque "PM ECU: a003 excessive reversal torque";
CM_ SG_ 900 PM_a004_excessiveDecelTorque "PM ECU: a004 excessive decel torque";
CM_ SG_ 900 PM_a005_torqueInNeutralOrPark "PM ECU: a005 torque in neutral or park";
CM_ SG_ 900 PM_a006_inconsistentDIGear "PM ECU: a006 inconsistent DI gear";
CM_ SG_ 900 PM_a007_ibstMIA "PM ECU: a007 ibst MIA";
CM_ SG_ 900 PM_a008_memoryError "PM ECU: a008 memory error";
CM_ SG_ 900 PM_a009_espMIA "PM ECU: a009 esp MIA";
CM_ SG_ 900 PM_a010_diMIA "PM ECU: a010 di MIA";
CM_ SG_ 900 PM_a011_systemHvilNotClosed "PM ECU: a011 system hvil not closed";
CM_ SG_ 900 PM_a012_canDataBusA "PM ECU: a012 can data bus a";
CM_ SG_ 900 PM_a013_canHardwareBusA "PM ECU: a013 can hardware bus a";
CM_ SG_ 900 PM_a014_accelPedalError "PM ECU: a014 accel pedal error";
CM_ SG_ 900 PM_a015_shifterMIA "PM ECU: a015 shifter MIA";
CM_ SG_ 900 PM_a016_bbMIA "PM ECU: a016 bb MIA";
CM_ SG_ 900 PM_a017_brakeMIA "PM ECU: a017 brake MIA";
CM_ SG_ 900 PM_a019_vehicleSpeedQFDiagnostic "PM ECU: a019 vehicle speed QF diagnostic";
CM_ SG_ 900 PM_a021_difMIA "PM ECU: a021 dif MIA";
CM_ SG_ 900 PM_a022_dirMIA "PM ECU: a022 dir MIA";
CM_ SG_ 900 PM_a023_cruiseInhibit "PM ECU: a023 cruise inhibit";
CM_ SG_ 900 PM_a024_brakeIrrational "PM ECU: a024 brake irrational";
CM_ SG_ 900 PM_a025_unintendedReset "PM ECU: a025 unintended reset";
CM_ SG_ 900 PM_a026_diHeartBeatMIA "PM ECU: a026 di heart beat MIA";
CM_ SG_ 900 PM_a028_torqueCmdError "PM ECU: a028 torque cmd error";
CM_ SG_ 900 PM_a029_cruiseRollback "PM ECU: a029 cruise rollback";
CM_ SG_ 900 PM_a030_inconsistentAebState "PM ECU: a030 inconsistent aeb state";
CM_ SG_ 900 PM_a031_highStackUsage "PM ECU: a031 high stack usage";
CM_ SG_ 900 PM_a032_registerConfigError "PM ECU: a032 register config error";
CM_ SG_ 900 PM_a033_appMIA "PM ECU: a033 app MIA";
CM_ SG_ 900 PM_a034_trqCrossCheck "PM ECU: a034 trq cross check";
CM_ SG_ 900 PM_a035_udsTransactionInitiated "PM ECU: a035 uds transaction initiated";
CM_ SG_ 900 PM_a036_preWatchdog "PM ECU: a036 pre watchdog";
CM_ SG_ 900 PM_a038_inconsistentTorqueSign "PM ECU: a038 inconsistent torque sign";
CM_ SG_ 900 PM_a039_disMIA "PM ECU: a039 dis MIA";
CM_ SG_ 900 PM_a040_latLinkLooseBoltDetected "PM ECU: a040 lat link loose bolt detected debug";
CM_ SG_ 900 PM_a041_dasMIA "PM ECU: a041 das MIA";
CM_ SG_ 900 PM_a042_gtwMIA "PM ECU: a042 gtw MIA";
CM_ SG_ 900 PM_a043_inconsistentConfig "PM ECU: a043 inconsistent config";
CM_ SG_ 900 PM_a044_ebrIntervention "PM ECU: a044 ebr intervention";
CM_ SG_ 900 PM_a045_regenBackfillInterventio "PM ECU: a045 regen backfill intervention";
CM_ SG_ 900 PM_a046_inconsVehicleHoldState "PM ECU: a046 incons vehicle hold state";
CM_ SG_ 900 PM_a047_inconsAutoparkState "PM ECU: a047 incons autopark state";
CM_ SG_ 900 PM_a048_stabilityControlInhibit "PM ECU: a048 stability control inhibit";
CM_ SG_ 900 PM_a049_stbCtrlInWrongDir "PM ECU: a049 stb ctrl in wrong dir";
CM_ SG_ 900 PM_a050_excessiveStbCtrlTrq "PM ECU: a050 excessive stb ctrl trq";
CM_ SG_ 900 PM_a051_unintDecelStbCtrl "PM ECU: a051 unint decel stb ctrl";
CM_ SG_ 900 PM_a052_stbCtrlDrvrDecelCflct "PM ECU: a052 stb ctrl drvr decel cflct";
CM_ SG_ 900 PM_a053_vcfrontMIA "PM ECU: a053 vcfront MIA";
CM_ SG_ 900 PM_a054_uiMIA "PM ECU: a054 ui MIA";
CM_ SG_ 900 PM_a055_accelPedalSyncWarn "PM ECU: a055 accel pedal sync warn";
CM_ SG_ 900 PM_a056_canHardwareBusB "PM ECU: a056 can hardware bus b";
CM_ SG_ 900 PM_a057_canDataBusB "PM ECU: a057 can data bus b";
CM_ SG_ 900 PM_a058_cmpMIA "PM ECU: a058 cmp MIA";
CM_ SG_ 900 PM_a059_ptcMIA "PM ECU: a059 ptc MIA";
CM_ SG_ 900 PM_a060_onePedalDrivingInhibit "PM ECU: a060 one pedal driving inhibit";
CM_ SG_ 900 PM_a061_DIPMVersionMismatch "PM ECU: a061 DIPM version mismatch";
CM_ SG_ 900 PM_a062_eccError "PM ECU: a062 ecc error";
CM_ SG_ 900 PM_a063_torqueCommandInhibit "PM ECU: a063 torque command inhibit";
CM_ SG_ 900 PM_a064_torqueIntervention "PM ECU: a064 torque intervention";
BA_DEF_ BO_ "GenMsgCycleTime" INT 0 3600000;
BA_DEF_ BO_ "GenMsgSendType" ENUM "Cyclic","NotUsed","NotUsed","NotUsed","NotUsed","NotUsed","NotUsed","IfActive","NoMsgSendType","NotUsed";
BA_DEF_ BO_ "VFrameFormat" ENUM "StandardCAN","ExtendedCAN","reserved","J1939PG","reserved","reserved","reserved","reserved","reserved","reserved","reserved","reserved","reserved","reserved","StandardCAN_FD","ExtendedCAN_FD";
BA_DEF_ BO_ "CANFD_BRS" ENUM "0","1";
BA_DEF_ SG_ "GenSigSNA" STRING;
BA_DEF_ SG_ "SystemSignalLongSymbol" STRING;
BA_DEF_ SG_ "Confidence" ENUM "validated","plausible","layout-only","contradicted";
BA_DEF_DEF_ "GenMsgCycleTime" 0;
BA_DEF_DEF_ "GenMsgSendType" "NoMsgSendType";
BA_DEF_DEF_ "VFrameFormat" "StandardCAN";
BA_DEF_DEF_ "CANFD_BRS" "1";
BA_DEF_DEF_ "GenSigSNA" "";
BA_DEF_DEF_ "SystemSignalLongSymbol" "";
BA_DEF_DEF_ "Confidence" "layout-only";
BA_ "GenMsgCycleTime" BO_ 2047 100;
BA_ "GenMsgSendType" BO_ 2047 0;
BA_ "GenMsgCycleTime" BO_ 1638 250;
BA_ "GenMsgSendType" BO_ 1638 0;
BA_ "GenMsgCycleTime" BO_ 1080 100;
BA_ "GenMsgSendType" BO_ 1080 0;
BA_ "GenMsgCycleTime" BO_ 1656 100;
BA_ "GenMsgSendType" BO_ 1656 0;
BA_ "GenMsgCycleTime" BO_ 2033 2000;
BA_ "GenMsgSendType" BO_ 2033 0;
BA_ "GenMsgCycleTime" BO_ 60 2000;
BA_ "GenMsgSendType" BO_ 60 0;
BA_ "GenMsgCycleTime" BO_ 1370 250;
BA_ "GenMsgSendType" BO_ 1370 0;
BA_ "GenMsgCycleTime" BO_ 840 1000;
BA_ "GenMsgSendType" BO_ 840 0;
BA_ "GenMsgCycleTime" BO_ 1005 1000;
BA_ "GenMsgSendType" BO_ 1005 0;
BA_ "GenMsgCycleTime" BO_ 1112 100;
BA_ "GenMsgSendType" BO_ 1112 0;
BA_ "GenMsgCycleTime" BO_ 760 100;
BA_ "GenMsgSendType" BO_ 760 0;
BA_ "GenMsgCycleTime" BO_ 983 1000;
BA_ "GenMsgSendType" BO_ 983 0;
BA_ "GenMsgCycleTime" BO_ 828 10000;
BA_ "GenMsgSendType" BO_ 828 0;
BA_ "GenMsgCycleTime" BO_ 767 100;
BA_ "GenMsgSendType" BO_ 767 0;
BA_ "GenMsgCycleTime" BO_ 766 1000;
BA_ "GenMsgSendType" BO_ 766 0;
BA_ "GenMsgCycleTime" BO_ 771 500;
BA_ "GenMsgSendType" BO_ 771 0;
BA_ "GenMsgCycleTime" BO_ 772 1000;
BA_ "GenMsgSendType" BO_ 772 0;
BA_ "GenMsgCycleTime" BO_ 2022 1000;
BA_ "GenMsgSendType" BO_ 2022 0;
BA_ "GenMsgCycleTime" BO_ 902 1000;
BA_ "GenMsgSendType" BO_ 902 0;
BA_ "GenMsgCycleTime" BO_ 928 1000;
BA_ "GenMsgSendType" BO_ 928 0;
BA_ "GenMsgCycleTime" BO_ 900 1000;
BA_ "GenMsgSendType" BO_ 900 0;
BA_ "Confidence" SG_ 2047 GTW_deliveryStatus 0;
BA_ "Confidence" SG_ 2047 GTW_cabinPTCHeaterType 0;
BA_ "Confidence" SG_ 2047 GTW_rightHandDrive 0;
BA_ "Confidence" SG_ 2047 GTW_rearLightType 0;
BA_ "Confidence" SG_ 2047 GTW_headlamps 0;
BA_ "Confidence" SG_ 2047 GTW_country 0;
BA_ "Confidence" SG_ 2047 GTW_tireType 0;
BA_ "Confidence" SG_ 2047 GTW_roofGlassType 1;
BA_ "Confidence" SG_ 2047 GTW_dasHw 0;
BA_ "Confidence" SG_ 2047 GTW_brakeHWType 0;
BA_ "Confidence" SG_ 2047 GTW_restraintsHardwareType 0;
BA_ "Confidence" SG_ 2047 GTW_drivetrainType 0;
BA_ "Confidence" SG_ 2047 GTW_radarHeaterType 0;
BA_ "Confidence" SG_ 2047 GTW_exteriorTrimType 0;
BA_ "Confidence" SG_ 2047 GTW_frontSeatHeaters 0;
BA_ "Confidence" SG_ 2047 GTW_rearSeatHeaters 0;
BA_ "Confidence" SG_ 2047 GTW_eCallAntennaHW 0;
BA_ "Confidence" SG_ 2047 GTW_homelinkType 0;
BA_ "Confidence" SG_ 2047 GTW_vdcType 0;
BA_ "Confidence" SG_ 2047 GTW_memoryMirrors 0;
BA_ "Confidence" SG_ 2047 GTW_powerLiftgateType 0;
BA_ "Confidence" SG_ 2047 GTW_lumbarECUType 0;
BA_ "Confidence" SG_ 2047 GTW_rearSeatHeaterType 0;
BA_ "Confidence" SG_ 2047 GTW_auxParkLamps 0;
BA_ "Confidence" SG_ 2047 GTW_interiorCabinRadarType 0;
BA_ "Confidence" SG_ 2047 GTW_hvacPanelVaneType 0;
BA_ "Confidence" SG_ 2047 GTW_intakeAirFilterType 0;
BA_ "Confidence" SG_ 2047 GTW_eBuckConfig 0;
BA_ "Confidence" SG_ 2047 GTW_steeringHeaterEnabled 0;
BA_ "Confidence" SG_ 2047 GTW_activeHighBeam 0;
BA_ "Confidence" SG_ 2047 GTW_airbagCutoffSwitch 0;
BA_ "Confidence" SG_ 2047 GTW_intrusionSensorType 0;
BA_ "Confidence" SG_ 2047 GTW_spoilerType 0;
BA_ "Confidence" SG_ 2047 GTW_rearFogLamps 0;
BA_ "Confidence" SG_ 2047 GTW_roofType 0;
BA_ "Confidence" SG_ 2047 GTW_thirdRowSeatType 0;
BA_ "Confidence" SG_ 2047 GTW_autopilot 0;
BA_ "Confidence" SG_ 2047 GTW_superchargingAccess 0;
BA_ "Confidence" SG_ 2047 GTW_exteriorColor 0;
BA_ "Confidence" SG_ 2047 GTW_pedestrianWarningSound 0;
BA_ "Confidence" SG_ 2047 GTW_steeringColumnUJointType 0;
BA_ "Confidence" SG_ 2047 GTW_bPillarNFCParam 0;
BA_ "Confidence" SG_ 2047 GTW_interiorLighting 0;
BA_ "Confidence" SG_ 2047 GTW_headlightLevelerType 0;
BA_ "Confidence" SG_ 2047 GTW_numberHVILNodes 0;
BA_ "Confidence" SG_ 2047 GTW_mapRegion 0;
BA_ "Confidence" SG_ 2047 GTW_performancePackage 0;
BA_ "Confidence" SG_ 2047 GTW_chassisType 0;
BA_ "Confidence" SG_ 2047 GTW_airSuspension 0;
BA_ "Confidence" SG_ 2047 GTW_centerConsoleControllerType 0;
BA_ "Confidence" SG_ 2047 GTW_autopilotCameraType 0;
BA_ "Confidence" SG_ 2047 GTW_connectivityPackage 0;
BA_ "Confidence" SG_ 2047 GTW_plcSupportType 0;
BA_ "Confidence" SG_ 2047 GTW_packEnergy 0;
BA_ "Confidence" SG_ 2047 GTW_frontSeatReclinerHardware 0;
BA_ "Confidence" SG_ 2047 GTW_brakeLineSwitchType 0;
BA_ "Confidence" SG_ 2047 GTW_espValveType 0;
BA_ "Confidence" SG_ 2047 GTW_softRange 0;
BA_ "Confidence" SG_ 2047 GTW_refrigerantType 0;
BA_ "Confidence" SG_ 2047 GTW_wheelType 0;
BA_ "Confidence" SG_ 2047 GTW_ptcControlMode 0;
BA_ "Confidence" SG_ 2047 GTW_brakeActuationType 0;
BA_ "Confidence" SG_ 2047 GTW_secondRowSeatType 0;
BA_ "Confidence" SG_ 2047 GTW_secondRowSeatMotorType 0;
BA_ "Confidence" SG_ 2047 GTW_birthday 0;
BA_ "Confidence" SG_ 2047 GTW_eCallEnabled 0;
BA_ "Confidence" SG_ 2047 GTW_parkAssistECUType 0;
BA_ "Confidence" SG_ 2047 GTW_passengerAirbagType 0;
BA_ "Confidence" SG_ 2047 GTW_forwardRadarHw 0;
BA_ "Confidence" SG_ 2047 GTW_frontSeatType 0;
BA_ "Confidence" SG_ 2047 GTW_secondRowDisplayType 0;
BA_ "Confidence" SG_ 2047 GTW_wirelessPhoneChargerType 0;
BA_ "Confidence" SG_ 2047 GTW_ethernetTunerType 0;
BA_ "Confidence" SG_ 2047 GTW_interiorTrimType 0;
BA_ "Confidence" SG_ 2047 GTW_gloveboxUSBType 0;
BA_ "Confidence" SG_ 2047 GTW_coolantPumpType 0;
BA_ "Confidence" SG_ 2047 GTW_epblHwType 0;
BA_ "Confidence" SG_ 2047 GTW_epbrHwType 0;
BA_ "Confidence" SG_ 2047 GTW_blowerMotorType 0;
BA_ "Confidence" SG_ 2047 GTW_rearLeftBLEEndpointParameter 0;
BA_ "SystemSignalLongSymbol" SG_ 2047 GTW_rearLeftBLEEndpointParameter "GTW_rearLeftBLEEndpointParameterType";
BA_ "Confidence" SG_ 2047 GTW_frontUsbHubType 0;
BA_ "Confidence" SG_ 2047 GTW_superManifoldType 0;
BA_ "Confidence" SG_ 2047 GTW_rcmLocation 0;
BA_ "Confidence" SG_ 2047 GTW_interiorCamFanType 1;
BA_ "Confidence" SG_ 2047 GTW_interiorCamBeautyCoverType 0;
BA_ "Confidence" SG_ 2047 GTW_sirenType 0;
BA_ "Confidence" SG_ 2047 GTW_hornType 0;
BA_ "Confidence" SG_ 2047 GTW_badgingVersion 1;
BA_ "Confidence" SG_ 2047 GTW_steeringColumnMotorType 0;
BA_ "Confidence" SG_ 2047 GTW_refrigACLineType 0;
BA_ "Confidence" SG_ 2047 GTW_refrigFilterType 0;
BA_ "Confidence" SG_ 2047 GTW_diBurnInType 0;
BA_ "Confidence" SG_ 2047 GTW_specialBadgingType 0;
BA_ "Confidence" SG_ 2047 GTW_chassisSubType 1;
BA_ "Confidence" SG_ 2047 GTW_frontSeatVentilationType 1;
BA_ "Confidence" SG_ 2047 GTW_towPackage 0;
BA_ "Confidence" SG_ 2047 GTW_refrigLccType 0;
BA_ "Confidence" SG_ 2047 GTW_caliperColorType 0;
BA_ "Confidence" SG_ 2047 GTW_wiperMotorType 0;
BA_ "Confidence" SG_ 2047 GTW_frontOverheadConsoleType 0;
BA_ "Confidence" SG_ 2047 GTW_shifterType 0;
BA_ "Confidence" SG_ 2047 GTW_compressorType 0;
BA_ "Confidence" SG_ 2047 GTW_twelveVBatteryType 0;
BA_ "Confidence" SG_ 2047 GTW_efuseSWConfig 0;
BA_ "Confidence" SG_ 2047 GTW_tollCollectionModuleType 0;
BA_ "Confidence" SG_ 2047 GTW_bleEndpointUpdateMethod 0;
BA_ "Confidence" SG_ 2047 GTW_steeringWheelControllerType 0;
BA_ "Confidence" SG_ 2047 GTW_frontSeatVentilationEnabled 0;
BA_ "Confidence" SG_ 2047 GTW_gloveboxActuatorType 0;
BA_ "Confidence" SG_ 2047 GTW_epasType 0;
BA_ "Confidence" SG_ 2047 GTW_homologationRegionOverride 0;
BA_ "Confidence" SG_ 2047 GTW_windowCommandsPermissionType 0;
BA_ "Confidence" SG_ 2047 GTW_headlightStepperStallDetectM 0;
BA_ "SystemSignalLongSymbol" SG_ 2047 GTW_headlightStepperStallDetectM "GTW_headlightStepperStallDetectMode";
BA_ "Confidence" SG_ 2047 GTW_rgbInteriorLightingEnabled 0;
BA_ "Confidence" SG_ 2047 GTW_windshieldWiperHeaterType 0;
BA_ "Confidence" SG_ 2047 GTW_driveInterfaceType 0;
BA_ "Confidence" SG_ 2047 GTW_efficiencyPackage 0;
BA_ "Confidence" SG_ 2047 GTW_visorLightType 0;
BA_ "Confidence" SG_ 2047 GTW_gnssAntennaType 0;
BA_ "Confidence" SG_ 2047 GTW_frontSeatHeatersEnabled 0;
BA_ "Confidence" SG_ 2047 GTW_windshieldWiperHeaterEnabled 0;
BA_ "Confidence" SG_ 2047 GTW_tcuType 1;
BA_ "Confidence" SG_ 2047 GTW_fasciaType 0;
BA_ "Confidence" SG_ 2047 GTW_powerSteeringColumn 0;
BA_ "Confidence" SG_ 2047 GTW_frontSeatHeaterType 0;
BA_ "Confidence" SG_ 2047 GTW_softPerformanceLimit 0;
BA_ "Confidence" SG_ 2047 GTW_alcoholInterlockType 1;
BA_ "Confidence" SG_ 2047 GTW_immersiveAudio 0;
BA_ "Confidence" SG_ 2047 GTW_passengerOccupancySensorType 0;
BA_ "Confidence" SG_ 2047 GTW_packPerformanceDeviation 0;
BA_ "Confidence" SG_ 2047 GTW_frontFogLamps 0;
BA_ "Confidence" SG_ 2047 GTW_driverOccupancySensorType 0;
BA_ "Confidence" SG_ 2047 GTW_audioType 0;
BA_ "Confidence" SG_ 2047 GTW_occupancyClassificationFeatu 0;
BA_ "SystemSignalLongSymbol" SG_ 2047 GTW_occupancyClassificationFeatu "GTW_occupancyClassificationFeatureType";
BA_ "Confidence" SG_ 2047 GTW_domeLightType 0;
BA_ "Confidence" SG_ 2047 GTW_tpmsType 0;
BA_ "Confidence" SG_ 2047 GTW_authenticationEndpointLayout 0;
BA_ "Confidence" SG_ 2047 GTW_socSleepOverride 0;
BA_ "Confidence" SG_ 2047 GTW_r79BehaviorOverride 0;
BA_ "Confidence" SG_ 2047 GTW_steeringHeaterType 0;
BA_ "Confidence" SG_ 2047 GTW_sohRegulatoryStatus 0;
BA_ "Confidence" SG_ 2047 GTW_m3yBusArchitecture 0;
BA_ "Confidence" SG_ 2047 GTW_blindSpotIndicatorLightType 1;
BA_ "Confidence" SG_ 2047 GTW_hvacCaseDoorType 0;
BA_ "Confidence" SG_ 2047 GTW_occupancyDetectionSourceRequ 0;
BA_ "SystemSignalLongSymbol" SG_ 2047 GTW_occupancyDetectionSourceRequ "GTW_occupancyDetectionSourceRequest";
BA_ "Confidence" SG_ 2047 GTW_rduCableType 0;
BA_ "Confidence" SG_ 2047 GTW_interiorCameraType 0;
BA_ "Confidence" SG_ 2047 GTW_frontFasciaCameraType 0;
BA_ "Confidence" SG_ 1638 GTW_diagRemainingSeconds 0;
BA_ "Confidence" SG_ 1638 GTW_diagSessionActive 0;
BA_ "Confidence" SG_ 1638 GTW_diagLevel 0;
BA_ "Confidence" SG_ 1638 GTW_diagUnlockProcedureActive 0;
BA_ "Confidence" SG_ 1638 GTW_diagOverrideActive 0;
BA_ "Confidence" SG_ 1638 GTW_diagPhysicalLinkEstablished 0;
BA_ "Confidence" SG_ 1080 GTW_ethGotoSleep 0;
BA_ "Confidence" SG_ 1080 GTW_ethWakeUpBus 0;
BA_ "Confidence" SG_ 1080 GTW_vehBusAsleep 0;
BA_ "Confidence" SG_ 1080 GTW_ethHeartBeatCounter 0;
BA_ "Confidence" SG_ 1080 GTW_ethWakeUpReason 1;
BA_ "Confidence" SG_ 1656 GTW_gearControlChecksum 0;
BA_ "Confidence" SG_ 1656 GTW_gearControlCounter 0;
BA_ "Confidence" SG_ 1656 GTW_gearShiftRequest 0;
BA_ "GenSigSNA" SG_ 1656 GTW_gearShiftRequest "0";
BA_ "Confidence" SG_ 1656 GTW_osdActive 0;
BA_ "Confidence" SG_ 1656 GTW_primaryGearControlStatus 0;
BA_ "Confidence" SG_ 1656 GTW_gearStripEnable 0;
BA_ "Confidence" SG_ 1656 GTW_showNeutralButton 0;
BA_ "Confidence" SG_ 1656 GTW_showAutoParkButton 0;
BA_ "Confidence" SG_ 1656 GTW_autoParkRequest 0;
BA_ "Confidence" SG_ 1656 GTW_smartShiftStatus 0;
BA_ "GenSigSNA" SG_ 1656 GTW_smartShiftStatus "0";
BA_ "Confidence" SG_ 1656 GTW_processingRDgestures 0;
BA_ "Confidence" SG_ 1656 GTW_processingTapPgestures 0;
BA_ "Confidence" SG_ 1656 GTW_gearStripChangeReason 0;
BA_ "GenSigSNA" SG_ 1656 GTW_gearStripChangeReason "0";
BA_ "Confidence" SG_ 1656 GTW_touchActive 0;
BA_ "Confidence" SG_ 1656 GTW_steamOff 0;
BA_ "Confidence" SG_ 1656 GTW_screenPCBTemperature 1;
BA_ "GenSigSNA" SG_ 1656 GTW_screenPCBTemperature "2047";
BA_ "Confidence" SG_ 2033 GTW_hrlIndex 1;
BA_ "Confidence" SG_ 2033 GTW_hrlState 0;
BA_ "Confidence" SG_ 2033 GTW_hrlTriggerDuration 1;
BA_ "Confidence" SG_ 2033 GTW_hrlTriggerType 0;
BA_ "Confidence" SG_ 2033 GTW_hrlTriggerId 1;
BA_ "Confidence" SG_ 60 GTW_infoIndex 1;
BA_ "Confidence" SG_ 60 GTW_buildType 0;
BA_ "Confidence" SG_ 60 GTW_hardwareId 0;
BA_ "Confidence" SG_ 60 GTW_platformType 0;
BA_ "Confidence" SG_ 60 GTW_appCrc 0;
BA_ "Confidence" SG_ 60 GTW_applicationGitHash 0;
BA_ "Confidence" SG_ 60 GTW_bootGitHash 0;
BA_ "Confidence" SG_ 1370 GTW_mismatchFaultIndex 1;
BA_ "Confidence" SG_ 1370 GTW_mismatchFaultChecksum 0;
BA_ "Confidence" SG_ 1370 GTW_mismatchFaultCounter 0;
BA_ "Confidence" SG_ 1370 GTW_GTWmismatchFault 0;
BA_ "Confidence" SG_ 1370 GTW_BMSmismatchFault 0;
BA_ "Confidence" SG_ 1370 GTW_APSmismatchFault 0;
BA_ "Confidence" SG_ 1370 GTW_BLEEPCENTERmismatchFault 0;
BA_ "Confidence" SG_ 1370 GTW_BLEEPLEFTmismatchFault 0;
BA_ "Confidence" SG_ 1370 GTW_BLEEPREARmismatchFault 0;
BA_ "Confidence" SG_ 1370 GTW_BLEEPRIGHTmismatchFault 0;
BA_ "Confidence" SG_ 1370 GTW_CBCmismatchFault 0;
BA_ "Confidence" SG_ 1370 GTW_CMPmismatchFault 0;
BA_ "Confidence" SG_ 1370 GTW_CPmismatchFault 0;
BA_ "Confidence" SG_ 1370 GTW_DIFmismatchFault 0;
BA_ "Confidence" SG_ 1370 GTW_DIRmismatchFault 0;
BA_ "Confidence" SG_ 1370 GTW_EPAS3PmismatchFault 0;
BA_ "Confidence" SG_ 1370 GTW_EPAS3SmismatchFault 0;
BA_ "Confidence" SG_ 1370 GTW_EPBLmismatchFault 0;
BA_ "Confidence" SG_ 1370 GTW_EPBRmismatchFault 0;
BA_ "Confidence" SG_ 1370 GTW_ESPCALmismatchFault 0;
BA_ "Confidence" SG_ 1370 GTW_ESPmismatchFault 0;
BA_ "Confidence" SG_ 1370 GTW_HCM3LmismatchFault 0;
BA_ "Confidence" SG_ 1370 GTW_HCM3RmismatchFault 0;
BA_ "Confidence" SG_ 1370 GTW_HCMLmismatchFault 0;
BA_ "Confidence" SG_ 1370 GTW_HCMRmismatchFault 0;
BA_ "Confidence" SG_ 1370 GTW_HVPmismatchFault 0;
BA_ "Confidence" SG_ 1370 GTW_IBSTCALmismatchFault 0;
BA_ "Confidence" SG_ 1370 GTW_IBSTmismatchFault 0;
BA_ "Confidence" SG_ 1370 GTW_LVBMSmismatchFault 0;
BA_ "Confidence" SG_ 1370 GTW_OCS1PmismatchFault 0;
BA_ "Confidence" SG_ 1370 GTW_OPCFmismatchFault 0;
BA_ "Confidence" SG_ 1370 GTW_OPCRmismatchFault 0;
BA_ "Confidence" SG_ 1370 GTW_PARKmismatchFault 0;
BA_ "Confidence" SG_ 1370 GTW_PCSCPU2mismatchFault 0;
BA_ "Confidence" SG_ 1370 GTW_PCSmismatchFault 0;
BA_ "Confidence" SG_ 1370 GTW_PMFmismatchFault 0;
BA_ "Confidence" SG_ 1370 GTW_PMRmismatchFault 0;
BA_ "Confidence" SG_ 1370 GTW_PTCmismatchFault 0;
BA_ "Confidence" SG_ 1370 GTW_RCMCALmismatchFault 0;
BA_ "Confidence" SG_ 1370 GTW_RCMmismatchFault 0;
BA_ "Confidence" SG_ 1370 GTW_SCCMmismatchFault 0;
BA_ "Confidence" SG_ 1370 GTW_SDCRmismatchFault 0;
BA_ "Confidence" SG_ 1370 GTW_SWCmismatchFault 0;
BA_ "Confidence" SG_ 1370 GTW_THSmismatchFault 0;
BA_ "Confidence" SG_ 1370 GTW_VCFRONTmismatchFault 0;
BA_ "Confidence" SG_ 1370 GTW_VCLEFTmismatchFault 0;
BA_ "Confidence" SG_ 1370 GTW_VCRIGHTmismatchFault 0;
BA_ "Confidence" SG_ 1370 GTW_VCSECmismatchFault 0;
BA_ "Confidence" SG_ 1370 GTW_PMmismatchFault 0;
BA_ "Confidence" SG_ 840 GTW_vehicleVersionMatchStatus 0;
BA_ "Confidence" SG_ 840 GTW_hwtype 0;
BA_ "GenSigSNA" SG_ 840 GTW_hwtype "0";
BA_ "Confidence" SG_ 840 GTW_jcanProductName 0;
BA_ "GenSigSNA" SG_ 840 GTW_jcanProductName "0";
BA_ "Confidence" SG_ 840 GTW_uptimeSeconds 1;
BA_ "Confidence" SG_ 840 GTW_boardRevision 0;
BA_ "Confidence" SG_ 840 GTW_sentryModeState 1;
BA_ "GenSigSNA" SG_ 840 GTW_sentryModeState "6";
BA_ "Confidence" SG_ 840 GTW_socSleepType 0;
BA_ "GenSigSNA" SG_ 840 GTW_socSleepType "0";
BA_ "Confidence" SG_ 840 GTW_resetType 1;
BA_ "GenSigSNA" SG_ 840 GTW_resetType "0";
BA_ "Confidence" SG_ 1005 GTW_ecuUpdateStarted 0;
BA_ "Confidence" SG_ 1005 GTW_updateStarted 1;
BA_ "Confidence" SG_ 1112 GTW_nmGoingToSleep 0;
BA_ "Confidence" SG_ 1112 GTW_nmWakeUpBus 0;
BA_ "Confidence" SG_ 1112 GTW_chBusAsleep 0;
BA_ "Confidence" SG_ 1112 GTW_ethBusAsleep 0;
BA_ "Confidence" SG_ 1112 GTW_nmKeepAwakeReason 0;
BA_ "GenSigSNA" SG_ 1112 GTW_nmKeepAwakeReason "0";
BA_ "Confidence" SG_ 1112 GTW_nmWakeUpReason 1;
BA_ "Confidence" SG_ 1112 GTW_ethKeepAwakeReason 1;
BA_ "GenSigSNA" SG_ 1112 GTW_ethKeepAwakeReason "0";
BA_ "Confidence" SG_ 1112 GTW_nmDebugWakeUp 1;
BA_ "Confidence" SG_ 1112 GTW_OTAKeepAwake 1;
BA_ "Confidence" SG_ 1112 GTW_smsPokeReceived 1;
BA_ "Confidence" SG_ 1112 GTW_bdyBusAsleep 1;
BA_ "Confidence" SG_ 760 ICR_loggingCorrelationDBG 1;
BA_ "Confidence" SG_ 760 ICR_loggingTriggerRangeDBG 1;
BA_ "Confidence" SG_ 760 ICR_loggingTriggerXPosDBG 1;
BA_ "Confidence" SG_ 760 ICR_loggingTriggerYPosDBG 1;
BA_ "Confidence" SG_ 1470 IDB_alertID 1;
BA_ "Confidence" SG_ 1470 IDB_alertState 1;
BA_ "Confidence" SG_ 1470 IDB_a014_wheelSpeedSensorFreq 1;
BA_ "Confidence" SG_ 1470 IDB_a014_wheelSpeedSensorPhase 1;
BA_ "Confidence" SG_ 1470 IDB_a014_wheelSpeedSensorMisinst 1;
BA_ "SystemSignalLongSymbol" SG_ 1470 IDB_a014_wheelSpeedSensorMisinst "IDB_a014_wheelSpeedSensorMisinstallation";
BA_ "Confidence" SG_ 1470 IDB_a014_wheelSpeedSensorWrongEx 1;
BA_ "SystemSignalLongSymbol" SG_ 1470 IDB_a014_wheelSpeedSensorWrongEx "IDB_a014_wheelSpeedSensorWrongExciter";
BA_ "Confidence" SG_ 1470 IDB_a014_wheelSpeedSensorSpeedJu 1;
BA_ "SystemSignalLongSymbol" SG_ 1470 IDB_a014_wheelSpeedSensorSpeedJu "IDB_a014_wheelSpeedSensorSpeedJumpMinus";
BA_ "Confidence" SG_ 1470 IDB_a014_wheelSpeedSensorSp_0001 1;
BA_ "SystemSignalLongSymbol" SG_ 1470 IDB_a014_wheelSpeedSensorSp_0001 "IDB_a014_wheelSpeedSensorSpeedJumpPlus";
BA_ "Confidence" SG_ 1470 IDB_a014_wheelSpeedSensorAirGap 1;
BA_ "Confidence" SG_ 1470 IDB_a014_wheelSpeedSensorBIST 1;
BA_ "Confidence" SG_ 1470 IDB_a014_wheelSpeedSensorLeakage 1;
BA_ "SystemSignalLongSymbol" SG_ 1470 IDB_a014_wheelSpeedSensorLeakage "IDB_a014_wheelSpeedSensorLeakageCur";
BA_ "Confidence" SG_ 1470 IDB_a014_wheelSpeedSensorOverTem 1;
BA_ "SystemSignalLongSymbol" SG_ 1470 IDB_a014_wheelSpeedSensorOverTem "IDB_a014_wheelSpeedSensorOverTemp";
BA_ "Confidence" SG_ 1470 IDB_a014_wheelSpeedSensorSh_0001 1;
BA_ "SystemSignalLongSymbol" SG_ 1470 IDB_a014_wheelSpeedSensorSh_0001 "IDB_a014_wheelSpeedSensorShortToGnd";
BA_ "Confidence" SG_ 1470 IDB_a014_wheelSpeedSensorShortTo 1;
BA_ "SystemSignalLongSymbol" SG_ 1470 IDB_a014_wheelSpeedSensorShortTo "IDB_a014_wheelSpeedSensorShortToBat";
BA_ "Confidence" SG_ 1470 IDB_a014_wheelSpeedSensorOpen 1;
BA_ "Confidence" SG_ 1470 IDB_a015_wheelSpeedSensorFreq 1;
BA_ "Confidence" SG_ 1470 IDB_a015_wheelSpeedSensorPhase 1;
BA_ "Confidence" SG_ 1470 IDB_a015_wheelSpeedSensorMisinst 1;
BA_ "SystemSignalLongSymbol" SG_ 1470 IDB_a015_wheelSpeedSensorMisinst "IDB_a015_wheelSpeedSensorMisinstallation";
BA_ "Confidence" SG_ 1470 IDB_a015_wheelSpeedSensorWrongEx 1;
BA_ "SystemSignalLongSymbol" SG_ 1470 IDB_a015_wheelSpeedSensorWrongEx "IDB_a015_wheelSpeedSensorWrongExciter";
BA_ "Confidence" SG_ 1470 IDB_a015_wheelSpeedSensorSpeedJu 1;
BA_ "SystemSignalLongSymbol" SG_ 1470 IDB_a015_wheelSpeedSensorSpeedJu "IDB_a015_wheelSpeedSensorSpeedJumpMinus";
BA_ "Confidence" SG_ 1470 IDB_a015_wheelSpeedSensorSp_0001 1;
BA_ "SystemSignalLongSymbol" SG_ 1470 IDB_a015_wheelSpeedSensorSp_0001 "IDB_a015_wheelSpeedSensorSpeedJumpPlus";
BA_ "Confidence" SG_ 1470 IDB_a015_wheelSpeedSensorAirGap 1;
BA_ "Confidence" SG_ 1470 IDB_a015_wheelSpeedSensorBIST 1;
BA_ "Confidence" SG_ 1470 IDB_a015_wheelSpeedSensorLeakage 1;
BA_ "SystemSignalLongSymbol" SG_ 1470 IDB_a015_wheelSpeedSensorLeakage "IDB_a015_wheelSpeedSensorLeakageCur";
BA_ "Confidence" SG_ 1470 IDB_a015_wheelSpeedSensorOverTem 1;
BA_ "SystemSignalLongSymbol" SG_ 1470 IDB_a015_wheelSpeedSensorOverTem "IDB_a015_wheelSpeedSensorOverTemp";
BA_ "Confidence" SG_ 1470 IDB_a015_wheelSpeedSensorSh_0001 1;
BA_ "SystemSignalLongSymbol" SG_ 1470 IDB_a015_wheelSpeedSensorSh_0001 "IDB_a015_wheelSpeedSensorShortToGnd";
BA_ "Confidence" SG_ 1470 IDB_a015_wheelSpeedSensorShortTo 1;
BA_ "SystemSignalLongSymbol" SG_ 1470 IDB_a015_wheelSpeedSensorShortTo "IDB_a015_wheelSpeedSensorShortToBat";
BA_ "Confidence" SG_ 1470 IDB_a015_wheelSpeedSensorOpen 1;
BA_ "Confidence" SG_ 1470 IDB_a016_wheelSpeedSensorFreq 1;
BA_ "Confidence" SG_ 1470 IDB_a016_wheelSpeedSensorPhase 1;
BA_ "Confidence" SG_ 1470 IDB_a016_wheelSpeedSensorMisinst 1;
BA_ "SystemSignalLongSymbol" SG_ 1470 IDB_a016_wheelSpeedSensorMisinst "IDB_a016_wheelSpeedSensorMisinstallation";
BA_ "Confidence" SG_ 1470 IDB_a016_wheelSpeedSensorWrongEx 1;
BA_ "SystemSignalLongSymbol" SG_ 1470 IDB_a016_wheelSpeedSensorWrongEx "IDB_a016_wheelSpeedSensorWrongExciter";
BA_ "Confidence" SG_ 1470 IDB_a016_wheelSpeedSensorSpeedJu 1;
BA_ "SystemSignalLongSymbol" SG_ 1470 IDB_a016_wheelSpeedSensorSpeedJu "IDB_a016_wheelSpeedSensorSpeedJumpMinus";
BA_ "Confidence" SG_ 1470 IDB_a016_wheelSpeedSensorSp_0001 1;
BA_ "SystemSignalLongSymbol" SG_ 1470 IDB_a016_wheelSpeedSensorSp_0001 "IDB_a016_wheelSpeedSensorSpeedJumpPlus";
BA_ "Confidence" SG_ 1470 IDB_a016_wheelSpeedSensorAirGap 1;
BA_ "Confidence" SG_ 1470 IDB_a016_wheelSpeedSensorBIST 1;
BA_ "Confidence" SG_ 1470 IDB_a016_wheelSpeedSensorLeakage 1;
BA_ "SystemSignalLongSymbol" SG_ 1470 IDB_a016_wheelSpeedSensorLeakage "IDB_a016_wheelSpeedSensorLeakageCur";
BA_ "Confidence" SG_ 1470 IDB_a016_wheelSpeedSensorOverTem 1;
BA_ "SystemSignalLongSymbol" SG_ 1470 IDB_a016_wheelSpeedSensorOverTem "IDB_a016_wheelSpeedSensorOverTemp";
BA_ "Confidence" SG_ 1470 IDB_a016_wheelSpeedSensorSh_0001 1;
BA_ "SystemSignalLongSymbol" SG_ 1470 IDB_a016_wheelSpeedSensorSh_0001 "IDB_a016_wheelSpeedSensorShortToGnd";
BA_ "Confidence" SG_ 1470 IDB_a016_wheelSpeedSensorShortTo 1;
BA_ "SystemSignalLongSymbol" SG_ 1470 IDB_a016_wheelSpeedSensorShortTo "IDB_a016_wheelSpeedSensorShortToBat";
BA_ "Confidence" SG_ 1470 IDB_a016_wheelSpeedSensorOpen 1;
BA_ "Confidence" SG_ 1470 IDB_a017_wheelSpeedSensorFreq 1;
BA_ "Confidence" SG_ 1470 IDB_a017_wheelSpeedSensorPhase 1;
BA_ "Confidence" SG_ 1470 IDB_a017_wheelSpeedSensorMisinst 1;
BA_ "SystemSignalLongSymbol" SG_ 1470 IDB_a017_wheelSpeedSensorMisinst "IDB_a017_wheelSpeedSensorMisinstallation";
BA_ "Confidence" SG_ 1470 IDB_a017_wheelSpeedSensorWrongEx 1;
BA_ "SystemSignalLongSymbol" SG_ 1470 IDB_a017_wheelSpeedSensorWrongEx "IDB_a017_wheelSpeedSensorWrongExciter";
BA_ "Confidence" SG_ 1470 IDB_a017_wheelSpeedSensorSpeedJu 1;
BA_ "SystemSignalLongSymbol" SG_ 1470 IDB_a017_wheelSpeedSensorSpeedJu "IDB_a017_wheelSpeedSensorSpeedJumpMinus";
BA_ "Confidence" SG_ 1470 IDB_a017_wheelSpeedSensorSp_0001 1;
BA_ "SystemSignalLongSymbol" SG_ 1470 IDB_a017_wheelSpeedSensorSp_0001 "IDB_a017_wheelSpeedSensorSpeedJumpPlus";
BA_ "Confidence" SG_ 1470 IDB_a017_wheelSpeedSensorAirGap 1;
BA_ "Confidence" SG_ 1470 IDB_a017_wheelSpeedSensorBIST 1;
BA_ "Confidence" SG_ 1470 IDB_a017_wheelSpeedSensorLeakage 1;
BA_ "SystemSignalLongSymbol" SG_ 1470 IDB_a017_wheelSpeedSensorLeakage "IDB_a017_wheelSpeedSensorLeakageCur";
BA_ "Confidence" SG_ 1470 IDB_a017_wheelSpeedSensorOverTem 1;
BA_ "SystemSignalLongSymbol" SG_ 1470 IDB_a017_wheelSpeedSensorOverTem "IDB_a017_wheelSpeedSensorOverTemp";
BA_ "Confidence" SG_ 1470 IDB_a017_wheelSpeedSensorSh_0001 1;
BA_ "SystemSignalLongSymbol" SG_ 1470 IDB_a017_wheelSpeedSensorSh_0001 "IDB_a017_wheelSpeedSensorShortToGnd";
BA_ "Confidence" SG_ 1470 IDB_a017_wheelSpeedSensorShortTo 1;
BA_ "SystemSignalLongSymbol" SG_ 1470 IDB_a017_wheelSpeedSensorShortTo "IDB_a017_wheelSpeedSensorShortToBat";
BA_ "Confidence" SG_ 1470 IDB_a017_wheelSpeedSensorOpen 1;
BA_ "Confidence" SG_ 1470 IDB_a020_canSignalValidity 1;
BA_ "Confidence" SG_ 1470 IDB_a020_signalValueCrosscheck 1;
BA_ "Confidence" SG_ 1470 IDB_a030_primaryExternalCircuitL 1;
BA_ "SystemSignalLongSymbol" SG_ 1470 IDB_a030_primaryExternalCircuitL "IDB_a030_primaryExternalCircuitLeakage";
BA_ "Confidence" SG_ 1470 IDB_a030_secondaryExternalCircui 1;
BA_ "SystemSignalLongSymbol" SG_ 1470 IDB_a030_secondaryExternalCircui "IDB_a030_secondaryExternalCircuitLeakage";
BA_ "Confidence" SG_ 1470 IDB_a030_primaryChamberInternalL 1;
BA_ "SystemSignalLongSymbol" SG_ 1470 IDB_a030_primaryChamberInternalL "IDB_a030_primaryChamberInternalLeakage";
BA_ "Confidence" SG_ 1470 IDB_a030_syncModeInternalLeakage 1;
BA_ "Confidence" SG_ 1470 IDB_a030_secondaryChamberInterna 1;
BA_ "SystemSignalLongSymbol" SG_ 1470 IDB_a030_secondaryChamberInterna "IDB_a030_secondaryChamberInternalLeakage";
BA_ "Confidence" SG_ 1470 IDB_a030_masterCylinderInternalL 1;
BA_ "SystemSignalLongSymbol" SG_ 1470 IDB_a030_masterCylinderInternalL "IDB_a030_masterCylinderInternalLeakage";
BA_ "Confidence" SG_ 1470 IDB_a060_validityOnChassisBus 1;
BA_ "Confidence" SG_ 1470 IDB_a060_validityOnPartyBus 1;
BA_ "Confidence" SG_ 1470 IDB_a061_validityOnChassisBus 1;
BA_ "Confidence" SG_ 1470 IDB_a061_validityOnPartyBus 1;
BA_ "Confidence" SG_ 1470 IDB_a062_validityOnChassisBus 1;
BA_ "Confidence" SG_ 1470 IDB_a062_validityOnPartyBus 1;
BA_ "Confidence" SG_ 1470 IDB_a063_validityOnChassisBus 1;
BA_ "Confidence" SG_ 1470 IDB_a063_validityOnPartyBus 1;
BA_ "Confidence" SG_ 1470 IDB_a064_validityOnChassisBus 1;
BA_ "Confidence" SG_ 1470 IDB_a064_validityOnPartyBus 1;
BA_ "Confidence" SG_ 1470 IDB_a065_validityOnChassisBus 1;
BA_ "Confidence" SG_ 1470 IDB_a065_validityOnPartyBus 1;
BA_ "Confidence" SG_ 1470 IDB_a106_qualifierValidity 1;
BA_ "Confidence" SG_ 1470 IDB_a106_signalNotAvailable 1;
BA_ "Confidence" SG_ 1470 IDB_a107_qualifierValidity 1;
BA_ "Confidence" SG_ 1470 IDB_a107_signalNotAvailable 1;
BA_ "Confidence" SG_ 1470 IDB_a112_qualifierValidity 1;
BA_ "Confidence" SG_ 1470 IDB_a112_signalNotAvailable 1;
BA_ "Confidence" SG_ 1470 IDB_a113_qualifierValidity 1;
BA_ "Confidence" SG_ 1470 IDB_a113_signalNotAvailable 1;
BA_ "Confidence" SG_ 1470 IDB_a114_qualifierValidity 1;
BA_ "Confidence" SG_ 1470 IDB_a114_signalNotAvailable 1;
BA_ "Confidence" SG_ 1470 IDB_a126_PMebrCmdStateValidity 1;
BA_ "Confidence" SG_ 1470 IDB_a126_PMstate2Validity 1;
BA_ "Confidence" SG_ 1470 IDB_a126_PMstate2Missing 1;
BA_ "Confidence" SG_ 1470 IDB_a126_DIchassisControlValidit 1;
BA_ "SystemSignalLongSymbol" SG_ 1470 IDB_a126_DIchassisControlValidit "IDB_a126_DIchassisControlValidity";
BA_ "Confidence" SG_ 1470 IDB_a126_DIchassisControlMissing 1;
BA_ "Confidence" SG_ 1470 IDB_a126_DIrequestActiveValidity 1;
BA_ "Confidence" SG_ 1470 IDB_a129_validityOnChassisBus 1;
BA_ "Confidence" SG_ 1470 IDB_a129_validityOnPartyBus 1;
BA_ "Confidence" SG_ 1470 IDB_a130_PMbrakePedalCmdQFValidi 1;
BA_ "SystemSignalLongSymbol" SG_ 1470 IDB_a130_PMbrakePedalCmdQFValidi "IDB_a130_PMbrakePedalCmdQFValidity";
BA_ "Confidence" SG_ 1470 IDB_a130_PMstate2Validity 1;
BA_ "Confidence" SG_ 1470 IDB_a130_PMstate2Missing 1;
BA_ "Confidence" SG_ 1470 IDB_a130_DIbrakeCommandValidity 1;
BA_ "Confidence" SG_ 1470 IDB_a130_DIbrakeCommandMissing 1;
BA_ "Confidence" SG_ 1470 IDB_a130_DIbrakeTorqueCommandFul 1;
BA_ "SystemSignalLongSymbol" SG_ 1470 IDB_a130_DIbrakeTorqueCommandFul "IDB_a130_DIbrakeTorqueCommandFullSNA";
BA_ "Confidence" SG_ 1470 IDB_a130_DIbrakeTorqueComma_0001 1;
BA_ "SystemSignalLongSymbol" SG_ 1470 IDB_a130_DIbrakeTorqueComma_0001 "IDB_a130_DIbrakeTorqueCommandFullTooLow";
BA_ "Confidence" SG_ 1470 IDB_a132_validityOnChassisBus 1;
BA_ "Confidence" SG_ 1470 IDB_a132_validityOnPartyBus 1;
BA_ "Confidence" SG_ 983 IDB_matrixIndex 1;
BA_ "SystemSignalLongSymbol" SG_ 983 IDB_a070_DIchassisControlChecksu "IDB_a070_DIchassisControlChecksum";
BA_ "SystemSignalLongSymbol" SG_ 983 IDB_a119_VCLEFTepbmStatusChecksu "IDB_a119_VCLEFTepbmStatusChecksum";
BA_ "SystemSignalLongSymbol" SG_ 983 IDB_a129_RCUinputRodStrokeInvali "IDB_a129_RCUinputRodStrokeInvalid";
BA_ "SystemSignalLongSymbol" SG_ 983 IDB_a130_DIfullTorqueRequestInva "IDB_a130_DIfullTorqueRequestInvalid";
BA_ "SystemSignalLongSymbol" SG_ 983 IDB_a132_RCUinputRodStrokeQFInva "IDB_a132_RCUinputRodStrokeQFInvalid";
BA_ "SystemSignalLongSymbol" SG_ 983 IDB_a138_DIbrakeTorqueCommandAnd "IDB_a138_DIbrakeTorqueCommandAndFlagMismatch";
BA_ "SystemSignalLongSymbol" SG_ 983 IDB_a139_DIbrakeTorqueCommandFul "IDB_a139_DIbrakeTorqueCommandFullSNA";
BA_ "SystemSignalLongSymbol" SG_ 983 IDB_a140_PMbrakePedalCmdQFInvali "IDB_a140_PMbrakePedalCmdQFInvalid";
BA_ "SystemSignalLongSymbol" SG_ 983 IDB_a141_DIbrakeTorqueCommandFul "IDB_a141_DIbrakeTorqueCommandFullTooLow";
BA_ "SystemSignalLongSymbol" SG_ 983 IDB_a144_hydraulicPushthroughAct "IDB_a144_hydraulicPushthroughActive";
BA_ "Confidence" SG_ 828 IDB_infoIndex 1;
BA_ "Confidence" SG_ 828 IDB_infoPcbaID 0;
BA_ "Confidence" SG_ 828 IDB_infoAssemblyID 0;
BA_ "Confidence" SG_ 828 IDB_infoUsageID 0;
BA_ "Confidence" SG_ 828 IDB_infoSubUsageID 0;
BA_ "Confidence" SG_ 1429 OCS1P_alertID 1;
BA_ "Confidence" SG_ 1429 OCS1P_alertState 1;
BA_ "Confidence" SG_ 767 OCS1P_matrixIndex 1;
BA_ "SystemSignalLongSymbol" SG_ 767 OCS1P_w148_classificationMismatc "OCS1P_w148_classificationMismatch";
BA_ "Confidence" SG_ 766 OCS1P_infoIndex 1;
BA_ "Confidence" SG_ 766 OCS1P_infoBuildType 0;
BA_ "Confidence" SG_ 766 OCS1P_infoBuildConfigID 0;
BA_ "Confidence" SG_ 766 OCS1P_infoHardwareID 0;
BA_ "Confidence" SG_ 766 OCS1P_infoComponentID 0;
BA_ "Confidence" SG_ 766 OCS1P_infoPcbaID 0;
BA_ "Confidence" SG_ 766 OCS1P_infoAssemblyID 0;
BA_ "Confidence" SG_ 766 OCS1P_infoUsageID 0;
BA_ "Confidence" SG_ 766 OCS1P_infoSubUsageID 0;
BA_ "Confidence" SG_ 766 OCS1P_infoApplicationCRC 0;
BA_ "Confidence" SG_ 766 OCS1P_infoBootSvnRev 0;
BA_ "Confidence" SG_ 766 OCS1P_infoAppGitHashBytes 0;
BA_ "Confidence" SG_ 766 OCS1P_infoBootGitHashBytes 0;
BA_ "Confidence" SG_ 766 OCS1P_infoPlatformType 0;
BA_ "Confidence" SG_ 766 OCS1P_infoBootUdsProtoVersion 0;
BA_ "Confidence" SG_ 766 OCS1P_infoBootloaderCRC 0;
BA_ "Confidence" SG_ 771 OCS1P_occupantClassification 0;
BA_ "GenSigSNA" SG_ 771 OCS1P_occupantClassification "255";
BA_ "Confidence" SG_ 771 OCS1P_occupantClassificationQF 0;
BA_ "Confidence" SG_ 771 OCS1P_occupiedState 0;
BA_ "GenSigSNA" SG_ 771 OCS1P_occupiedState "3";
BA_ "Confidence" SG_ 771 OCS1P_triggerSnapshot 0;
BA_ "Confidence" SG_ 771 OCS1P_occupantClassificationRaw 0;
BA_ "GenSigSNA" SG_ 771 OCS1P_occupantClassificationRaw "7";
BA_ "Confidence" SG_ 771 OCS1P_occupantClassificationSelf 0;
BA_ "GenSigSNA" SG_ 771 OCS1P_occupantClassificationSelf "7";
BA_ "Confidence" SG_ 771 OCS1P_occupantClassificationRawC 0;
BA_ "GenSigSNA" SG_ 771 OCS1P_occupantClassificationRawC "7";
BA_ "SystemSignalLongSymbol" SG_ 771 OCS1P_occupantClassificationRawC "OCS1P_occupantClassificationRawCap";
BA_ "Confidence" SG_ 771 OCS1P_occupantClassificationCap 0;
BA_ "GenSigSNA" SG_ 771 OCS1P_occupantClassificationCap "7";
BA_ "Confidence" SG_ 771 OCS1P_classificationHeld 0;
BA_ "Confidence" SG_ 771 OCS1P_cushionStable 0;
BA_ "Confidence" SG_ 771 OCS1P_classificationExtHold 0;
BA_ "Confidence" SG_ 771 OCS1P_classificationHoldState 0;
BA_ "Confidence" SG_ 771 OCS1P_classificationVariant 0;
BA_ "Confidence" SG_ 771 OCS1P_sandwichDisabled 0;
BA_ "Confidence" SG_ 771 OCS1P_noSandwichType 0;
BA_ "Confidence" SG_ 771 OCS1P_sandwichBoundaryType 0;
BA_ "Confidence" SG_ 771 OCS1P_sbrBoundaryType 0;
BA_ "Confidence" SG_ 771 OCS1P_occupiedStateCap 0;
BA_ "GenSigSNA" SG_ 771 OCS1P_occupiedStateCap "3";
BA_ "Confidence" SG_ 771 OCS1P_seatbackStable 0;
BA_ "Confidence" SG_ 771 OCS1P_sandwichStable 0;
BA_ "Confidence" SG_ 771 OCS1P_cushionStableCap 0;
BA_ "Confidence" SG_ 771 OCS1P_seatbackStableCap 0;
BA_ "Confidence" SG_ 771 OCS1P_classificationHeldCap 0;
BA_ "Confidence" SG_ 771 OCS1P_statusCounter 0;
BA_ "Confidence" SG_ 771 OCS1P_statusChecksum 0;
BA_ "SystemSignalLongSymbol" SG_ 772 PMF_a027_torqueEstimationOutOfBo "PMF_a027_torqueEstimationOutOfBounds";
BA_ "SystemSignalLongSymbol" SG_ 772 PMF_a058_measuredHvilCurrentFroz "PMF_a058_measuredHvilCurrentFrozen";
BA_ "SystemSignalLongSymbol" SG_ 2022 PMF_a086_exceptionUndefinedInstr "PMF_a086_exceptionUndefinedInstruction";
BA_ "SystemSignalLongSymbol" SG_ 902 PMR_a027_torqueEstimationOutOfBo "PMR_a027_torqueEstimationOutOfBounds";
BA_ "SystemSignalLongSymbol" SG_ 902 PMR_a058_measuredHvilCurrentFroz "PMR_a058_measuredHvilCurrentFrozen";
BA_ "SystemSignalLongSymbol" SG_ 928 PMR_a086_exceptionUndefinedInstr "PMR_a086_exceptionUndefinedInstruction";
BA_ "SystemSignalLongSymbol" SG_ 900 PM_a040_latLinkLooseBoltDetected "PM_a040_latLinkLooseBoltDetectedDebug";
BA_ "SystemSignalLongSymbol" SG_ 900 PM_a045_regenBackfillInterventio "PM_a045_regenBackfillIntervention";
VAL_ 2047 GTW_deliveryStatus 1 "DELIVERED" 0 "NOT_DELIVERED" ;
VAL_ 2047 GTW_cabinPTCHeaterType 1 "NONE" 0 "BORGWARNER" ;
VAL_ 2047 GTW_rightHandDrive 1 "RIGHT" 0 "LEFT" ;
VAL_ 2047 GTW_rearLightType 2 "GLOBAL" 1 "EU_CN" 0 "NA" ;
VAL_ 2047 GTW_headlamps 2 "GLOBAL" 1 "PREMIUM" 0 "BASE" ;
VAL_ 2047 GTW_tireType 38 "HANKOOK_SUMMER_18" 37 "GITI_SUMMER_18" 36 "KUMHO_ALL_SEASON_18" 35 "GOODYEAR_ALL_SEASON_18" 34 "CONTI_SUMMER_19" 33 "BRIDGESTONE_ALL_SEASON_20" 32 "HANKOOK_ALL_SEASON_20" 31 "GOODYEAR_SUMMER_19" 30 "KUMHO_ALL_SEASON_19" 29 "HANKOOK_ALL_SEASON_21" 28 "PIRELLI_ALL_SEASON_19" 27 "GOODYEAR_ALL_SEASON_21" 26 "HANKOOK_ALL_SEASON_18" 25 "PIRELLI_ALL_SEASON_22" 24 "CONTI_SUMMER_22" 23 "CONTI_ALL_SEASON_20" 22 "MICHELIN_SUMMER_21" 21 "PIRELLI_SUMMER_20" 20 "PIRELLI_SUMMER_19" 19 "MICHELIN_ALL_SEASON_21" 18 "PIRELLI_SUMMER_21" 17 "GOODYEAR_ALL_SEASON_20" 16 "BRIDGESTONE_SUMMER_18" 7 "GOODYEAR_ALL_TERRAIN_20" 6 "PIRELLI_ALL_SEASON_20" 5 "MICHELIN_SUMMER_20" 4 "CONTI_ALL_SEASON_19" 3 "HANKOOK_SUMMER_19" 2 "MICHELIN_SUMMER_18" 1 "MICHELIN_ALL_SEASON_18" 0 "UNKNOWN" ;
VAL_ 2047 GTW_roofGlassType 3 "UNCOATED" 2 "NONE" 1 "TSA5_NOPET" 0 "TSA3_PET" ;
VAL_ 2047 GTW_dasHw 5 "TESLA_AP4" 4 "TESLA_AP3" 3 "PARKER_PASCAL_2_5" ;
VAL_ 2047 GTW_brakeHWType 21 "HITACHI_P42_V2_MANDO_43MOC_LOW_DRAG" 20 "BREMBO_LARGE_P42_V2_MANDO_43MOC_LOW_DRAG" 18 "BREMBO_LARGE_P42_V2_BREMBO_44MOC_GA" 17 "HITACHI_P42_V2_MANDO_43MOC" 16 "BREMBO_P42LD_V2_MANDO_43MOC" 15 "BREMBO_P42LD_ZF_43MOC" 13 "BREMBO_P42_ZF_43MOC" 9 "BREMBO_P42_V2_MANDO_43MOC" 8 "BREMBO_LARGE_P42_V2_MANDO_43MOC" 7 "BREMBO_LARGE_P42_V2_BREMBO_LARGE_44MOC" 6 "BREMBO_LARGE_P42_V2_BREMBO_44MOC" 3 "BREMBO_LARGE_P42_BREMBO_LARGE_44MOC" 2 "BREMBO_LARGE_P42_MANDO_43MOC" 1 "BREMBO_LARGE_P42_BREMBO_44MOC" 0 "BREMBO_P42_MANDO_43MOC" ;
VAL_ 2047 GTW_restraintsHardwareType 239 "NA_NO_KAB_MYB" 238 "ROW_ECALL_E41_MYB" 237 "EU_ECALL_E41_MYB" 236 "NA_E41_MYB" 233 "NA_MYL" 232 "ECE_ECALL_PEDPRO_MYL" 89 "ROW_ECALL_PEDPRO_MYL" 88 "ROW_PEDPRO_MYB" 87 "ROW_PERF_ECALL_PEDPRO_MYB" 86 "EU_PERF_ECALL_PEDPRO_MYB" 85 "EU_ECALL_PEDPRO_MYB" 84 "ROW_ECALL_PEDPRO_MYB" 83 "ROW_MYB" 82 "ROW_ECALL_MYB" 81 "NA_MYB" ;
VAL_ 2047 GTW_drivetrainType 1 "AWD" 0 "RWD" ;
VAL_ 2047 GTW_radarHeaterType 1 "MODELY_BACKER_THIN_3M" 0 "NONE" ;
VAL_ 2047 GTW_exteriorTrimType 1 "SATIN_BLACK" 0 "STANDARD_CHROME" ;
VAL_ 2047 GTW_frontSeatHeaters 1 "KONGSBERG_LOW_POWER" 0 "NONE" ;
VAL_ 2047 GTW_rearSeatHeaters 1 "KONGSBERG_LOW_POWER" 0 "NONE" ;
VAL_ 2047 GTW_eCallAntennaHW 1 "MAIN_ANT_ONLY" 0 "BACKUP_OR_MAIN_ANT" ;
VAL_ 2047 GTW_homelinkType 1 "HOMELINK_V_OPT_2" 0 "NONE" ;
VAL_ 2047 GTW_vdcType 1 "TESLA_VDC" 0 "BOSCH_VDC" ;
VAL_ 2047 GTW_memoryMirrors 1 "SMR" 0 "NOT_INSTALLED" ;
VAL_ 2047 GTW_powerLiftgateType 2 "HUADE_REV1" 1 "TESLA_REV1" 0 "NOT_INSTALLED" ;
VAL_ 2047 GTW_lumbarECUType 10 "AEW_SINGLE_AXIS_DRIVER_ONLY_RHD" 9 "AEW_SINGLE_AXIS_DRIVER_ONLY_LHD" 8 "ND_DRIVER_ONLY_RHD" 7 "ND_DRIVER_ONLY_LHD" 6 "AEW_DRIVER_ONLY_RHD" 5 "AEW_DRIVER_ONLY_LHD" 4 "AEW" 3 "ALFMEIER_DRIVER_ONLY_RHD" 2 "ALFMEIER_DRIVER_ONLY_LHD" 1 "ALFMEIER" 0 "NONE" ;
VAL_ 2047 GTW_rearSeatHeaterType 3 "LEFT_RIGHT_ONLY_GENTHERM" 2 "NONE" 1 "LEFT_RIGHT_ONLY_KONGSBERG" ;
VAL_ 2047 GTW_auxParkLamps 3 "NONE" 2 "EU" 1 "NA_PREMIUM" 0 "NA_BASE" ;
VAL_ 2047 GTW_interiorCabinRadarType 1 "TESLA" 0 "NONE" ;
VAL_ 2047 GTW_hvacPanelVaneType 1 "CONVERGENT_V1" 0 "PARALLEL_V1" ;
VAL_ 2047 GTW_intakeAirFilterType 1 "HEPA" 0 "STANDARD" ;
VAL_ 2047 GTW_eBuckConfig 1 "DEV_BUCK" 0 "NONE" ;
VAL_ 2047 GTW_steeringHeaterEnabled 1 "ENABLED" 0 "DISABLED" ;
VAL_ 2047 GTW_activeHighBeam 1 "ACTIVE" 0 "NOT_ACTIVE" ;
VAL_ 2047 GTW_airbagCutoffSwitch 1 "CUTOFF_SWITCH_ENABLED" 0 "CUTOFF_SWITCH_DISABLED" ;
VAL_ 2047 GTW_intrusionSensorType 1 "VODAFONE" 0 "NOT_INSTALLED" ;
VAL_ 2047 GTW_spoilerType 1 "PASSIVE" 0 "NOT_INSTALLED" ;
VAL_ 2047 GTW_rearFogLamps 1 "INSTALLED" 0 "NOT_INSTALLED" ;
VAL_ 2047 GTW_roofType 1 "FIXED_GLASS" ;
VAL_ 2047 GTW_thirdRowSeatType 1 "FLAT_FOLD" 0 "NONE" ;
VAL_ 2047 GTW_autopilot 4 "BASIC" 3 "SELF_DRIVING" 2 "ENHANCED" 1 "HIGHWAY" 0 "NONE" ;
VAL_ 2047 GTW_superchargingAccess 2 "PAY_AS_YOU_GO" 1 "ALLOWED" 0 "NOT_ALLOWED" ;
VAL_ 2047 GTW_exteriorColor 20 "COASTAL_BLUE" 17 "MARINE_BLUE" 16 "SILKROAD_SILVER" 15 "DIAMOND_BLACK" 14 "GLACIER_BLUE" 13 "FROST_BLUE" 11 "STEALTH_GREY" 10 "ULTRA_RED" 9 "QUICKSILVER" 8 "ABYSS_BLUE" 7 "MIDNIGHT_CHERRY_RED" 6 "PEARL_WHITE" 5 "DEEP_BLUE" 3 "MIDNIGHT_SILVER" 2 "SILVER_METALLIC" 1 "SOLID_BLACK" 0 "RED_MULTICOAT" ;
VAL_ 2047 GTW_pedestrianWarningSound 2 "EXT_SPEAKER_V2" 1 "SPEAKER" 0 "NONE" ;
VAL_ 2047 GTW_steeringColumnUJointType 1 "C_SAMPLE_PHASING" ;
VAL_ 2047 GTW_bPillarNFCParam 1 "MODEL_Y" 0 "MODEL_3" ;
VAL_ 2047 GTW_interiorLighting 6 "FOOTWELL" 5 "FOOTWELL_RGB_IP" 4 "PREMIUM_WITH_RGB_IP_ONLY" 3 "PREMIUM_WITH_RGB" 2 "PREMIUM_NO_POCKET_LIGHT" 1 "PREMIUM" 0 "BASE" ;
VAL_ 2047 GTW_headlightLevelerType 2 "VIRTUAL_PITCH_SENSOR" 1 "GEN1" 0 "NONE" ;
VAL_ 2047 GTW_numberHVILNodes 3 "HVIL_NODES_3" 2 "HVIL_NODES_2" 0 "HVIL_NODES_0" ;
VAL_ 2047 GTW_mapRegion 13 "LA" 12 "IN" 11 "SE" 10 "MO" 9 "HK" 8 "ME" 7 "KR" 6 "TW" 5 "JP" 4 "AU" 3 "CN" 2 "NONE" 1 "EU" 0 "US" ;
VAL_ 2047 GTW_performancePackage 4 "BASE_2022" 3 "BASE_PLUS" 2 "BASE_2024" 1 "PERFORMANCE" 0 "BASE" ;
VAL_ 2047 GTW_chassisType 7 "MODEL_Y_LONG_WHEELBASE_CHASSIS_PATRONUS" 3 "MODEL_Y_CHASSIS" 2 "MODEL_3_CHASSIS" ;
VAL_ 2047 GTW_airSuspension 3 "COIL_ADAPTIVE_DAMPING" 0 "NONE" ;
VAL_ 2047 GTW_centerConsoleControllerType 2 "INSTALLED_NO_AIRWAVE" 1 "INSTALLED_V1" 0 "NONE" ;
VAL_ 2047 GTW_autopilotCameraType 1 "RGGB_CAMERAS" 0 "RCCB_CAMERAS" ;
VAL_ 2047 GTW_connectivityPackage 1 "PREMIUM" 0 "BASE" ;
VAL_ 2047 GTW_plcSupportType 2 "NATIVE_CHARGE_PORT" 1 "ONBOARD_ADAPTER" 0 "NONE" ;
VAL_ 2047 GTW_packEnergy 2 "MR" 1 "LR" 0 "SR" ;
VAL_ 2047 GTW_frontSeatReclinerHardware 3 "LEFT_RIGHT_SEAT_REDUCED_RANGE" 2 "LEFT_SEAT_REDUCED_RANGE" 1 "RIGHT_SEAT_REDUCED_RANGE" 0 "STANDARD_RANGE" ;
VAL_ 2047 GTW_brakeLineSwitchType 1 "VC_ONLY" 0 "DI_VC_SHARED" ;
VAL_ 2047 GTW_espValveType 2 "VALVE_TYPE_2" 1 "VALVE_TYPE_1" 0 "UNKNOWN" ;
VAL_ 2047 GTW_softRange 4 "RANGE_260_MILES" 3 "RANGE_343_MILES" 2 "RANGE_93_MILES" 1 "RANGE_220_MILES" 0 "STANDARD" ;
VAL_ 2047 GTW_refrigerantType 2 "R1234YF" 1 "R134A" 0 "Default" ;
VAL_ 2047 GTW_wheelType 52 "UBERHELIX_20" 51 "GEMINI_19_DARK_STAGGERED" 50 "HELIX_V2_20_DARK" 48 "MACHINA_V2_19_STAGGERED" 47 "GLIDER_18_CAP_KIT" 46 "APERTURE_18" 41 "ARACHNID_V2_21" 40 "HELIX_V2_20" 39 "CROSSFLOW_19" 33 "WISHBONE_20_STAGGERED" 31 "HELIX_19" 30 "GLIDER_18" 27 "ZEROG_19_GUNPOWDER" 24 "PINWHEEL_REFRESH_18_CAP_KIT" 23 "UBERTURBINE_20_GUNPOWDER" 22 "PINWHEEL_REFRESH_18" 21 "STILETTO_REFRESH_19" 19 "ZEROG_20_GUNPOWDER" 18 "PINWHEEL_18_CAP_KIT" 14 "STILETTO_20_DARK_SQUARE" 5 "GEMINI_19_STAGGERED" 4 "GEMINI_19_SQUARE" 3 "STILETTO_20_DARK_STAGGERED" 2 "STILETTO_20" 1 "STILETTO_19" 0 "PINWHEEL_18" ;
VAL_ 2047 GTW_ptcControlMode 3 "SEQ_ROD_LIMITED" 2 "MESH_INSTALLED" 1 "SEQ_ROD" 0 "BASELINE" ;
VAL_ 2047 GTW_brakeActuationType 2 "ESP_DPB" 1 "IDB_RCU" 0 "ESP_IBST" ;
VAL_ 2047 GTW_secondRowSeatType 6 "TWO_SEATS_POWERED_RECLINE" 5 "FLAT_FOLD_V2" 4 "EASY_ENTRY_POWERED_RECLINE" 3 "POWERED_RECLINE" ;
VAL_ 2047 GTW_secondRowSeatMotorType 1 "KEIPER" 0 "SHB" ;
VAL_ 2047 GTW_eCallEnabled 2 "ENABLED_UI_SOS" 1 "ENABLED_OHC_SOS" 0 "DISABLED" ;
VAL_ 2047 GTW_parkAssistECUType 2 "NONE" 1 "TESLA" 0 "VALEO" ;
VAL_ 2047 GTW_passengerAirbagType 2 "EUROW" 1 "SAFETY_VENT" 0 "FULL_SUPPRESSION" ;
VAL_ 2047 GTW_forwardRadarHw 2 "NONE" 0 "CONTI_ARS410" ;
VAL_ 2047 GTW_frontSeatType 13 "PREMIUM_L_YANFENG_MINITILT_R_TESLA_MINITILT" 12 "PREMIUM_L_YANFENG_MINITILT_R_YANFENG_MINITILT" 11 "PREMIUM_L_YANFENG_MINITILT_R_YANFENG" 10 "PREMIUM_L_YANFENG_R_YANFENG_MINITILT" 9 "PREMIUM_L_TESLA_MINITILT_R_YANFENG_MINITILT" 8 "PREMIUM_L_TESLA_MINITILT_R_TESLA_MINITILT" 7 "PREMIUM_L_TESLA_MINITILT_R_TESLA" 6 "PREMIUM_L_TESLA_R_TESLA_MINITILT" 5 "PREMIUM_BROSE" 4 "PREMIUM_YANFENG" 3 "PREMIUM_L_TESLA_R_YANFENG" 2 "PREMIUM_L_YANFENG_R_TESLA" 1 "PREMIUM_TESLA" 0 "BASE_TESLA" ;
VAL_ 2047 GTW_secondRowDisplayType 1 "TYPE_1" 0 "NONE" ;
VAL_ 2047 GTW_wirelessPhoneChargerType 3 "FRONT_HIGH_POWER_UART" 1 "FRONT_LIN" 0 "NONE_OR_USB" ;
VAL_ 2047 GTW_ethernetTunerType 3 "HARMAN_GEN3" 2 "HIRSCHMANN" 1 "NONE" 0 "HARMAN" ;
VAL_ 2047 GTW_interiorTrimType 3 "WHITE_CONSOLE_2" 2 "BLACK_CONSOLE_2" 1 "WHITE" 0 "BLACK" ;
VAL_ 2047 GTW_gloveboxUSBType 2 "TSC_USB3_A_PLUS_BT" 1 "TSC_USB3_A" 0 "NOT_INSTALLED" ;
VAL_ 2047 GTW_coolantPumpType 5 "DUAL_MIX" 4 "DUAL_SAN_P4_LUB" 2 "DUAL_SAN_P4" 1 "SINGLE_PUMP_BATT" 0 "DUAL" ;
VAL_ 2047 GTW_epblHwType 8 "ZF" 5 "BREMBO_V2" 4 "BREMBO_V1" 2 "MANDO_V2" 1 "MANDO_V1" 0 "NOT_SET" ;
VAL_ 2047 GTW_epbrHwType 8 "ZF" 5 "BREMBO_V2" 4 "BREMBO_V1" 2 "MANDO_V2" 1 "MANDO_V1" 0 "NOT_SET" ;
VAL_ 2047 GTW_blowerMotorType 1 "DELTA" 0 "SHINANO" ;
VAL_ 2047 GTW_rearLeftBLEEndpointParameter 1 "VIVALDI_ANTENNA" 0 "NONE" ;
VAL_ 2047 GTW_frontUsbHubType 4 "NO_DATA" 0 "2" ;
VAL_ 2047 GTW_superManifoldType 2 "TYPE2" 1 "TYPE1" 0 "TYPE0" ;
VAL_ 2047 GTW_rcmLocation 0 "CENTER_CONSOLE" ;
VAL_ 2047 GTW_interiorCamFanType 3 "NIDEC" 2 "DELTA_FDB" 0 "NONE" ;
VAL_ 2047 GTW_interiorCamBeautyCoverType 2 "PITCHED_DOWN" 1 "PITCHED_UP" 0 "STANDARD" ;
VAL_ 2047 GTW_sirenType 1 "VODAPHONE_IF_INTRUSION" 0 "NONE" ;
VAL_ 2047 GTW_hornType 1 "EXT_SPEAKER_V2" 0 "TRUMPET" ;
VAL_ 2047 GTW_badgingVersion 1 "VERSION_1" 0 "VERSION_0" ;
VAL_ 2047 GTW_steeringColumnMotorType 3 "NEXTEER" 2 "BOSCH_COMMON_TO_JE" 1 "JE" 0 "BOSCH" ;
VAL_ 2047 GTW_refrigACLineType 2 "CONTI_LIMITED" 1 "SAAA_LIMITED" 0 "UNLIMITED" ;
VAL_ 2047 GTW_refrigFilterType 2 "BLOCKED_V2" 1 "BLOCKED_V1" 0 "UNBLOCKED" ;
VAL_ 2047 GTW_diBurnInType 1 "ENABLED_V1" 0 "NONE" ;
VAL_ 2047 GTW_specialBadgingType 2 "LAUNCH_SERIES" 0 "NONE" ;
VAL_ 2047 GTW_chassisSubType 3 "TRIM_DEVIATION_1" 2 "PERFORMANCE" 1 "BASE" 0 "UNKNOWN" ;
VAL_ 2047 GTW_frontSeatVentilationType 1 "TYPE_1" 0 "NONE" ;
VAL_ 2047 GTW_towPackage 2 "TESLA_REV2" 1 "TESLA_REV1" 0 "NONE" ;
VAL_ 2047 GTW_refrigLccType 1 "LCCR" 0 "LCC" ;
VAL_ 2047 GTW_caliperColorType 2 "RED" 1 "GREY" 0 "UNKNOWN" ;
VAL_ 2047 GTW_wiperMotorType 1 "SHB" 0 "NOT_UPDATEABLE" ;
VAL_ 2047 GTW_frontOverheadConsoleType 3 "KOSTAL" 2 "PREH" 1 "BITRON" 0 "VALEO" ;
VAL_ 2047 GTW_shifterType 1 "DISPLAY" 0 "STALK" ;
VAL_ 2047 GTW_compressorType 10 "SANDEN_V4_1" 8 "SANDEN_V4" 7 "SANDEN_V3" 6 "SANDEN_V1_1" 5 "SANDEN_V2" 4 "DENSO_11K_COP1_ENABLED" 3 "SANDEN" 2 "DENSO_41CC_11K" 1 "DENSO_41CC_8K" 0 "HANON_33CC" ;
VAL_ 2047 GTW_twelveVBatteryType 3 "TESLA_16V_LI_ION" 2 "CATL_LI_ION" 1 "CLARIOS_B24_FLOODED" 0 "ATLASBX_B24_FLOODED" ;
VAL_ 2047 GTW_efuseSWConfig 3 "ALL_ENABLED" 2 "SQUARE_ENABLED" 1 "ROUND_ENABLED" 0 "DISABLED" ;
VAL_ 2047 GTW_tollCollectionModuleType 1 "WANJI_V1" 0 "NONE" ;
VAL_ 2047 GTW_bleEndpointUpdateMethod 1 "BOOTLOADER_UPDATE" ;
VAL_ 2047 GTW_steeringWheelControllerType 5 "DUAL_TESLA_GEN5" 2 "DUAL_KOSTAL" 1 "DUAL_PREH" ;
VAL_ 2047 GTW_frontSeatVentilationEnabled 1 "ENABLED" 0 "DISABLED" ;
VAL_ 2047 GTW_gloveboxActuatorType 2 "ELECTROMAGNET" 1 "SMA" 0 "SOLENOID" ;
VAL_ 2047 GTW_epasType 8 "THYSSENKRUPP_CGR65" 7 "MANDO_CGR65" 6 "THYSSENKRUPP_VGR69" 5 "MANDO_CGR69_SINGLE_ECU" 4 "MANDO_CGR69" 3 "MANDO_VGR69_GEN3_SINGLE_ECU" 0 "MANDO_VGR69_GEN3" ;
VAL_ 2047 GTW_homologationRegionOverride 2 "MX_UNECE" 1 "KR_UNECE" 0 "DEFAULT_FOR_COUNTRY_CODE" ;
VAL_ 2047 GTW_windowCommandsPermissionType 2 "US_FMVSS_S6" 1 "US_FMVSS_S4" 0 "ROW_OR_US_FMVSS_S5" ;
VAL_ 2047 GTW_headlightStepperStallDetectM 1 "ENABLED" 0 "DISABLED" ;
VAL_ 2047 GTW_rgbInteriorLightingEnabled 2 "ALL_COLORS" 1 "WHITE_ONLY" 0 "DISABLED_OR_NA" ;
VAL_ 2047 GTW_windshieldWiperHeaterType 1 "TYPE_1" 0 "NOT_INSTALLED" ;
VAL_ 2047 GTW_driveInterfaceType 1 "EXTERNAL" 0 "COMBINED" ;
VAL_ 2047 GTW_efficiencyPackage 42 "MY_2026_US" 39 "MY_2025_CN_PLUS" 38 "MY_2026_M53" 34 "MY_STANDARD_2026" 33 "MY_REFRESH_2025_CN_ALL_US_LR_RWD" 32 "MY_REFRESH_2025_ROW" 24 "MY_2024_GFSH_EXPORT_NA_SR_RWD" 23 "MY_2024C" 20 "MY_2023_SR_RWD" 16 "MY_2024" 15 "MY_2023_GFSH_EXPORT_NA" 12 "MY_RWD_EU_2022" 11 "MY_SR_PLUS_2022_Q1_TX" 9 "MY_SR_PLUS_2021_Q3_GFSH" 7 "MY_2021" 5 "MY_2020" 0 "DEFAULT" ;
VAL_ 2047 GTW_visorLightType 1 "DIMMABLE_TYPE_1" 0 "NON_DIMMABLE" ;
VAL_ 2047 GTW_gnssAntennaType 2 "GEN2_WITH_METAL_INSERT" 1 "GEN2_NO_METAL_INSERT" 0 "NA_OR_GEN1" ;
VAL_ 2047 GTW_frontSeatHeatersEnabled 1 "ENABLED" 0 "DISABLED" ;
VAL_ 2047 GTW_windshieldWiperHeaterEnabled 1 "ENABLED_OR_NA" 0 "DISABLED" ;
VAL_ 2047 GTW_tcuType 1 "5G" 0 "4G" ;
VAL_ 2047 GTW_fasciaType 8 "E41_BAYBERRY" 4 "PERFORMANCE_BAYBERRY" 3 "BASE_BAYBERRY" 0 "ORIGINAL" ;
VAL_ 2047 GTW_powerSteeringColumn 1 "TK" 0 "NOT_INSTALLED" ;
VAL_ 2047 GTW_frontSeatHeaterType 1 "GENTHERM" 0 "KONGSBERG" ;
VAL_ 2047 GTW_softPerformanceLimit 6 "LIMIT_230_KW" 4 "LIMIT_110_MPH" 2 "LIMIT_110_KW" 1 "LIMIT_160_KW" 0 "NONE" ;
VAL_ 2047 GTW_alcoholInterlockType 1 "TYPE_1" 0 "NONE" ;
VAL_ 2047 GTW_immersiveAudio 2 "PREMIUM" 1 "BASE" 0 "DISABLED" ;
VAL_ 2047 GTW_passengerOccupancySensorType 4 "NONE" 1 "RESISTIVE_PAD" 0 "OCS" ;
VAL_ 2047 GTW_packPerformanceDeviation 5 "PACK_POWER_DEVIATION_2" 4 "PACK_MASS_DEVIATION_2" 3 "PACK_STRUCTURAL_DEVIATION_1" 2 "PACK_POWER_DEVIATION_1" 1 "PACK_MASS_DEVIATION_1" 0 "NO_DEVIATION" ;
VAL_ 2047 GTW_frontFogLamps 1 "INSTALLED" 0 "NOT_INSTALLED" ;
VAL_ 2047 GTW_driverOccupancySensorType 1 "NONE" 0 "RESISTIVE_PAD" ;
VAL_ 2047 GTW_audioType 4 "ESSENTIAL_WITH_COMMODITY100" 3 "ESSENTIAL" 1 "PREMIUM" 0 "BASE" ;
VAL_ 2047 GTW_occupancyClassificationFeatu 1 "TESLA_CABIN_RADAR" 0 "DISCRETE_SENSOR_OR_NA" ;
VAL_ 2047 GTW_domeLightType 2 "TESLA_2R" ;
VAL_ 2047 GTW_tpmsType 2 "INDIRECT" 1 "TESLA_BLE" 0 "CONTI_2" ;
VAL_ 2047 GTW_authenticationEndpointLayout 2 "MY_LAYOUT_2" 1 "M3_LAYOUT_2" 0 "LAYOUT_1" ;
VAL_ 2047 GTW_socSleepOverride 2 "FORCE_SHALLOW" 1 "FORCE_S3" 0 "PN_DERIVED" ;
VAL_ 2047 GTW_r79BehaviorOverride 1 "R79_ENABLED" 0 "NO_OVERRIDE" ;
VAL_ 2047 GTW_steeringHeaterType 7 "YF_V2" 4 "ZF_ROUND" 0 "NONE" ;
VAL_ 2047 GTW_sohRegulatoryStatus 1 "REGULATED_SOH" 0 "NON_REGULATED_SOH" ;
VAL_ 2047 GTW_m3yBusArchitecture 2 "PRIVATE_TORQUE_CHASSIS" 1 "PRIVATE_TORQUE" 0 "PUBLIC_TORQUE" ;
VAL_ 2047 GTW_blindSpotIndicatorLightType 1 "INSTALLED_TYPE_1" 0 "NOT_INSTALLED" ;
VAL_ 2047 GTW_hvacCaseDoorType 1 "FLAT_EDGE" 0 "SERRATED_EDGE" ;
VAL_ 2047 GTW_occupancyDetectionSourceRequ 1 "TESLA_CABIN_RADAR" 0 "DISCRETE_SENSOR_OR_NA" ;
VAL_ 2047 GTW_rduCableType 1 "COPPER" 0 "ALUMINUM" ;
VAL_ 2047 GTW_interiorCameraType 1 "VD6763" 0 "AR0136" ;
VAL_ 2047 GTW_frontFasciaCameraType 2 "IMX00N" 1 "IMX963" 0 "NONE" ;
VAL_ 1638 GTW_diagLevel 100 "LEVEL_NORMAL_OPERATION" 80 "LEVEL_PARK" 70 "LEVEL_PARK_ROBOTAXI" 50 "LEVEL_SERVICE_DRIVE" 25 "LEVEL_SERVICE" 10 "LEVEL_DIAG_LINK_ACTIVE" 0 "LEVEL_FACTORY" ;
VAL_ 1080 GTW_ethWakeUpReason 15 "GTW_WAKEUP_REASON_RCMPRIVATE_CAN" 14 "GTW_WAKEUP_REASON_VCLEFT" 13 "GTW_WAKEUP_REASON_LOOP" 12 "GTW_WAKEUP_REASON_DISPLAY_TAP" 11 "GTW_WAKEUP_REASON_URGENT_TRANSMIT_ALERT" 10 "GTW_WAKEUP_REASON_BDY_CAN" 9 "GTW_WAKEUP_REASON_PT_CAN" 8 "GTW_WAKEUP_REASON_UI_SCHEDULED" 7 "GTW_WAKEUP_REASON_RTC_ALARM" 6 "GTW_WAKEUP_REASON_VCFRONT" 5 "GTW_WAKEUP_REASON_VEH_CAN" 4 "GTW_WAKEUP_REASON_ETH_CAN" 3 "GTW_WAKEUP_REASON_CH_CAN" 2 "GTW_WAKEUP_REASON_GSM_RI" 1 "GTW_WAKEUP_REASON_RESET" 0 "GTW_WAKEUP_REASON_NONE" ;
VAL_ 1656 GTW_gearShiftRequest 4 "GEAR_REQUEST_DRIVE" 3 "GEAR_REQUEST_NEUTRAL" 2 "GEAR_REQUEST_REVERSE" 1 "GEAR_REQUEST_PARK" 0 "GEAR_REQUEST_IDLE_SNA" ;
VAL_ 1656 GTW_primaryGearControlStatus 14 "NOT_QUALIFIED_RHD_CONFIG_UNAVAILABLE" 13 "NOT_QUALIFIED_DISPLAY_KNOWN_FROZEN_SCREEN" 12 "NOT_QUALIFIED_DISPLAY_ASIL_VIDEO_ERROR" 11 "NOT_QUALIFIED_GEAR_STRIP_MISMATCH" 10 "NOT_QUALIFIED_DISPLAY_UNTRAINED" 9 "NOT_QUALIFIED_UI_NO_RESP_GEAR_STRIP" 8 "NOT_QUALIFIED_CENTER_DISP_UI_UNHEALTHY" 7 "NOT_QUALIFIED_DISPLAY_FROZEN_ON_GESTURE" 6 "NOT_QUALIFIED_LOW_BRIGHTNESS" 5 "NOT_QUALIFIED_FALSE_TOUCH" 4 "NOT_QUALIFIED_MANUAL" 3 "NOT_QUALIFIED_DISPLAY_ERRS" 2 "NOT_QUALIFIED_FULLSCREEN" 1 "QUALIFIED" 0 "NOT_QUALIFIED" ;
VAL_ 1656 GTW_autoParkRequest 1 "ACTIVE" 0 "IDLE" ;
VAL_ 1656 GTW_smartShiftStatus 9 "DISABLED_AUDIO_NOT_READY" 8 "DISABLED_OSD_ACTIVATED" 7 "DISABLED_DISQUALIFIED" 6 "DISABLED_FULLSCREEN" 5 "DISABLED_UI_MIA" 4 "DISABLED_CLUSTER_DISP_ERR" 3 "DISABLED_CENTER_DISP_ERR" 2 "DISABLED_UI_CONFIG" 1 "ENABLED" 0 "DISABLED_SNA" ;
VAL_ 1656 GTW_gearStripChangeReason 27 "EBUCK_DISABLE" 26 "SLEEP_DISABLE" 25 "VC_MIA_GRACE_DISABLE" 24 "VC_MIA_ENABLE" 23 "DRIVERLESS_NO_TAKEOVER_DISABLE" 22 "EMERGENCY_OPERATION_ENABLE" 21 "WOT_ENABLE" 20 "PARK_ENGAGED_ENABLE" 19 "MISSING_SPEED_OR_STEERING_ESTIMATE_IN_D_ENABLE" 18 "UI_MIA_ENABLE" 16 "NOT_DRIVE_STATE_DISABLE" 15 "FULLSCREEN_DISABLE" 14 "DEFAULT_DISABLE" 13 "REVERSE_ENABLE" 12 "NEUTRAL_ENABLE" 11 "P_AND_BRAKE_ENABLE" 10 "CHARGING_DISABLE" 9 "CRUISE_ACTIVE_DISABLE" 8 "DI_MIA_ENABLE" 7 "HIGH_ACCEL_DISABLE" 6 "MEDIUM_SPEED_DISABLE" 5 "TRAFFIC_CONTROL_NO_CHANGE" 4 "VERY_LOW_SPEED_ENABLE" 3 "HIGH_STEERING_ANGLE_ENABLE" 2 "HIGH_JERK_ENABLE" 1 "DRIVER_BRAKE_APPLY_ENABLE" 0 "SNA" ;
VAL_ 1656 GTW_screenPCBTemperature 2047 "GTW_I2C_TEMP_SNA" ;
VAL_ 2033 GTW_hrlIndex 2 "Mux2" 1 "Mux1" ;
VAL_ 2033 GTW_hrlState 1 "ENABLED" 0 "DISABLED" ;
VAL_ 2033 GTW_hrlTriggerType 15 "HRL_TRIGGER_NONE" 5 "HRL_TRIGGER_EVENT_EXTERNAL" 4 "HRL_TRIGGER_PSEUDONYMOUS" 3 "HRL_TRIGGER_CONTINUOUS" 2 "HRL_TRIGGER_GAME_MODE" 1 "HRL_TRIGGER_EVENT" 0 "HRL_TRIGGER_UDPAPI" ;
VAL_ 60 GTW_infoIndex 255 "END" 31 "SUBCOMPONENT_GITHASH" 30 "PACKAGE_SN_8_14" 29 "PACKAGE_SN_1_7" 27 "PACKAGE_PN_15_20" 26 "PACKAGE_PN_8_14" 25 "PACKAGE_PN_1_7" 23 "SUBCOMPONENT2" 22 "VARIANTCRC" 20 "UDS_PROTOCOL_BOOTCRC" 19 "VERSION_DEPRECATED" 18 "BOOTLOADER_GITHASH" 17 "APP_GITHASH" 16 "SUBCOMPONENT" 15 "BOOTLOADER_CRC" 14 "BOOTLOADER_SVN" 13 "APP_CRC" 11 "PCBAID_ASSYID_USAGEID" 10 "BUILD_HWID_COMPONENTID" 9 "DEPRECATED_9" 8 "DEPRECATED_8" 7 "DEPRECATED_7" 6 "DEPRECATED_6" 5 "DEPRECATED_5" 4 "DEPRECATED_4" 3 "DEPRECATED_3" 2 "DEPRECATED_2" 1 "DEPRECATED_1" 0 "DEPRECATED_0" ;
VAL_ 60 GTW_buildType 4 "INFO_MFG_BUILD" 3 "INFO_TRACEABLE_CI_BUILD" 2 "INFO_LOCAL_BUILD" 1 "INFO_PLATFORM_BUILD" 0 "INFO_UNKNOWN_BUILD" ;
VAL_ 60 GTW_platformType 255 "GTW_PLATFORM_END" 3 "GTW_PLATFORM_MODEL3" 0 "GTW_PLATFORM_UNKNOWN" ;
VAL_ 1370 GTW_mismatchFaultIndex 4 "Mux4" 3 "Mux3" 2 "Mux2" 1 "Mux1" ;
VAL_ 840 GTW_vehicleVersionMatchStatus 2 "MATCHED" 1 "MISMATCHED" 0 "NOT_CALCULATED_YET" ;
VAL_ 840 GTW_hwtype 3 "TRAVEO2" 2 "SPC58" 1 "MPC57" 0 "SNA" ;
VAL_ 840 GTW_jcanProductName 11 "SEMITRUCKV2" 10 "GOLDENSNITCH" 8 "BAYBERRY" 7 "CYBERTRUCK" 6 "POPPYSEED" 5 "SEMITRUCK" 4 "TAMARIND" 3 "LYCHEE" 2 "MODELY" 1 "MODEL3" 0 "SNA" ;
VAL_ 840 GTW_sentryModeState 6 "SNA" 5 "QUIET" 4 "PANIC" 3 "AWARE" 2 "ARMED" 1 "IDLE" 0 "OFF" ;
VAL_ 840 GTW_socSleepType 2 "SHALLOW" 1 "S3" 0 "SNA" ;
VAL_ 840 GTW_resetType 7 "TOUCHCORE_WATCHDOG" 6 "CANCORE_WATCHDOG" 5 "MAINCORE_WATCHDOG" 4 "WAKE" 3 "BUTTON" 2 "SOFTWARE" 1 "POR" 0 "SNA" ;
VAL_ 1112 GTW_nmKeepAwakeReason 15 "GTW_KEEPAWAKE_REASON_TBD" 7 "GTW_KEEPAWAKE_REASON_TCU_TC10_VERSION_UNSUPPORTED" 6 "GTW_KEEPAWAKE_REASON_TCU_TC10_VERSION_CHECK" 5 "GTW_KEEPAWAKE_REASON_EGGLEFT_LINK_DOWN" 4 "GTW_KEEPAWAKE_REASON_URGENT_TRANSMIT_ALERT" 3 "GTW_KEEPAWAKE_REASON_FCSM_ACTIVE" 2 "GTW_KEEPAWAKE_REASON_GSM_RI" 1 "GTW_KEEPAWAKE_REASON_UI_SCHEDULED" 0 "GTW_KEEPAWAKE_REASON_NONE_SNA" ;
VAL_ 1112 GTW_nmWakeUpReason 15 "GTW_WAKEUP_REASON_RCMPRIVATE_CAN" 14 "GTW_WAKEUP_REASON_VCLEFT" 13 "GTW_WAKEUP_REASON_LOOP" 12 "GTW_WAKEUP_REASON_DISPLAY_TAP" 11 "GTW_WAKEUP_REASON_URGENT_TRANSMIT_ALERT" 10 "GTW_WAKEUP_REASON_BDY_CAN" 9 "GTW_WAKEUP_REASON_PT_CAN" 8 "GTW_WAKEUP_REASON_UI_SCHEDULED" 7 "GTW_WAKEUP_REASON_RTC_ALARM" 6 "GTW_WAKEUP_REASON_VCFRONT" 5 "GTW_WAKEUP_REASON_VEH_CAN" 4 "GTW_WAKEUP_REASON_ETH_CAN" 3 "GTW_WAKEUP_REASON_CH_CAN" 2 "GTW_WAKEUP_REASON_GSM_RI" 1 "GTW_WAKEUP_REASON_RESET" 0 "GTW_WAKEUP_REASON_NONE" ;
VAL_ 1112 GTW_ethKeepAwakeReason 3 "TCU_TC10_VERSION_UNSUPPORTED" 2 "TCU_TC10_VERSION_CHECK" 1 "URGENT_TRANSMIT_ALERT" 0 "NONE_SNA" ;
VAL_ 1112 GTW_nmDebugWakeUp 2147483648 "WKPU_31" 1073741824 "WKPU_30" 536870912 "WKPU_29" 268435456 "WKPU_28" 134217728 "WKPU_27" 67108864 "WKPU_26" 33554432 "WKPU_25" 16777216 "WKPU_24" 8388608 "WKPU_23" 4194304 "WKPU_22" 2097152 "WKPU_21" 1048576 "WKPU_20" 524288 "WKPU_19" 262144 "WKPU_18" 131072 "WKPU_17" 65536 "WKPU_16" 32768 "WKPU_15" 16384 "WKPU_14" 8192 "WKPU_13" 4096 "WKPU_12" 2048 "WKPU_11" 1024 "WKPU_10" 512 "WKPU_9" 256 "WKPU_8" 128 "WKPU_7" 64 "WKPU_6" 32 "WKPU_5" 16 "WKPU_4" 8 "WKPU_3" 4 "WKPU_2" 2 "WKPU_1" 1 "WKPU_0" 0 "WKPU_NONE" ;
VAL_ 1470 IDB_alertID 144 "a144_hydraulicPushthroughActive" 143 "a143_factoryModeActive" 142 "a142_PMebrCmdStateInvalid" 141 "a141_DIbrakeTorqueCommandFullTooLow" 140 "a140_PMbrakePedalCmdQFInvalid" 139 "a139_DIbrakeTorqueCommandFullSNA" 138 "a138_DIbrakeTorqueCommandAndFlagMismatch" 137 "a137_VCLEFTcdpRequestInvalid" 136 "a136_RCUptsCalMissing" 135 "a135_DIbrakeCommandChecksum" 134 "a134_DIbrakeCommandCounter" 133 "a133_DIbrakeCommandDLC" 132 "a132_RCUinputRodStrokeQFInvalid" 131 "a131_DIfullTorquePathActive" 130 "a130_DIfullTorqueRequestInvalid" 129 "a129_RCUinputRodStrokeInvalid" 128 "a128_reserved1" 127 "a127_brakeFluidLevelInvalid" 126 "a126_DItorqueRequestInvalid" 125 "a125_PMvdcCmdStateInvalid" 124 "a124_VCFRONTtempInvalid" 123 "a123_DIRtorqueCommandInvalid" 122 "a122_DIFtorqueCommandInvalid" 121 "a121_dynoModeActive" 120 "a120_EPAS3Pinvalid" 119 "a119_VCLEFTepbmStatusChecksum" 118 "a118_VCLEFTepbmStatusCounter" 117 "a117_VCLEFTepbmStatusDLC" 116 "a116_VCFRONTsensorsDLC" 115 "a115_VCFRONTespLvStInvalid" 114 "a114_longAccelInvalid" 113 "a113_latAccelInvalid" 112 "a112_yawRateInvalid" 111 "a111_EPBstatusChecksum" 110 "a110_EPBstatusCounter" 109 "a109_BDWsignalInvalid" 108 "a108_EPBstatusDLC" 107 "a107_DIRtorqueInvalid" 106 "a106_DIFtorqueInvalid" 105 "a105_DIgearInvalid" 104 "a104_DIaccelPosInvalid" 103 "a103_DIfullTorquePathFaulted" 102 "a102_bdwRequestActiveInvalid" 101 "a101_RCMcollisionCounter" 100 "a100_RCMcollisionChecksum" 99 "a099_RCMcollisionDLC" 98 "a098_VCFRONTLVPwrStCounter" 97 "a097_VCFRONTLVPwrStChecksum" 96 "a096_VCFRONTLVPowerStateDLC" 95 "a095_RCMinertial2Counter" 94 "a094_RCMinertial2Checksum" 93 "a093_RCMinertial2DLC" 92 "a092_RCMinertial1Counter" 91 "a091_RCMinertial1Checksum" 90 "a090_RCMinertial1DLC" 89 "a089_PMstate2Counter" 88 "a088_PMstate2Checksum" 87 "a087_PMstate2DLC" 86 "a086_EPAS3PsysStatusCounter" 85 "a085_EPAS3PsysStatusChecksum" 84 "a084_EPAS3PsysStatusDLC" 83 "a083_DIvdcRightCounter" 82 "a082_DIvdcRightChecksum" 81 "a081_DIvdcRightDLC" 80 "a080_DIvdcLeftCounter" 79 "a079_DIvdcLeftChecksum" 78 "a078_DIvdcLeftDLC" 77 "a077_DIRtorqueCounter" 76 "a076_DIRtorqueChecksum" 75 "a075_DIRtorqueDLC" 74 "a074_DIsystemStatusCounter" 73 "a073_DIsystemStatusChecksum" 72 "a072_DIsystemStatusDLC" 71 "a071_DIchassisControlCounter" 70 "a070_DIchassisControlChecksum" 69 "a069_DIchassisControlDLC" 68 "a068_DIFtorqueCounter" 67 "a067_DIFtorqueChecksum" 66 "a066_DIFtorqueDLC" 65 "a065_RCUactuationCounter" 64 "a064_RCUactuationChecksum" 63 "a063_RCUactuationDLC" 62 "a062_RCUstatusCounter" 61 "a061_RCUstatusChecksum" 60 "a060_RCUstatusDLC" 59 "a059_cdpFaulted" 58 "a058_scmFaulted" 57 "a057_bdwRequestInvalid" 56 "a056_fadeCompensationFaulted" 55 "a055_panicBrakeAssistFaulted" 54 "a054_skidDetectionFaulted" 53 "a053_DItorquePathFaulted" 52 "a052_vdcFaulted" 51 "a051_ebdFaulted" 50 "a050_absFaulted" 49 "a049_cdpActive" 48 "a048_scmActive" 47 "a047_brakeDiscWipeActive" 46 "a046_fadeCompensationActive" 45 "a045_panicBrakeAssistActive" 44 "a044_standstillSkidDetected" 43 "a043_DItorquePathActive" 42 "a042_btcActive" 41 "a041_vdcActive" 40 "a040_ebdActive" 39 "a039_absActive" 38 "a038_motorInitFault" 37 "a037_chassisBusOff" 36 "a036_partyBusOff" 35 "a035_motorStuck" 34 "a034_motorPositionSetFault" 33 "a033_motorHardOverheat" 32 "a032_motorSoftOverheat" 31 "a031_solenoidValveStuck" 30 "a030_fluidLeakDetected" 29 "a029_pressureSensNotCal" 28 "a028_simPresSensorFault" 27 "a027_circuitPresSensorFault" 26 "a026_axImplausible" 25 "a025_ayImplausible" 24 "a024_yawImplausible" 23 "a023_steeringImplausible" 22 "a022_brakeFluidLow" 21 "a021_pedalSensorNotCal" 20 "a020_RCUpedalTravelMismatch" 19 "a019_pedalSensorFault" 18 "a018_WSSGenericFault" 17 "a017_ReRWSSFault" 16 "a016_ReLWSSFault" 15 "a015_FrRWSSFault" 14 "a014_FrLWSSFault" 13 "a013_motorPosSensorFault" 12 "a012_motorGenericFault" 11 "a011_solenoidValveFault" 10 "a010_asicGenericFault" 9 "a009_asicBoostFault" 8 "a008_motorPowerOpen" 7 "a007_wakeLineOpen" 6 "a006_supplyHardUndervoltage" 5 "a005_supplyMidUndervoltage" 4 "a004_supplyUndervoltage" 3 "a003_supplyHardOvervoltage" 2 "a002_supplyOvervoltage" 1 "a001_mcuGenericFault" 0 "ALERT_DO_NOT_USE_ZERO" ;
VAL_ 1470 IDB_alertState 1 "SET" 0 "CLEARED" ;
VAL_ 1470 IDB_a014_wheelSpeedSensorFreq 1 "NOT_OK" 0 "OK" ;
VAL_ 1470 IDB_a014_wheelSpeedSensorPhase 1 "NOT_OK" 0 "OK" ;
VAL_ 1470 IDB_a014_wheelSpeedSensorMisinst 1 "NOT_OK" 0 "OK" ;
VAL_ 1470 IDB_a014_wheelSpeedSensorWrongEx 1 "NOT_OK" 0 "OK" ;
VAL_ 1470 IDB_a014_wheelSpeedSensorSpeedJu 1 "NOT_OK" 0 "OK" ;
VAL_ 1470 IDB_a014_wheelSpeedSensorSp_0001 1 "NOT_OK" 0 "OK" ;
VAL_ 1470 IDB_a014_wheelSpeedSensorAirGap 1 "NOT_OK" 0 "OK" ;
VAL_ 1470 IDB_a014_wheelSpeedSensorBIST 1 "NOT_OK" 0 "OK" ;
VAL_ 1470 IDB_a014_wheelSpeedSensorLeakage 1 "NOT_OK" 0 "OK" ;
VAL_ 1470 IDB_a014_wheelSpeedSensorOverTem 1 "NOT_OK" 0 "OK" ;
VAL_ 1470 IDB_a014_wheelSpeedSensorSh_0001 1 "NOT_OK" 0 "OK" ;
VAL_ 1470 IDB_a014_wheelSpeedSensorShortTo 1 "NOT_OK" 0 "OK" ;
VAL_ 1470 IDB_a014_wheelSpeedSensorOpen 1 "NOT_OK" 0 "OK" ;
VAL_ 1470 IDB_a015_wheelSpeedSensorFreq 1 "NOT_OK" 0 "OK" ;
VAL_ 1470 IDB_a015_wheelSpeedSensorPhase 1 "NOT_OK" 0 "OK" ;
VAL_ 1470 IDB_a015_wheelSpeedSensorMisinst 1 "NOT_OK" 0 "OK" ;
VAL_ 1470 IDB_a015_wheelSpeedSensorWrongEx 1 "NOT_OK" 0 "OK" ;
VAL_ 1470 IDB_a015_wheelSpeedSensorSpeedJu 1 "NOT_OK" 0 "OK" ;
VAL_ 1470 IDB_a015_wheelSpeedSensorSp_0001 1 "NOT_OK" 0 "OK" ;
VAL_ 1470 IDB_a015_wheelSpeedSensorAirGap 1 "NOT_OK" 0 "OK" ;
VAL_ 1470 IDB_a015_wheelSpeedSensorBIST 1 "NOT_OK" 0 "OK" ;
VAL_ 1470 IDB_a015_wheelSpeedSensorLeakage 1 "NOT_OK" 0 "OK" ;
VAL_ 1470 IDB_a015_wheelSpeedSensorOverTem 1 "NOT_OK" 0 "OK" ;
VAL_ 1470 IDB_a015_wheelSpeedSensorSh_0001 1 "NOT_OK" 0 "OK" ;
VAL_ 1470 IDB_a015_wheelSpeedSensorShortTo 1 "NOT_OK" 0 "OK" ;
VAL_ 1470 IDB_a015_wheelSpeedSensorOpen 1 "NOT_OK" 0 "OK" ;
VAL_ 1470 IDB_a016_wheelSpeedSensorFreq 1 "NOT_OK" 0 "OK" ;
VAL_ 1470 IDB_a016_wheelSpeedSensorPhase 1 "NOT_OK" 0 "OK" ;
VAL_ 1470 IDB_a016_wheelSpeedSensorMisinst 1 "NOT_OK" 0 "OK" ;
VAL_ 1470 IDB_a016_wheelSpeedSensorWrongEx 1 "NOT_OK" 0 "OK" ;
VAL_ 1470 IDB_a016_wheelSpeedSensorSpeedJu 1 "NOT_OK" 0 "OK" ;
VAL_ 1470 IDB_a016_wheelSpeedSensorSp_0001 1 "NOT_OK" 0 "OK" ;
VAL_ 1470 IDB_a016_wheelSpeedSensorAirGap 1 "NOT_OK" 0 "OK" ;
VAL_ 1470 IDB_a016_wheelSpeedSensorBIST 1 "NOT_OK" 0 "OK" ;
VAL_ 1470 IDB_a016_wheelSpeedSensorLeakage 1 "NOT_OK" 0 "OK" ;
VAL_ 1470 IDB_a016_wheelSpeedSensorOverTem 1 "NOT_OK" 0 "OK" ;
VAL_ 1470 IDB_a016_wheelSpeedSensorSh_0001 1 "NOT_OK" 0 "OK" ;
VAL_ 1470 IDB_a016_wheelSpeedSensorShortTo 1 "NOT_OK" 0 "OK" ;
VAL_ 1470 IDB_a016_wheelSpeedSensorOpen 1 "NOT_OK" 0 "OK" ;
VAL_ 1470 IDB_a017_wheelSpeedSensorFreq 1 "NOT_OK" 0 "OK" ;
VAL_ 1470 IDB_a017_wheelSpeedSensorPhase 1 "NOT_OK" 0 "OK" ;
VAL_ 1470 IDB_a017_wheelSpeedSensorMisinst 1 "NOT_OK" 0 "OK" ;
VAL_ 1470 IDB_a017_wheelSpeedSensorWrongEx 1 "NOT_OK" 0 "OK" ;
VAL_ 1470 IDB_a017_wheelSpeedSensorSpeedJu 1 "NOT_OK" 0 "OK" ;
VAL_ 1470 IDB_a017_wheelSpeedSensorSp_0001 1 "NOT_OK" 0 "OK" ;
VAL_ 1470 IDB_a017_wheelSpeedSensorAirGap 1 "NOT_OK" 0 "OK" ;
VAL_ 1470 IDB_a017_wheelSpeedSensorBIST 1 "NOT_OK" 0 "OK" ;
VAL_ 1470 IDB_a017_wheelSpeedSensorLeakage 1 "NOT_OK" 0 "OK" ;
VAL_ 1470 IDB_a017_wheelSpeedSensorOverTem 1 "NOT_OK" 0 "OK" ;
VAL_ 1470 IDB_a017_wheelSpeedSensorSh_0001 1 "NOT_OK" 0 "OK" ;
VAL_ 1470 IDB_a017_wheelSpeedSensorShortTo 1 "NOT_OK" 0 "OK" ;
VAL_ 1470 IDB_a017_wheelSpeedSensorOpen 1 "NOT_OK" 0 "OK" ;
VAL_ 1470 IDB_a020_canSignalValidity 1 "NOT_OK" 0 "OK" ;
VAL_ 1470 IDB_a020_signalValueCrosscheck 1 "NOT_OK" 0 "OK" ;
VAL_ 1470 IDB_a030_primaryExternalCircuitL 1 "NOT_OK" 0 "OK" ;
VAL_ 1470 IDB_a030_secondaryExternalCircui 1 "NOT_OK" 0 "OK" ;
VAL_ 1470 IDB_a030_primaryChamberInternalL 1 "NOT_OK" 0 "OK" ;
VAL_ 1470 IDB_a030_syncModeInternalLeakage 1 "NOT_OK" 0 "OK" ;
VAL_ 1470 IDB_a030_secondaryChamberInterna 1 "NOT_OK" 0 "OK" ;
VAL_ 1470 IDB_a030_masterCylinderInternalL 1 "NOT_OK" 0 "OK" ;
VAL_ 1470 IDB_a060_validityOnChassisBus 1 "NOT_OK" 0 "OK" ;
VAL_ 1470 IDB_a060_validityOnPartyBus 1 "NOT_OK" 0 "OK" ;
VAL_ 1470 IDB_a061_validityOnChassisBus 1 "NOT_OK" 0 "OK" ;
VAL_ 1470 IDB_a061_validityOnPartyBus 1 "NOT_OK" 0 "OK" ;
VAL_ 1470 IDB_a062_validityOnChassisBus 1 "NOT_OK" 0 "OK" ;
VAL_ 1470 IDB_a062_validityOnPartyBus 1 "NOT_OK" 0 "OK" ;
VAL_ 1470 IDB_a063_validityOnChassisBus 1 "NOT_OK" 0 "OK" ;
VAL_ 1470 IDB_a063_validityOnPartyBus 1 "NOT_OK" 0 "OK" ;
VAL_ 1470 IDB_a064_validityOnChassisBus 1 "NOT_OK" 0 "OK" ;
VAL_ 1470 IDB_a064_validityOnPartyBus 1 "NOT_OK" 0 "OK" ;
VAL_ 1470 IDB_a065_validityOnChassisBus 1 "NOT_OK" 0 "OK" ;
VAL_ 1470 IDB_a065_validityOnPartyBus 1 "NOT_OK" 0 "OK" ;
VAL_ 1470 IDB_a106_qualifierValidity 1 "NOT_OK" 0 "OK" ;
VAL_ 1470 IDB_a106_signalNotAvailable 1 "NOT_OK" 0 "OK" ;
VAL_ 1470 IDB_a107_qualifierValidity 1 "NOT_OK" 0 "OK" ;
VAL_ 1470 IDB_a107_signalNotAvailable 1 "NOT_OK" 0 "OK" ;
VAL_ 1470 IDB_a112_qualifierValidity 1 "NOT_OK" 0 "OK" ;
VAL_ 1470 IDB_a112_signalNotAvailable 1 "NOT_OK" 0 "OK" ;
VAL_ 1470 IDB_a113_qualifierValidity 1 "NOT_OK" 0 "OK" ;
VAL_ 1470 IDB_a113_signalNotAvailable 1 "NOT_OK" 0 "OK" ;
VAL_ 1470 IDB_a114_qualifierValidity 1 "NOT_OK" 0 "OK" ;
VAL_ 1470 IDB_a114_signalNotAvailable 1 "NOT_OK" 0 "OK" ;
VAL_ 1470 IDB_a126_PMebrCmdStateValidity 1 "NOT_OK" 0 "OK" ;
VAL_ 1470 IDB_a126_PMstate2Validity 1 "NOT_OK" 0 "OK" ;
VAL_ 1470 IDB_a126_PMstate2Missing 1 "NOT_OK" 0 "OK" ;
VAL_ 1470 IDB_a126_DIchassisControlValidit 1 "NOT_OK" 0 "OK" ;
VAL_ 1470 IDB_a126_DIchassisControlMissing 1 "NOT_OK" 0 "OK" ;
VAL_ 1470 IDB_a126_DIrequestActiveValidity 1 "NOT_OK" 0 "OK" ;
VAL_ 1470 IDB_a129_validityOnChassisBus 1 "NOT_OK" 0 "OK" ;
VAL_ 1470 IDB_a129_validityOnPartyBus 1 "NOT_OK" 0 "OK" ;
VAL_ 1470 IDB_a130_PMbrakePedalCmdQFValidi 1 "NOT_OK" 0 "OK" ;
VAL_ 1470 IDB_a130_PMstate2Validity 1 "NOT_OK" 0 "OK" ;
VAL_ 1470 IDB_a130_PMstate2Missing 1 "NOT_OK" 0 "OK" ;
VAL_ 1470 IDB_a130_DIbrakeCommandValidity 1 "NOT_OK" 0 "OK" ;
VAL_ 1470 IDB_a130_DIbrakeCommandMissing 1 "NOT_OK" 0 "OK" ;
VAL_ 1470 IDB_a130_DIbrakeTorqueCommandFul 1 "NOT_OK" 0 "OK" ;
VAL_ 1470 IDB_a130_DIbrakeTorqueComma_0001 1 "NOT_OK" 0 "OK" ;
VAL_ 1470 IDB_a132_validityOnChassisBus 1 "NOT_OK" 0 "OK" ;
VAL_ 1470 IDB_a132_validityOnPartyBus 1 "NOT_OK" 0 "OK" ;
VAL_ 983 IDB_matrixIndex 2 "AlertMatrix2" 1 "AlertMatrix1" 0 "AlertMatrix0" ;
VAL_ 828 IDB_infoIndex 255 "END" 31 "SUBCOMPONENT_GITHASH" 30 "PACKAGE_SN_8_14" 29 "PACKAGE_SN_1_7" 27 "PACKAGE_PN_15_20" 26 "PACKAGE_PN_8_14" 25 "PACKAGE_PN_1_7" 23 "SUBCOMPONENT2" 22 "VARIANTCRC" 20 "UDS_PROTOCOL_BOOTCRC" 19 "VERSION_DEPRECATED" 18 "BOOTLOADER_GITHASH" 17 "APP_GITHASH" 16 "SUBCOMPONENT" 15 "BOOTLOADER_CRC" 14 "BOOTLOADER_SVN" 13 "APP_CRC" 11 "PCBAID_ASSYID_USAGEID" 10 "BUILD_HWID_COMPONENTID" 9 "DEPRECATED_9" 8 "DEPRECATED_8" 7 "DEPRECATED_7" 6 "DEPRECATED_6" 5 "DEPRECATED_5" 4 "DEPRECATED_4" 3 "DEPRECATED_3" 2 "DEPRECATED_2" 1 "DEPRECATED_1" 0 "DEPRECATED_0" ;
VAL_ 1429 OCS1P_alertID 155 "a155_rbExit2Exited2" 154 "a154_rbExit2Exited1" 153 "a153_rbExit1Exited" 152 "a152_rbExit1Triggered" 151 "a151_rbEntryExited" 150 "a150_rbEntryTriggered" 148 "a148_classificationMismatch" 145 "a145_rebaselineTriggered" 144 "a144_mismatchCarRegion" 143 "a143_mismatchPassAirbag" 142 "a142_tempHumidityInvalid" 141 "a141_humidityInvalidCalib" 140 "a140_tempInvalidCalib" 139 "a139_seatbackSelfDutyHigh" 138 "a138_seatbackSelfDutyLow" 137 "a137_cushionSelfDutyHigh" 136 "a136_cushionSelfDutyLow" 135 "a135_tempNoCalib" 134 "a134_uninitializedCalib" 133 "a133_sandwichBadCalib" 132 "a132_seatbackSelfNoCalib" 131 "a131_cushionSelfNoCalib" 130 "a130_sandwichNoCalib" 129 "a129_seatbackSelfShort" 128 "a128_seatbackSelfLow" 127 "a127_seatbackSelfOpen" 126 "a126_cushionSelfShort" 125 "a125_cushionSelfLow" 124 "a124_cushionSelfOpen" 123 "a123_sandwichShort" 122 "a122_sandwichLow" 121 "a121_sandwichOpen" 15 "a015_NVMMAlert" 0 "ALERT_DO_NOT_USE_ZERO" ;
VAL_ 1429 OCS1P_alertState 1 "SET" 0 "CLEARED" ;
VAL_ 767 OCS1P_matrixIndex 2 "AlertMatrix2" 0 "AlertMatrix0" ;
VAL_ 766 OCS1P_infoIndex 20 "Mux20" 19 "Mux19" 18 "Mux18" 17 "Mux17" 14 "Mux14" 13 "Mux13" 11 "Mux11" 10 "Mux10" ;
VAL_ 766 OCS1P_infoBuildType 4 "INFO_MFG_BUILD" 3 "INFO_TRACEABLE_CI_BUILD" 2 "INFO_LOCAL_BUILD" 1 "INFO_PLATFORM_BUILD" 0 "INFO_UNKNOWN_BUILD" ;
VAL_ 771 OCS1P_occupantClassification 255 "OCCUPANT_CLASSIFICATION_SNA" 4 "OCCUPANT_CLASSIFICATION_INIT" 3 "OCCUPANT_CLASSIFICATION_OCCUPIED_ALLOW_LARGE" 2 "OCCUPANT_CLASSIFICATION_OCCUPIED_ALLOW_SMALL" 1 "OCCUPANT_CLASSIFICATION_OCCUPIED_INHIBIT" 0 "OCCUPANT_CLASSIFICATION_EMPTY" ;
VAL_ 771 OCS1P_occupantClassificationQF 1 "OCCUPANT_CLASSIFICATION_NOT_FAULTED" 0 "OCCUPANT_CLASSIFICATION_FAULTED" ;
VAL_ 771 OCS1P_occupiedState 3 "OCCUPIED_STATE_SNA" 1 "OCCUPIED_STATE_OCCUPIED" 0 "OCCUPIED_STATE_UNOCCUPIED" ;
VAL_ 771 OCS1P_triggerSnapshot 19 "REASON_LCB_TOO_HIGH" 18 "REASON_SWITCHED_TO_HCB" 17 "REASON_LARGE_REBASELINE" 16 "REASON_BORDERLINE_CLASSIFICATION" 15 "REASON_MISSED_EXIT_EVENT" 14 "REASON_MISSED_ENTRY_EVENT" 13 "REASON_EMPTY_CONFIDENT_EXITED" 12 "REASON_EMPTY_CONFIDENT_REBASELINED" 11 "REASON_EXIT_REBASELINED" 10 "REASON_EXIT_FAILED" 9 "REASON_EXIT_TRIGGERED" 8 "REASON_ENTRY_REBASELINED" 7 "REASON_ENTRY_FAILED" 6 "REASON_ENTRY_TRIGGERED" 5 "REASON_SENSOR_LOW_SHORT" 4 "REASON_SENSOR_OPEN" 3 "REASON_SANDWICH_LOW" 2 "REASON_REBASELINED" 1 "REASON_MISMATCH" 0 "REASON_NONE" ;
VAL_ 771 OCS1P_occupantClassificationRaw 7 "OCCUPANT_CLASSIFICATION_SNA" 4 "OCCUPANT_CLASSIFICATION_INIT" 3 "OCCUPANT_CLASSIFICATION_OCCUPIED_ALLOW_LARGE" 2 "OCCUPANT_CLASSIFICATION_OCCUPIED_ALLOW_SMALL" 1 "OCCUPANT_CLASSIFICATION_OCCUPIED_INHIBIT" 0 "OCCUPANT_CLASSIFICATION_EMPTY" ;
VAL_ 771 OCS1P_occupantClassificationSelf 7 "OCCUPANT_CLASSIFICATION_SNA" 4 "OCCUPANT_CLASSIFICATION_INIT" 3 "OCCUPANT_CLASSIFICATION_OCCUPIED_ALLOW_LARGE" 2 "OCCUPANT_CLASSIFICATION_OCCUPIED_ALLOW_SMALL" 1 "OCCUPANT_CLASSIFICATION_OCCUPIED_INHIBIT" 0 "OCCUPANT_CLASSIFICATION_EMPTY" ;
VAL_ 771 OCS1P_occupantClassificationRawC 7 "OCCUPANT_CLASSIFICATION_SNA" 4 "OCCUPANT_CLASSIFICATION_INIT" 3 "OCCUPANT_CLASSIFICATION_OCCUPIED_ALLOW_LARGE" 2 "OCCUPANT_CLASSIFICATION_OCCUPIED_ALLOW_SMALL" 1 "OCCUPANT_CLASSIFICATION_OCCUPIED_INHIBIT" 0 "OCCUPANT_CLASSIFICATION_EMPTY" ;
VAL_ 771 OCS1P_occupantClassificationCap 7 "OCCUPANT_CLASSIFICATION_SNA" 4 "OCCUPANT_CLASSIFICATION_INIT" 3 "OCCUPANT_CLASSIFICATION_OCCUPIED_ALLOW_LARGE" 2 "OCCUPANT_CLASSIFICATION_OCCUPIED_ALLOW_SMALL" 1 "OCCUPANT_CLASSIFICATION_OCCUPIED_INHIBIT" 0 "OCCUPANT_CLASSIFICATION_EMPTY" ;
VAL_ 771 OCS1P_classificationHoldState 3 "OCCUPANCY_HOLD_FAULT" 2 "OCCUPANCY_HOLD_EXTERNAL" 1 "OCCUPANCY_HOLD_BASIC" 0 "OCCUPANCY_HOLD_OFF" ;
VAL_ 771 OCS1P_classificationVariant 7 "CLASSIFICATION_VARIANT_UNKNOWN" 3 "CLASSIFICATION_VARIANT_SELF_SBR_RB" 2 "CLASSIFICATION_VARIANT_SELF_SBR" 1 "CLASSIFICATION_VARIANT_SELF_ONLY" 0 "CLASSIFICATION_VARIANT_ALL_SENSORS" ;
VAL_ 771 OCS1P_noSandwichType 3 "NO_SANDWICH_UNKNOWN" 2 "NO_SANDWICH_NA" 1 "NO_SANDWICH_EU" 0 "SANDWICH_INSTALLED" ;
VAL_ 771 OCS1P_sandwichBoundaryType 1 "SANDWICH_LRD" 0 "SANDWICH_DEFAULT" ;
VAL_ 771 OCS1P_sbrBoundaryType 1 "SBR_1669747_1763884" 0 "SBR_DEFAULT" ;
VAL_ 771 OCS1P_occupiedStateCap 3 "OCCUPIED_STATE_SNA" 1 "OCCUPIED_STATE_OCCUPIED" 0 "OCCUPIED_STATE_UNOCCUPIED" ;
